BU_:  Airbag BAP_Tester ICAS1_Gateway ICAS1_KommunikationsServer LE1 LE2 Motor_BEV Schaltbetaetigung

BU_:  Airbag BAP_Tester ICAS1_Gateway ICAS1_KommunikationsServer LE1 LE2 Motor_BEV Schaltbetaetigung

BO_ 2463978709 OCC_02: 32 ICAS1_Gateway
 SG_ OCC_CP_Tastgrad_A  : 12|10@1+ (0.100000,0.000000) [0.000000|100.000000] "Unit_PerCent" Vector__XXX
 SG_ OCC_CP_Tastgrad_B  : 22|10@1+ (0.100000,0.000000) [0.000000|100.000000] "Unit_PerCent" Vector__XXX
 SG_ OCC_CP_Frequenz_A  : 32|8@1+ (1.000000,880.000000) [880.000000|1132.000000] "Unit_Hertz" Vector__XXX
 SG_ OCC_CP_Frequenz_B  : 40|8@1+ (1.000000,880.000000) [880.000000|1132.000000] "Unit_Hertz" Vector__XXX
 SG_ OCC_CP_Spannung_A  : 48|9@1+ (0.100000,-25.000000) [-25.000000|25.900000] "Unit_Volt" Vector__XXX
 SG_ OCC_CP_Spannung_B  : 57|9@1+ (0.100000,-25.000000) [-25.000000|25.900000] "Unit_Volt" Vector__XXX
 SG_ OCC_CP_Fehlerstatus_A  : 66|3@1+ (1.000000,0.000000) [0.000000|7.000000] "" Vector__XXX
 SG_ OCC_CP_Fehlerstatus_B  : 69|3@1+ (1.000000,0.000000) [0.000000|7.000000] "" Vector__XXX
 SG_ OCC_Temp_Ladedose_A_AC  : 72|8@1+ (1.000000,-40.000000) [-40.000000|213.000000] "Unit_DegreCelsi" Vector__XXX
 SG_ OCC_Temp_Ladedose_A_DC_minus  : 80|8@1+ (1.000000,-40.000000) [-40.000000|213.000000] "Unit_DegreCelsi" Vector__XXX
 SG_ OCC_Temp_Ladedose_A_DC_plus  : 88|8@1+ (1.000000,-40.000000) [-40.000000|213.000000] "Unit_DegreCelsi" Vector__XXX
 SG_ OCC_U_istAC_Netz_L1  : 96|9@1+ (1.000000,0.000000) [0.000000|509.000000] "Unit_Volt" Vector__XXX
 SG_ OCC_U_istAC_Netz_L2  : 105|9@1+ (1.000000,0.000000) [0.000000|509.000000] "Unit_Volt" Vector__XXX
 SG_ OCC_U_istAC_Netz_L3  : 114|9@1+ (1.000000,0.000000) [0.000000|508.000000] "Unit_Volt" Vector__XXX
 SG_ OCC_StatusVerEntriegelungAktor_A  : 123|3@1+ (1.000000,0.000000) [0.000000|7.000000] "" Vector__XXX
 SG_ OCC_SteckerEntriegelung_Verbot_A  : 126|2@1+ (1.000000,0.000000) [0.000000|3.000000] "" Vector__XXX
 SG_ OCC_StatusVerEntriegelungAktor_B  : 128|3@1+ (1.000000,0.000000) [0.000000|7.000000] "" Vector__XXX
 SG_ OCC_SteckerEntriegelung_Verbot_B  : 131|2@1+ (1.000000,0.000000) [0.000000|3.000000] "" Vector__XXX
 SG_ OCC_Verriegelung_Status_A  : 133|3@1+ (1.000000,0.000000) [0.000000|7.000000] "" Vector__XXX
 SG_ OCC_Verriegelung_Status_B  : 136|3@1+ (1.000000,0.000000) [0.000000|7.000000] "" Vector__XXX
 SG_ OCC_RtmWarnLadeKommunikation  : 139|3@1+ (1.000000,0.000000) [0.000000|7.000000] "" Vector__XXX
 SG_ OCC_Ist_Wirkungsgrad  : 145|7@1+ (1.000000,0.000000) [0.000000|100.000000] "Unit_PerCent" Vector__XXX
 SG_ OCC_PP_Max_Strom_A  : 152|4@1+ (1.000000,0.000000) [0.000000|15.000000] "" Vector__XXX
 SG_ OCC_PP_Max_Strom_B  : 156|4@1+ (1.000000,0.000000) [0.000000|15.000000] "" Vector__XXX
 SG_ OCC_DC_MaxStrom  : 160|11@1+ (0.100000,0.000000) [0.000000|204.500000] "Unit_Amper" Vector__XXX
 SG_ OCC_Derating_Temperatur  : 171|1@1+ (1.000000,0.000000) [0.000000|1.000000] "" Vector__XXX
 SG_ OCC_Fehlerzustand  : 172|1@1+ (1.000000,0.000000) [0.000000|1.000000] "" Vector__XXX
 SG_ OCC_Ladest_Entriegelungs_Verbot  : 173|3@1+ (1.000000,0.000000) [0.000000|7.000000] "" Vector__XXX
 SG_ OCC_Netzfrequenz_EVU  : 176|9@1+ (0.100000,40.000000) [40.000000|80.000000] "Unit_Hertz" Vector__XXX
 SG_ OCC_Warnzustand  : 185|1@1+ (1.000000,0.000000) [0.000000|1.000000] "" Vector__XXX
 SG_ OCC_Kuehltemperatur  : 192|8@1+ (1.000000,-40.000000) [-40.000000|213.000000] "Unit_DegreCelsi" Motor_BEV
 SG_ OCC_PP_Fehlerstatus_A  : 200|4@1+ (1.000000,0.000000) [0.000000|15.000000] "" Vector__XXX
 SG_ OCC_PP_Fehlerstatus_B  : 204|4@1+ (1.000000,0.000000) [0.000000|15.000000] "" Vector__XXX

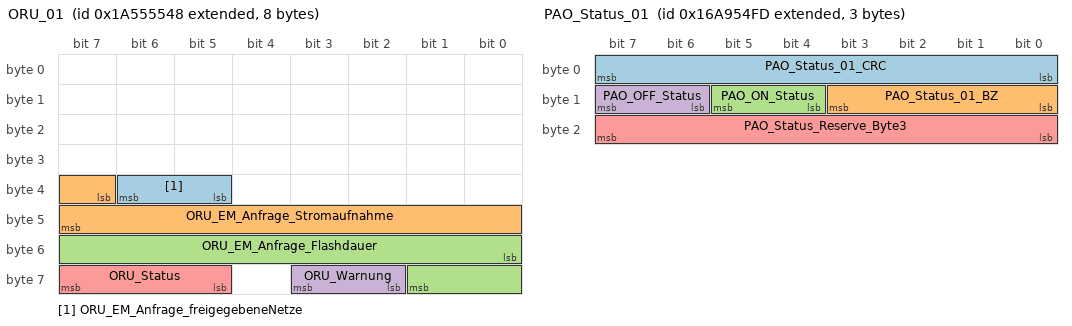
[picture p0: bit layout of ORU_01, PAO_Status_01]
BO_ 2589283656 ORU_01: 8 ICAS1_Gateway
 SG_ ORU_EM_Anfrage_freigegebeneNetze  : 37|2@1+ (1.000000,0.000000) [0.000000|3.000000] "" Vector__XXX
 SG_ ORU_EM_Anfrage_Stromaufnahme  : 39|9@1+ (0.100000,0.000000) [0.000000|51.100000] "Unit_Amper" Vector__XXX
 SG_ ORU_EM_Anfrage_Flashdauer  : 48|10@1+ (10.000000,0.000000) [0.000000|10230.000000] "Unit_Secon" Vector__XXX
 SG_ ORU_Warnung  : 58|2@1+ (1.000000,0.000000) [0.000000|3.000000] "" Vector__XXX
 SG_ ORU_Status  : 61|3@1+ (1.000000,0.000000) [0.000000|7.000000] "" Airbag LE1 LE2 Motor_BEV

BO_ 2527679741 PAO_Status_01: 3 ICAS1_Gateway
 SG_ PAO_Status_01_CRC  : 0|8@1+ (1.000000,0.000000) [0.000000|255.000000] "" Airbag
 SG_ PAO_Status_01_BZ  : 8|4@1+ (1.000000,0.000000) [0.000000|15.000000] "" Airbag
 SG_ PAO_ON_Status  : 12|2@1+ (1.000000,0.000000) [0.000000|3.000000] "" Airbag
 SG_ PAO_OFF_Status  : 14|2@1+ (1.000000,0.000000) [0.000000|3.000000] "" Airbag
 SG_ PAO_Status_Reserve_Byte3  : 16|8@1+ (1.000000,0.000000) [0.000000|255.000000] "" Vector__XXX

BO_ 518 Parken_01: 24 ICAS1_Gateway
 SG_ Parken_BKD_Anf  : 12|4@1+ (0.100000,0.000000) [0.000000|1.300000] "Unit_Secon" Vector__XXX
 SG_ Parken_Verz_Anf  : 16|7@1+ (0.100000,-12.600000) [-12.600000|-0.100000] "Unit_MeterPerSeconSquar" Vector__XXX
 SG_ Parken_Prefill_Anf  : 23|1@1+ (1.000000,0.000000) [0.000000|1.000000] "" Vector__XXX
 SG_ Parken_Warnruck_Anf  : 24|2@1+ (1.000000,0.000000) [0.000000|3.000000] "" Vector__XXX
 SG_ Parken_Verz_Anf_ASIL  : 26|2@1+ (1.000000,0.000000) [0.000000|3.000000] "" Vector__XXX
 SG_ Parken_Warnruckeln_Anf  : 28|2@1+ (1.000000,0.000000) [0.000000|3.000000] "" Vector__XXX
 SG_ Parken_beibehalten  : 30|2@1+ (1.000000,0.000000) [0.000000|3.000000] "" Vector__XXX
 SG_ Parken_Anforderung_HMS  : 32|3@1+ (1.000000,0.000000) [0.000000|7.000000] "" Vector__XXX
 SG_ Parken_Notstopp_Anf  : 40|2@1+ (1.000000,0.000000) [0.000000|3.000000] "" Vector__XXX
 SG_ Parken_Anhalteweg_Anf  : 42|10@1+ (0.010000,0.000000) [0.000000|10.210000] "Unit_Meter" Vector__XXX
 SG_ Parken_aktives_System  : 52|4@1+ (1.000000,0.000000) [0.000000|15.000000] "" Motor_BEV
 SG_ Parken_max_Beschleunigung  : 56|7@1+ (0.100000,-6.000000) [-5.900000|6.100000] "Unit_MeterPerSeconSquar" Motor_BEV
 SG_ Parken_Blinker_li_Anf  : 63|1@1+ (1.000000,0.000000) [0.000000|1.000000] "" Vector__XXX
 SG_ Parken_QFK_KruemmSoll  : 64|15@1+ (0.000007,0.000000) [0.000000|0.219539] "Unit_MeterInver" Vector__XXX
 SG_ Parken_QFK_KruemmSoll_VZ  : 79|1@1+ (1.000000,0.000000) [0.000000|1.000000] "" Vector__XXX
 SG_ Parken_QFK_Spuerb  : 80|8@1+ (0.400000,0.000000) [0.000000|100.000000] "Unit_PerCent" Vector__XXX
 SG_ Parken_QFK_AnfStat  : 88|4@1+ (1.000000,0.000000) [0.000000|15.000000] "" Vector__XXX
 SG_ Parken_QFK_Signal1  : 92|10@1+ (1.000000,0.000000) [0.000000|1023.000000] "" Vector__XXX
 SG_ Parken_QFK_Art1  : 102|3@1+ (1.000000,0.000000) [0.000000|7.000000] "" Vector__XXX
 SG_ Parken_QFK_Art2  : 105|3@1+ (1.000000,0.000000) [0.000000|7.000000] "" Vector__XXX
 SG_ Parken_QFK_Signal2  : 108|10@1+ (1.000000,0.000000) [0.000000|1023.000000] "" Vector__XXX
 SG_ Parken_Sollbeschleunigung  : 118|9@1+ (0.010000,-4.110000) [-4.100000|1.000000] "Unit_MeterPerSeconSquar" Motor_BEV
 SG_ Parken_Blinker_re_Anf  : 127|1@1+ (1.000000,0.000000) [0.000000|1.000000] "" Vector__XXX
 SG_ Parken_Status_IPA_TSK  : 128|4@1+ (1.000000,0.000000) [0.000000|15.000000] "" Motor_BEV
 SG_ Parken_erhoehtes_Moment  : 132|4@1+ (1.000000,0.000000) [0.000000|15.000000] "" Motor_BEV
 SG_ Parken_max_Geschwindigkeit  : 136|8@1+ (0.100000,0.000000) [0.100000|25.000000] "Unit_KiloMeterPerHour" Motor_BEV
 SG_ Parken_Soll_Anhalteweg_Anf  : 144|10@1+ (0.010000,0.000000) [0.000000|10.210000] "Unit_Meter" Vector__XXX
 SG_ Parken_Fahrstufenwunsch  : 154|3@1+ (1.000000,0.000000) [0.000000|7.000000] "" Motor_BEV
 SG_ IPA_TPA_Remote  : 157|2@1+ (1.000000,0.000000) [0.000000|3.000000] "" Vector__XXX
 SG_ IPA_TPA_Remote_Anf  : 159|1@1+ (1.000000,0.000000) [0.000000|1.000000] "" Vector__XXX
 SG_ IPA_TPA_Fehler  : 160|4@1+ (1.000000,0.000000) [0.000000|15.000000] "" Vector__XXX
 SG_ IPA_TPA_Abbruch  : 164|4@1+ (1.000000,0.000000) [0.000000|15.000000] "" Vector__XXX
 SG_ IPA_TPA_Status  : 168|4@1+ (1.000000,0.000000) [0.000000|15.000000] "" Vector__XXX

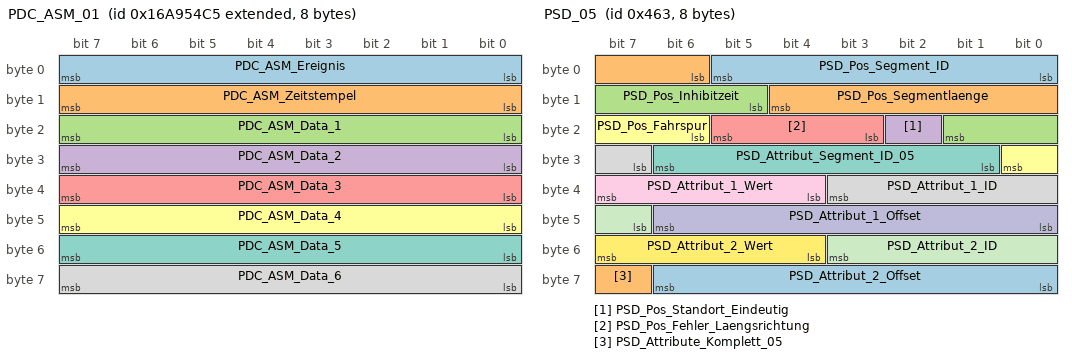
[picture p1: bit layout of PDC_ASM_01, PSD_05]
BO_ 2527679685 PDC_ASM_01: 8 ICAS1_Gateway
 SG_ PDC_ASM_Ereignis  : 0|8@1+ (1.000000,0.000000) [1.000000|254.000000] "" Airbag
 SG_ PDC_ASM_Zeitstempel  : 8|8@1+ (0.080000,0.000000) [0.000000|20.320000] "Unit_Secon" Airbag
 SG_ PDC_ASM_Data_1  : 16|8@1+ (1.000000,0.000000) [0.000000|255.000000] "" Airbag
 SG_ PDC_ASM_Data_2  : 24|8@1+ (1.000000,0.000000) [0.000000|255.000000] "" Airbag
 SG_ PDC_ASM_Data_3  : 32|8@1+ (1.000000,0.000000) [0.000000|255.000000] "" Airbag
 SG_ PDC_ASM_Data_4  : 40|8@1+ (1.000000,0.000000) [0.000000|255.000000] "" Airbag
 SG_ PDC_ASM_Data_5  : 48|8@1+ (1.000000,0.000000) [0.000000|255.000000] "" Airbag
 SG_ PDC_ASM_Data_6  : 56|8@1+ (1.000000,0.000000) [0.000000|255.000000] "" Airbag

BO_ 319 PreCrash_02: 8 Airbag
 SG_ PreCrash_Charisma_FahrPr  : 12|4@1+ (1.000000,0.000000) [0.000000|15.000000] "" ICAS1_Gateway
 SG_ PreCrash_Charisma_Status  : 16|2@1+ (1.000000,0.000000) [0.000000|3.000000] "" ICAS1_Gateway
 SG_ PreCrash_Schiebedach_schliessen  : 18|1@1+ (1.000000,0.000000) [0.000000|1.000000] "" ICAS1_Gateway
 SG_ PreCrash_Fenster_schliessen  : 19|1@1+ (1.000000,0.000000) [0.000000|1.000000] "" ICAS1_Gateway
 SG_ PreCrash_Blinken  : 20|3@1+ (1.000000,0.000000) [0.000000|7.000000] "" ICAS1_Gateway
 SG_ SC_PreSense_FCWP  : 23|1@1+ (1.000000,0.000000) [0.000000|1.000000] "" ICAS1_Gateway
 SG_ PreCrash_Tueren_Verriegeln  : 24|1@1+ (1.000000,0.000000) [0.000000|1.000000] "" ICAS1_Gateway
 SG_ PreCrash_FS_Laengsverstellung  : 25|1@1+ (1.000000,0.000000) [0.000000|1.000000] "" ICAS1_Gateway
 SG_ PreCrash_Anforderung_AFR  : 26|3@1+ (1.000000,0.000000) [0.000000|7.000000] "" ICAS1_Gateway
 SG_ SC_PreCrash_LED  : 29|2@1+ (1.000000,0.000000) [0.000000|3.000000] "" ICAS1_Gateway
 SG_ PreCrash_FS_Pneumatik_ansteuern  : 31|1@1+ (1.000000,0.000000) [0.000000|1.000000] "" ICAS1_Gateway
 SG_ PreCrash_BFS_Pneumatik_ansteuern  : 32|1@1+ (1.000000,0.000000) [0.000000|1.000000] "" ICAS1_Gateway
 SG_ PreCrash_Fo_Pneumatik_ansteuern  : 33|1@1+ (1.000000,0.000000) [0.000000|1.000000] "" ICAS1_Gateway
 SG_ PreCrash_FS_Sitzlehne_verfahren  : 34|3@1+ (1.000000,0.000000) [0.000000|7.000000] "" ICAS1_Gateway
 SG_ PreCrash_BFS_Sitzlehne_verfahren  : 37|3@1+ (1.000000,0.000000) [0.000000|7.000000] "" ICAS1_Gateway
 SG_ PreCrash_Fo_Sitzlehne_verfahren  : 40|3@1+ (1.000000,0.000000) [0.000000|7.000000] "" ICAS1_Gateway
 SG_ PreCrash_FS_KSV_verfahren  : 43|4@1+ (1.000000,0.000000) [0.000000|15.000000] "" ICAS1_Gateway
 SG_ PreCrash_BFS_KSV_verfahren  : 47|4@1+ (1.000000,0.000000) [0.000000|15.000000] "" ICAS1_Gateway
 SG_ PreCrash_Fo_KSV_verfahren  : 51|4@1+ (1.000000,0.000000) [0.000000|15.000000] "" ICAS1_Gateway
 SG_ PreCrash_BFS_Laengsverstellung  : 55|1@1+ (1.000000,0.000000) [0.000000|1.000000] "" ICAS1_Gateway
 SG_ SC_PreCrash_Warnung  : 56|4@1+ (1.000000,0.000000) [0.000000|15.000000] "" ICAS1_Gateway ICAS1_KommunikationsServer
 SG_ SC_PreCrash_Texte  : 60|4@1+ (1.000000,0.000000) [0.000000|15.000000] "" ICAS1_Gateway ICAS1_KommunikationsServer

BO_ 1122 PSD_04: 8 ICAS1_Gateway
 SG_ PSD_Segment_ID  : 0|6@1+ (1.000000,0.000000) [2.000000|63.000000] "" Motor_BEV
 SG_ PSD_Vorgaenger_Segment_ID  : 6|6@1+ (1.000000,0.000000) [2.000000|63.000000] "" Motor_BEV
 SG_ PSD_Segmentlaenge  : 12|7@1+ (2.000000,0.000000) [0.000000|254.000000] "Unit_Meter" Motor_BEV
 SG_ PSD_Strassenkategorie  : 19|3@1+ (1.000000,0.000000) [0.000000|7.000000] "" Motor_BEV
 SG_ PSD_Endkruemmung  : 22|8@1+ (1.000000,0.000000) [0.000000|254.000000] "Unit_None" Motor_BEV
 SG_ PSD_Endkruemmung_Vorz  : 30|1@1+ (1.000000,0.000000) [0.000000|1.000000] "" Motor_BEV
 SG_ PSD_Idenditaets_ID  : 31|6@1+ (1.000000,0.000000) [2.000000|63.000000] "" Vector__XXX
 SG_ PSD_ADAS_Qualitaet  : 37|1@1+ (1.000000,0.000000) [0.000000|1.000000] "" Motor_BEV
 SG_ PSD_wahrscheinlichster_Pfad  : 38|1@1+ (1.000000,0.000000) [0.000000|1.000000] "" Motor_BEV
 SG_ PSD_Geradester_Pfad  : 39|1@1+ (1.000000,0.000000) [0.000000|1.000000] "" Motor_BEV
 SG_ PSD_Fahrspuren_Anzahl  : 40|3@1+ (1.000000,0.000000) [0.000000|7.000000] "" Motor_BEV
 SG_ PSD_Bebauung  : 43|1@1+ (1.000000,0.000000) [0.000000|1.000000] "" Motor_BEV
 SG_ PSD_Segment_Komplett  : 44|1@1+ (1.000000,0.000000) [0.000000|1.000000] "" Motor_BEV
 SG_ PSD_Rampe  : 45|2@1+ (1.000000,0.000000) [0.000000|3.000000] "" Motor_BEV
 SG_ PSD_Anfangskruemmung  : 47|8@1+ (1.000000,0.000000) [0.000000|254.000000] "" Motor_BEV
 SG_ PSD_Anfangskruemmung_Vorz  : 55|1@1+ (1.000000,0.000000) [0.000000|1.000000] "" Motor_BEV
 SG_ PSD_Abzweigerichtung  : 56|1@1+ (1.000000,0.000000) [0.000000|1.000000] "" Motor_BEV
 SG_ PSD_Abzweigewinkel  : 57|7@1+ (1.417323,0.000000) [0.000000|180.000021] "" Motor_BEV

BO_ 1123 PSD_05: 8 ICAS1_Gateway
 SG_ PSD_Pos_Segment_ID  : 0|6@1+ (1.000000,0.000000) [2.000000|63.000000] "" Motor_BEV
 SG_ PSD_Pos_Segmentlaenge  : 6|7@1+ (2.000000,0.000000) [0.000000|254.000000] "Unit_Meter" Motor_BEV
 SG_ PSD_Pos_Inhibitzeit  : 13|5@1+ (10.000000,0.000000) [0.000000|310.000000] "Unit_MilliSecon" Motor_BEV
 SG_ PSD_Pos_Standort_Eindeutig  : 18|1@1+ (1.000000,0.000000) [0.000000|1.000000] "" Motor_BEV
 SG_ PSD_Pos_Fehler_Laengsrichtung  : 19|3@1+ (1.000000,0.000000) [0.000000|7.000000] "" Motor_BEV
 SG_ PSD_Pos_Fahrspur  : 22|3@1+ (1.000000,0.000000) [0.000000|7.000000] "" Motor_BEV
 SG_ PSD_Attribut_Segment_ID_05  : 25|6@1+ (1.000000,0.000000) [2.000000|63.000000] "" Motor_BEV
 SG_ PSD_Attribut_1_ID  : 31|5@1+ (1.000000,0.000000) [1.000000|31.000000] "" Motor_BEV
 SG_ PSD_Attribut_1_Wert  : 36|4@1+ (1.000000,0.000000) [0.000000|15.000000] "" Motor_BEV
 SG_ PSD_Attribut_1_Offset  : 40|7@1+ (2.000000,0.000000) [0.000000|254.000000] "Unit_Meter" Motor_BEV
 SG_ PSD_Attribut_2_ID  : 47|5@1+ (1.000000,0.000000) [1.000000|31.000000] "" Motor_BEV
 SG_ PSD_Attribut_2_Wert  : 52|4@1+ (1.000000,0.000000) [0.000000|15.000000] "" Motor_BEV
 SG_ PSD_Attribut_2_Offset  : 56|7@1+ (2.000000,0.000000) [0.000000|254.000000] "Unit_Meter" Motor_BEV
 SG_ PSD_Attribute_Komplett_05  : 63|1@1+ (1.000000,0.000000) [0.000000|1.000000] "" Motor_BEV

BO_ 1124 PSD_06: 8 ICAS1_Gateway
 SG_ PSD_06_Mux M : 0|3@1+ (1.000000,0.000000) [0.000000|7.000000] "" Motor_BEV
 SG_ PSD_Sys_Segment_ID m0 : 3|6@1+ (1.000000,0.000000) [2.000000|63.000000] "" Motor_BEV
 SG_ PSD_Attribut_Segment_ID m1 : 3|6@1+ (1.000000,0.000000) [2.000000|63.000000] "" Motor_BEV
 SG_ PSD_Ges_Segment_ID m2 : 3|6@1+ (1.000000,0.000000) [2.000000|63.000000] "" Motor_BEV
 SG_ PSD_Baum_Laenge_VZ m3 : 3|1@1+ (1.000000,0.000000) [0.000000|1.000000] "" Motor_BEV
 SG_ PSD_Steigung_1_Segment_ID m4 : 3|6@1+ (1.000000,0.000000) [2.000000|63.000000] "" Motor_BEV
 SG_ PSD_Baum_Laenge m3 : 4|25@1+ (0.000010,0.000000) [0.000000|180.000000] "Unit_DegreOfArc" Motor_BEV
 SG_ PSD_Sys_Laendercode m0 : 9|8@1+ (1.000000,0.000000) [0.000000|255.000000] "" Motor_BEV
 SG_ PSD_Attribut_3_ID m1 : 9|5@1+ (1.000000,0.000000) [1.000000|31.000000] "" Motor_BEV
 SG_ PSD_Ges_Offset m2 : 9|7@1+ (2.000000,0.000000) [0.000000|254.000000] "Unit_Meter" Motor_BEV
 SG_ PSD_Steigung_1_A_Steigung m4 : 9|7@1+ (0.120000,0.000000) [0.000000|15.000000] "Unit_PerCent" Motor_BEV
 SG_ PSD_Attribut_3_Offset m1 : 14|7@1+ (2.000000,0.000000) [0.000000|254.000000] "Unit_Meter" Motor_BEV
 SG_ PSD_Ges_Geschwindigkeit m2 : 16|5@1+ (1.000000,0.000000) [0.000000|31.000000] "" Motor_BEV
 SG_ PSD_Steigung_1_A_Vorz m4 : 16|1@1+ (1.000000,0.000000) [0.000000|1.000000] "" Motor_BEV
 SG_ PSD_Sys_Geschwindigkeit_Einheit m0 : 17|1@1+ (1.000000,0.000000) [0.000000|1.000000] "" Motor_BEV
 SG_ PSD_Steigung_1_A_Offset m4 : 17|7@1+ (2.000000,0.000000) [0.000000|254.000000] "Unit_Meter" Motor_BEV
 SG_ PSD_Sys_Verkehrsrichtung m0 : 18|1@1+ (1.000000,0.000000) [0.000000|1.000000] "" Motor_BEV
 SG_ PSD_Sys_Geometrieguete m0 : 19|2@1+ (1.000000,0.000000) [0.000000|3.000000] "" Motor_BEV
 SG_ PSD_Sys_Mapmatchingguete m0 : 21|2@1+ (1.000000,0.000000) [0.000000|3.000000] "" Motor_BEV
 SG_ PSD_Attribut_3_Wert m1 : 21|4@1+ (1.000000,0.000000) [0.000000|15.000000] "" Motor_BEV
 SG_ PSD_Ges_Typ m2 : 21|2@1+ (1.000000,0.000000) [0.000000|3.000000] "" Motor_BEV
 SG_ PSD_Sys_Alter_Karte m0 : 23|3@1+ (1.000000,0.000000) [0.000000|7.000000] "" Motor_BEV
 SG_ PSD_Ges_Spur_Geschw_Begrenzung m2 : 23|6@1+ (1.000000,0.000000) [0.000000|63.000000] "" Motor_BEV
 SG_ PSD_Steigung_1_B_Steigung m4 : 24|7@1+ (0.120000,0.000000) [0.000000|15.000000] "Unit_PerCent" Motor_BEV
 SG_ PSD_Attribut_4_ID m1 : 25|5@1+ (1.000000,0.000000) [1.000000|31.000000] "" Motor_BEV
 SG_ PSD_Sys_Zielfuehrung m0 : 26|1@1+ (1.000000,0.000000) [0.000000|1.000000] "" Motor_BEV
 SG_ PSD_Sys_US_State m0 : 27|6@1+ (1.000000,0.000000) [0.000000|63.000000] "" Motor_BEV
 SG_ PSD_Ges_Geschwindigkeit_Gespann m2 : 29|2@1+ (1.000000,0.000000) [0.000000|3.000000] "" Motor_BEV
 SG_ PSD_Baum_Breite_VZ m3 : 29|1@1+ (1.000000,0.000000) [0.000000|1.000000] "" Motor_BEV
 SG_ PSD_Attribut_4_Wert m1 : 30|4@1+ (1.000000,0.000000) [0.000000|15.000000] "" Motor_BEV
 SG_ PSD_Baum_Breite m3 : 30|24@1+ (0.000010,0.000000) [0.000000|90.000000] "Unit_DegreOfArc" Motor_BEV
 SG_ PSD_Ges_Geschwindigkeit_Witter m2 : 31|2@1+ (1.000000,0.000000) [0.000000|3.000000] "" Motor_BEV
 SG_ PSD_Steigung_1_B_Vorz m4 : 31|1@1+ (1.000000,0.000000) [0.000000|1.000000] "" Motor_BEV
 SG_ PSD_Steigung_1_B_Offset m4 : 32|7@1+ (2.000000,0.000000) [0.000000|254.000000] "Unit_Meter" Motor_BEV
 SG_ PSD_Sys_Quali_Geometrien m0 : 33|3@1+ (1.000000,0.000000) [0.000000|7.000000] "Unit_None" Vector__XXX
 SG_ PSD_Ges_Geschwindigkeit_Tag_Anf m2 : 33|3@1+ (1.000000,0.000000) [0.000000|7.000000] "" Motor_BEV
 SG_ PSD_Attribut_4_Offset m1 : 34|7@1+ (2.000000,0.000000) [0.000000|254.000000] "Unit_Meter" Motor_BEV
 SG_ PSD_Sys_Quali_Ortsinfo m0 : 36|2@1+ (1.000000,0.000000) [0.000000|3.000000] "Unit_None" Vector__XXX
 SG_ PSD_Ges_Geschwindigkeit_Tag_Ende m2 : 36|3@1+ (1.000000,0.000000) [0.000000|7.000000] "" Motor_BEV
 SG_ PSD_Sys_Quali_verfuegbar m0 : 38|1@1+ (1.000000,0.000000) [0.000000|1.000000] "" Vector__XXX
 SG_ PSD_Sys_Zielfuehrung_geaendert m0 : 39|1@1+ (1.000000,0.000000) [0.000000|1.000000] "" Motor_BEV
 SG_ PSD_Ges_Geschwindigkeit_Std_Anf m2 : 39|5@1+ (1.000000,0.000000) [0.000000|24.000000] "Unit_Hours" Motor_BEV
 SG_ PSD_Steigung_1_Attribute_kompl m4 : 39|1@1+ (1.000000,0.000000) [0.000000|1.000000] "" Motor_BEV
 SG_ PSD_Sys_Geometrieguete_erweitert m0 : 40|8@1+ (1.000000,0.000000) [0.000000|255.000000] "" Vector__XXX
 SG_ PSD_Steigung_2_Segment_ID m4 : 40|6@1+ (1.000000,0.000000) [2.000000|63.000000] "" Motor_BEV
 SG_ PSD_Attribut_5_ID m1 : 41|5@1+ (1.000000,0.000000) [1.000000|31.000000] "" Motor_BEV
 SG_ PSD_Ges_Geschwindigkeit_Std_Ende m2 : 44|5@1+ (1.000000,0.000000) [0.000000|24.000000] "Unit_Hours" Motor_BEV
 SG_ PSD_Attribut_5_Offset m1 : 46|7@1+ (2.000000,0.000000) [0.000000|254.000000] "Unit_Meter" Motor_BEV
 SG_ PSD_Steigung_2_Steigung m4 : 46|7@1+ (0.120000,0.000000) [0.000000|15.000000] "Unit_PerCent" Motor_BEV
 SG_ PSD_Sys_Quali_sonstige_Attribute m0 : 48|3@1+ (1.000000,0.000000) [0.000000|7.000000] "Unit_None" Vector__XXX
 SG_ PSD_Ges_Ueberholverbot m2 : 49|2@1+ (1.000000,0.000000) [0.000000|3.000000] "" Vector__XXX
 SG_ PSD_Sys_Quali_Steigungen m0 : 51|3@1+ (1.000000,0.000000) [0.000000|7.000000] "" Vector__XXX
 SG_ PSD_Ges_Wechselverkehrszeichen m2 : 51|3@1+ (1.000000,0.000000) [0.000000|7.000000] "" Vector__XXX
 SG_ PSD_Attribut_5_Wert m1 : 53|4@1+ (1.000000,0.000000) [0.000000|15.000000] "" Motor_BEV
 SG_ PSD_Steigung_2_Vorz m4 : 53|1@1+ (1.000000,0.000000) [0.000000|1.000000] "" Motor_BEV
 SG_ PSD_Sys_Quali_Strassenkennz m0 : 54|3@1+ (1.000000,0.000000) [0.000000|7.000000] "Unit_None" Vector__XXX
 SG_ PSD_Wechselverkehrszeichen_Typ m2 : 54|2@1+ (1.000000,0.000000) [0.000000|3.000000] "" Vector__XXX
 SG_ PSD_Baum_Ausrichtung m3 : 54|10@1+ (0.351562,0.000000) [0.000000|359.648438] "Unit_DegreOfArc" Vector__XXX
 SG_ PSD_Steigung_2_Offset m4 : 54|7@1+ (2.000000,0.000000) [0.000000|254.000000] "Unit_Meter" Motor_BEV
 SG_ PSD_Ges_Gesetzlich_Kategorie m2 : 56|3@1+ (1.000000,0.000000) [0.000000|7.000000] "" Motor_BEV
 SG_ PSD_Sys_Quali_Tempolimits m0 : 57|3@1+ (1.000000,0.000000) [0.000000|7.000000] "Unit_None" Vector__XXX
 SG_ PSD_Attribute_Komplett_06 m1 : 57|1@1+ (1.000000,0.000000) [0.000000|1.000000] "" Motor_BEV
 SG_ PSD_Ges_Gesetzlich_Zusatz m2 : 59|2@1+ (1.000000,0.000000) [0.000000|3.000000] "" Motor_BEV
 SG_ PSD_Sys_Quali_Vorfahrtsregelung m0 : 60|3@1+ (1.000000,0.000000) [0.000000|7.000000] "Unit_None" Vector__XXX
 SG_ PSD_Ges_Verkehrszeichen_Quelle m2 : 61|2@1+ (1.000000,0.000000) [0.000000|3.000000] "" Motor_BEV
 SG_ PSD_Steigung_2_Attribute_kompl m4 : 61|1@1+ (1.000000,0.000000) [0.000000|1.000000] "" Motor_BEV
 SG_ PSD_Ges_Attribute_Komplett m2 : 63|1@1+ (1.000000,0.000000) [0.000000|1.000000] "" Motor_BEV

BO_ 591 RDR1_Objekte_02: 64 ICAS1_Gateway
 SG_ RDR1_relevanter_Fehler  : 12|1@1+ (1.000000,0.000000) [0.000000|1.000000] "" Motor_BEV
 SG_ RDR1_Blindheit_erkannt  : 13|1@1+ (1.000000,0.000000) [0.000000|1.000000] "" Motor_BEV
 SG_ RDR1_relev_Nichtverfuegbarkeit  : 14|1@1+ (1.000000,0.000000) [0.000000|1.000000] "" Motor_BEV
 SG_ RDR1_Obj_01_Nummer  : 16|6@1+ (1.000000,0.000000) [0.000000|63.000000] "" Vector__XXX
 SG_ RDR1_Obj_02_Nummer  : 22|6@1+ (1.000000,0.000000) [0.000000|63.000000] "" Vector__XXX
 SG_ RDR1_Obj_03_Nummer  : 28|6@1+ (1.000000,0.000000) [0.000000|63.000000] "" Vector__XXX
 SG_ RDR1_Obj_04_Nummer  : 34|6@1+ (1.000000,0.000000) [0.000000|63.000000] "" Vector__XXX
 SG_ RDR1_Obj_05_Nummer  : 40|6@1+ (1.000000,0.000000) [0.000000|63.000000] "" Vector__XXX
 SG_ RDR1_Obj_06_Nummer  : 46|6@1+ (1.000000,0.000000) [0.000000|63.000000] "" Vector__XXX
 SG_ RDR1_Verkehrssinn  : 52|2@1+ (1.000000,0.000000) [0.000000|3.000000] "" Vector__XXX
 SG_ RDR1_Objekte_02_Datenalter  : 54|10@1+ (0.000977,0.000000) [0.000000|0.998047] "Unit_Secon" Vector__XXX
 SG_ RDR1_Obj_01_dx_v  : 64|12@1+ (0.062500,0.000000) [0.000000|255.937500] "Unit_Meter" Motor_BEV
 SG_ RDR1_Obj_01_dy_v  : 76|10@1+ (0.062500,-32.000000) [-32.000000|31.937500] "Unit_Meter" Motor_BEV
 SG_ RDR1_Obj_01_vx_v  : 86|10@1+ (0.250000,-128.000000) [-128.000000|127.750000] "Unit_MeterPerSecon" Motor_BEV
 SG_ RDR1_Obj_02_dx_v  : 96|12@1+ (0.062500,0.000000) [0.000000|255.937500] "Unit_Meter" Vector__XXX
 SG_ RDR1_Obj_02_dy_v  : 108|10@1+ (0.062500,-32.000000) [-32.000000|31.937500] "Unit_Meter" Vector__XXX
 SG_ RDR1_Obj_02_vx_v  : 118|10@1+ (0.250000,-128.000000) [-128.000000|127.750000] "Unit_MeterPerSecon" Vector__XXX
 SG_ RDR1_Obj_03_dx_v  : 128|12@1+ (0.062500,0.000000) [0.000000|255.937500] "Unit_Meter" Vector__XXX
 SG_ RDR1_Obj_03_dy_v  : 140|10@1+ (0.062500,-32.000000) [-32.000000|31.937500] "Unit_Meter" Vector__XXX
 SG_ RDR1_Obj_03_vx_v  : 150|10@1+ (0.250000,-128.000000) [-128.000000|127.750000] "Unit_MeterPerSecon" Vector__XXX
 SG_ RDR1_Obj_04_dx_v  : 160|12@1+ (0.062500,0.000000) [0.000000|255.937500] "Unit_Meter" Motor_BEV
 SG_ RDR1_Obj_04_dy_v  : 172|10@1+ (0.062500,-32.000000) [-32.000000|31.937500] "Unit_Meter" Vector__XXX
 SG_ RDR1_Obj_04_vx_v  : 182|10@1+ (0.250000,-128.000000) [-128.000000|127.750000] "Unit_MeterPerSecon" Motor_BEV
 SG_ RDR1_Obj_05_dx_v  : 192|12@1+ (0.062500,0.000000) [0.000000|255.937500] "Unit_Meter" Vector__XXX
 SG_ RDR1_Obj_05_dy_v  : 204|10@1+ (0.062500,-32.000000) [-32.000000|31.937500] "Unit_Meter" Vector__XXX
 SG_ RDR1_Obj_05_vx_v  : 214|10@1+ (0.250000,-128.000000) [-128.000000|127.750000] "Unit_MeterPerSecon" Vector__XXX
 SG_ RDR1_Obj_06_dx_v  : 224|12@1+ (0.062500,0.000000) [0.000000|255.937500] "Unit_Meter" Vector__XXX
 SG_ RDR1_Obj_06_dy_v  : 236|10@1+ (0.062500,-32.000000) [-32.000000|31.937500] "Unit_Meter" Vector__XXX
 SG_ RDR1_Obj_06_vx_v  : 246|10@1+ (0.250000,-128.000000) [-128.000000|127.750000] "Unit_MeterPerSecon" Vector__XXX
 SG_ RDR1_Obj_01_ax_v  : 256|8@1+ (0.125000,-16.000000) [-16.000000|15.750000] "Unit_MeterPerSeconSquar" Motor_BEV
 SG_ RDR1_Obj_01_ax_StdA  : 264|6@1+ (0.125000,0.000000) [0.000000|7.750000] "Unit_MeterPerSeconSquar" Motor_BEV
 SG_ RDR1_Obj_01_vx_StdA  : 270|7@1+ (0.031250,0.000000) [0.000000|3.937500] "Unit_MeterPerSecon" Motor_BEV
 SG_ RDR1_Obj_01_dx_StdA  : 277|7@1+ (0.050000,0.000000) [0.000000|6.300000] "Unit_Meter" Motor_BEV
 SG_ RDR1_Obj_01_dy_StdA  : 284|7@1+ (0.062500,0.000000) [0.000000|7.875000] "Unit_Meter" Motor_BEV

BO_ 2033 Request_Airbag_Deployment: 8 ICAS1_Gateway
 SG_ Request_Airbag_Deployment  : 0|64@1+ (1.000000,0.000000) [0.000000|18446744073709551616.000000] "" Airbag

BO_ 2041 Response_Airbag_Deployment: 8 Airbag
 SG_ Response_Airbag_Deployment  : 0|64@1+ (1.000000,0.000000) [0.000000|18446744073709551616.000000] "" ICAS1_Gateway

BU_:  Airbag BAP_Tester ICAS1_Gateway ICAS1_KommunikationsServer LE1 LE2 Motor_BEV Schaltbetaetigung

BO_ 2463978709 OCC_02: 32 ICAS1_Gateway
 SG_ OCC_CP_Tastgrad_A  : 12|10@1+ (0.100000,0.000000) [0.000000|100.000000] "Unit_PerCent" Vector__XXX
 SG_ OCC_CP_Tastgrad_B  : 22|10@1+ (0.100000,0.000000) [0.000000|100.000000] "Unit_PerCent" Vector__XXX
 SG_ OCC_CP_Frequenz_A  : 32|8@1+ (1.000000,880.000000) [880.000000|1132.000000] "Unit_Hertz" Vector__XXX
 SG_ OCC_CP_Frequenz_B  : 40|8@1+ (1.000000,880.000000) [880.000000|1132.000000] "Unit_Hertz" Vector__XXX
 SG_ OCC_CP_Spannung_A  : 48|9@1+ (0.100000,-25.000000) [-25.000000|25.900000] "Unit_Volt" Vector__XXX
 SG_ OCC_CP_Spannung_B  : 57|9@1+ (0.100000,-25.000000) [-25.000000|25.900000] "Unit_Volt" Vector__XXX
 SG_ OCC_CP_Fehlerstatus_A  : 66|3@1+ (1.000000,0.000000) [0.000000|7.000000] "" Vector__XXX
 SG_ OCC_CP_Fehlerstatus_B  : 69|3@1+ (1.000000,0.000000) [0.000000|7.000000] "" Vector__XXX
 SG_ OCC_Temp_Ladedose_A_AC  : 72|8@1+ (1.000000,-40.000000) [-40.000000|213.000000] "Unit_DegreCelsi" Vector__XXX
 SG_ OCC_Temp_Ladedose_A_DC_minus  : 80|8@1+ (1.000000,-40.000000) [-40.000000|213.000000] "Unit_DegreCelsi" Vector__XXX
 SG_ OCC_Temp_Ladedose_A_DC_plus  : 88|8@1+ (1.000000,-40.000000) [-40.000000|213.000000] "Unit_DegreCelsi" Vector__XXX
 SG_ OCC_U_istAC_Netz_L1  : 96|9@1+ (1.000000,0.000000) [0.000000|509.000000] "Unit_Volt" Vector__XXX
 SG_ OCC_U_istAC_Netz_L2  : 105|9@1+ (1.000000,0.000000) [0.000000|509.000000] "Unit_Volt" Vector__XXX
 SG_ OCC_U_istAC_Netz_L3  : 114|9@1+ (1.000000,0.000000) [0.000000|508.000000] "Unit_Volt" Vector__XXX
 SG_ OCC_StatusVerEntriegelungAktor_A  : 123|3@1+ (1.000000,0.000000) [0.000000|7.000000] "" Vector__XXX
 SG_ OCC_SteckerEntriegelung_Verbot_A  : 126|2@1+ (1.000000,0.000000) [0.000000|3.000000] "" Vector__XXX
 SG_ OCC_StatusVerEntriegelungAktor_B  : 128|3@1+ (1.000000,0.000000) [0.000000|7.000000] "" Vector__XXX
 SG_ OCC_SteckerEntriegelung_Verbot_B  : 131|2@1+ (1.000000,0.000000) [0.000000|3.000000] "" Vector__XXX
 SG_ OCC_Verriegelung_Status_A  : 133|3@1+ (1.000000,0.000000) [0.000000|7.000000] "" Vector__XXX
 SG_ OCC_Verriegelung_Status_B  : 136|3@1+ (1.000000,0.000000) [0.000000|7.000000] "" Vector__XXX
 SG_ OCC_RtmWarnLadeKommunikation  : 139|3@1+ (1.000000,0.000000) [0.000000|7.000000] "" Vector__XXX
 SG_ OCC_Ist_Wirkungsgrad  : 145|7@1+ (1.000000,0.000000) [0.000000|100.000000] "Unit_PerCent" Vector__XXX
 SG_ OCC_PP_Max_Strom_A  : 152|4@1+ (1.000000,0.000000) [0.000000|15.000000] "" Vector__XXX
 SG_ OCC_PP_Max_Strom_B  : 156|4@1+ (1.000000,0.000000) [0.000000|15.000000] "" Vector__XXX
 SG_ OCC_DC_MaxStrom  : 160|11@1+ (0.100000,0.000000) [0.000000|204.500000] "Unit_Amper" Vector__XXX
 SG_ OCC_Derating_Temperatur  : 171|1@1+ (1.000000,0.000000) [0.000000|1.000000] "" Vector__XXX
 SG_ OCC_Fehlerzustand  : 172|1@1+ (1.000000,0.000000) [0.000000|1.000000] "" Vector__XXX
 SG_ OCC_Ladest_Entriegelungs_Verbot  : 173|3@1+ (1.000000,0.000000) [0.000000|7.000000] "" Vector__XXX
 SG_ OCC_Netzfrequenz_EVU  : 176|9@1+ (0.100000,40.000000) [40.000000|80.000000] "Unit_Hertz" Vector__XXX
 SG_ OCC_Warnzustand  : 185|1@1+ (1.000000,0.000000) [0.000000|1.000000] "" Vector__XXX
 SG_ OCC_Kuehltemperatur  : 192|8@1+ (1.000000,-40.000000) [-40.000000|213.000000] "Unit_DegreCelsi" Motor_BEV
 SG_ OCC_PP_Fehlerstatus_A  : 200|4@1+ (1.000000,0.000000) [0.000000|15.000000] "" Vector__XXX
 SG_ OCC_PP_Fehlerstatus_B  : 204|4@1+ (1.000000,0.000000) [0.000000|15.000000] "" Vector__XXX

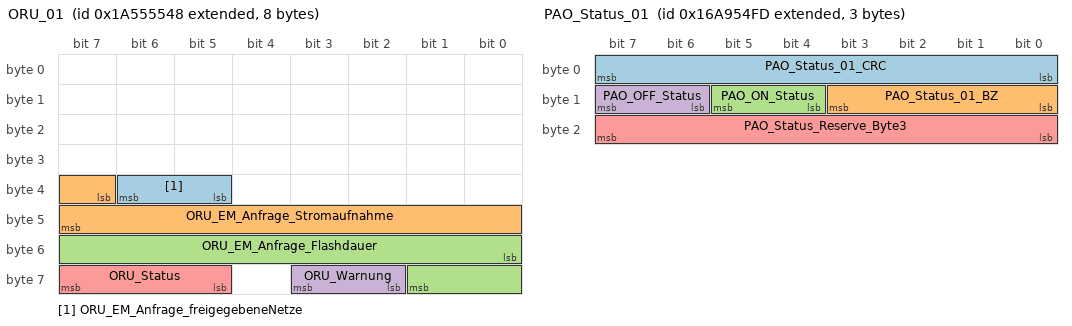
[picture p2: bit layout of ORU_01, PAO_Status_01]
BO_ 2589283656 ORU_01: 8 ICAS1_Gateway
 SG_ ORU_EM_Anfrage_freigegebeneNetze  : 37|2@1+ (1.000000,0.000000) [0.000000|3.000000] "" Vector__XXX
 SG_ ORU_EM_Anfrage_Stromaufnahme  : 39|9@1+ (0.100000,0.000000) [0.000000|51.100000] "Unit_Amper" Vector__XXX
 SG_ ORU_EM_Anfrage_Flashdauer  : 48|10@1+ (10.000000,0.000000) [0.000000|10230.000000] "Unit_Secon" Vector__XXX
 SG_ ORU_Warnung  : 58|2@1+ (1.000000,0.000000) [0.000000|3.000000] "" Vector__XXX
 SG_ ORU_Status  : 61|3@1+ (1.000000,0.000000) [0.000000|7.000000] "" Airbag LE1 LE2 Motor_BEV

BO_ 2527679741 PAO_Status_01: 3 ICAS1_Gateway
 SG_ PAO_Status_01_CRC  : 0|8@1+ (1.000000,0.000000) [0.000000|255.000000] "" Airbag
 SG_ PAO_Status_01_BZ  : 8|4@1+ (1.000000,0.000000) [0.000000|15.000000] "" Airbag
 SG_ PAO_ON_Status  : 12|2@1+ (1.000000,0.000000) [0.000000|3.000000] "" Airbag
 SG_ PAO_OFF_Status  : 14|2@1+ (1.000000,0.000000) [0.000000|3.000000] "" Airbag
 SG_ PAO_Status_Reserve_Byte3  : 16|8@1+ (1.000000,0.000000) [0.000000|255.000000] "" Vector__XXX

BO_ 518 Parken_01: 24 ICAS1_Gateway
 SG_ Parken_BKD_Anf  : 12|4@1+ (0.100000,0.000000) [0.000000|1.300000] "Unit_Secon" Vector__XXX
 SG_ Parken_Verz_Anf  : 16|7@1+ (0.100000,-12.600000) [-12.600000|-0.100000] "Unit_MeterPerSeconSquar" Vector__XXX
 SG_ Parken_Prefill_Anf  : 23|1@1+ (1.000000,0.000000) [0.000000|1.000000] "" Vector__XXX
 SG_ Parken_Warnruck_Anf  : 24|2@1+ (1.000000,0.000000) [0.000000|3.000000] "" Vector__XXX
 SG_ Parken_Verz_Anf_ASIL  : 26|2@1+ (1.000000,0.000000) [0.000000|3.000000] "" Vector__XXX
 SG_ Parken_Warnruckeln_Anf  : 28|2@1+ (1.000000,0.000000) [0.000000|3.000000] "" Vector__XXX
 SG_ Parken_beibehalten  : 30|2@1+ (1.000000,0.000000) [0.000000|3.000000] "" Vector__XXX
 SG_ Parken_Anforderung_HMS  : 32|3@1+ (1.000000,0.000000) [0.000000|7.000000] "" Vector__XXX
 SG_ Parken_Notstopp_Anf  : 40|2@1+ (1.000000,0.000000) [0.000000|3.000000] "" Vector__XXX
 SG_ Parken_Anhalteweg_Anf  : 42|10@1+ (0.010000,0.000000) [0.000000|10.210000] "Unit_Meter" Vector__XXX
 SG_ Parken_aktives_System  : 52|4@1+ (1.000000,0.000000) [0.000000|15.000000] "" Motor_BEV
 SG_ Parken_max_Beschleunigung  : 56|7@1+ (0.100000,-6.000000) [-5.900000|6.100000] "Unit_MeterPerSeconSquar" Motor_BEV
 SG_ Parken_Blinker_li_Anf  : 63|1@1+ (1.000000,0.000000) [0.000000|1.000000] "" Vector__XXX
 SG_ Parken_QFK_KruemmSoll  : 64|15@1+ (0.000007,0.000000) [0.000000|0.219539] "Unit_MeterInver" Vector__XXX
 SG_ Parken_QFK_KruemmSoll_VZ  : 79|1@1+ (1.000000,0.000000) [0.000000|1.000000] "" Vector__XXX
 SG_ Parken_QFK_Spuerb  : 80|8@1+ (0.400000,0.000000) [0.000000|100.000000] "Unit_PerCent" Vector__XXX
 SG_ Parken_QFK_AnfStat  : 88|4@1+ (1.000000,0.000000) [0.000000|15.000000] "" Vector__XXX
 SG_ Parken_QFK_Signal1  : 92|10@1+ (1.000000,0.000000) [0.000000|1023.000000] "" Vector__XXX
 SG_ Parken_QFK_Art1  : 102|3@1+ (1.000000,0.000000) [0.000000|7.000000] "" Vector__XXX
 SG_ Parken_QFK_Art2  : 105|3@1+ (1.000000,0.000000) [0.000000|7.000000] "" Vector__XXX
 SG_ Parken_QFK_Signal2  : 108|10@1+ (1.000000,0.000000) [0.000000|1023.000000] "" Vector__XXX
 SG_ Parken_Sollbeschleunigung  : 118|9@1+ (0.010000,-4.110000) [-4.100000|1.000000] "Unit_MeterPerSeconSquar" Motor_BEV
 SG_ Parken_Blinker_re_Anf  : 127|1@1+ (1.000000,0.000000) [0.000000|1.000000] "" Vector__XXX
 SG_ Parken_Status_IPA_TSK  : 128|4@1+ (1.000000,0.000000) [0.000000|15.000000] "" Motor_BEV
 SG_ Parken_erhoehtes_Moment  : 132|4@1+ (1.000000,0.000000) [0.000000|15.000000] "" Motor_BEV
 SG_ Parken_max_Geschwindigkeit  : 136|8@1+ (0.100000,0.000000) [0.100000|25.000000] "Unit_KiloMeterPerHour" Motor_BEV
 SG_ Parken_Soll_Anhalteweg_Anf  : 144|10@1+ (0.010000,0.000000) [0.000000|10.210000] "Unit_Meter" Vector__XXX
 SG_ Parken_Fahrstufenwunsch  : 154|3@1+ (1.000000,0.000000) [0.000000|7.000000] "" Motor_BEV
 SG_ IPA_TPA_Remote  : 157|2@1+ (1.000000,0.000000) [0.000000|3.000000] "" Vector__XXX
 SG_ IPA_TPA_Remote_Anf  : 159|1@1+ (1.000000,0.000000) [0.000000|1.000000] "" Vector__XXX
 SG_ IPA_TPA_Fehler  : 160|4@1+ (1.000000,0.000000) [0.000000|15.000000] "" Vector__XXX
 SG_ IPA_TPA_Abbruch  : 164|4@1+ (1.000000,0.000000) [0.000000|15.000000] "" Vector__XXX
 SG_ IPA_TPA_Status  : 168|4@1+ (1.000000,0.000000) [0.000000|15.000000] "" Vector__XXX

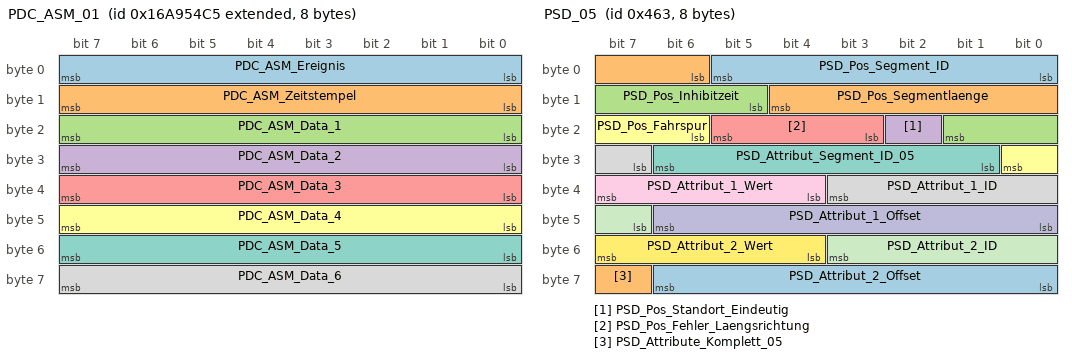
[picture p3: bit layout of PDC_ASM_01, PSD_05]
BO_ 2527679685 PDC_ASM_01: 8 ICAS1_Gateway
 SG_ PDC_ASM_Ereignis  : 0|8@1+ (1.000000,0.000000) [1.000000|254.000000] "" Airbag
 SG_ PDC_ASM_Zeitstempel  : 8|8@1+ (0.080000,0.000000) [0.000000|20.320000] "Unit_Secon" Airbag
 SG_ PDC_ASM_Data_1  : 16|8@1+ (1.000000,0.000000) [0.000000|255.000000] "" Airbag
 SG_ PDC_ASM_Data_2  : 24|8@1+ (1.000000,0.000000) [0.000000|255.000000] "" Airbag
 SG_ PDC_ASM_Data_3  : 32|8@1+ (1.000000,0.000000) [0.000000|255.000000] "" Airbag
 SG_ PDC_ASM_Data_4  : 40|8@1+ (1.000000,0.000000) [0.000000|255.000000] "" Airbag
 SG_ PDC_ASM_Data_5  : 48|8@1+ (1.000000,0.000000) [0.000000|255.000000] "" Airbag
 SG_ PDC_ASM_Data_6  : 56|8@1+ (1.000000,0.000000) [0.000000|255.000000] "" Airbag

BO_ 319 PreCrash_02: 8 Airbag
 SG_ PreCrash_Charisma_FahrPr  : 12|4@1+ (1.000000,0.000000) [0.000000|15.000000] "" ICAS1_Gateway
 SG_ PreCrash_Charisma_Status  : 16|2@1+ (1.000000,0.000000) [0.000000|3.000000] "" ICAS1_Gateway
 SG_ PreCrash_Schiebedach_schliessen  : 18|1@1+ (1.000000,0.000000) [0.000000|1.000000] "" ICAS1_Gateway
 SG_ PreCrash_Fenster_schliessen  : 19|1@1+ (1.000000,0.000000) [0.000000|1.000000] "" ICAS1_Gateway
 SG_ PreCrash_Blinken  : 20|3@1+ (1.000000,0.000000) [0.000000|7.000000] "" ICAS1_Gateway
 SG_ SC_PreSense_FCWP  : 23|1@1+ (1.000000,0.000000) [0.000000|1.000000] "" ICAS1_Gateway
 SG_ PreCrash_Tueren_Verriegeln  : 24|1@1+ (1.000000,0.000000) [0.000000|1.000000] "" ICAS1_Gateway
 SG_ PreCrash_FS_Laengsverstellung  : 25|1@1+ (1.000000,0.000000) [0.000000|1.000000] "" ICAS1_Gateway
 SG_ PreCrash_Anforderung_AFR  : 26|3@1+ (1.000000,0.000000) [0.000000|7.000000] "" ICAS1_Gateway
 SG_ SC_PreCrash_LED  : 29|2@1+ (1.000000,0.000000) [0.000000|3.000000] "" ICAS1_Gateway
 SG_ PreCrash_FS_Pneumatik_ansteuern  : 31|1@1+ (1.000000,0.000000) [0.000000|1.000000] "" ICAS1_Gateway
 SG_ PreCrash_BFS_Pneumatik_ansteuern  : 32|1@1+ (1.000000,0.000000) [0.000000|1.000000] "" ICAS1_Gateway
 SG_ PreCrash_Fo_Pneumatik_ansteuern  : 33|1@1+ (1.000000,0.000000) [0.000000|1.000000] "" ICAS1_Gateway
 SG_ PreCrash_FS_Sitzlehne_verfahren  : 34|3@1+ (1.000000,0.000000) [0.000000|7.000000] "" ICAS1_Gateway
 SG_ PreCrash_BFS_Sitzlehne_verfahren  : 37|3@1+ (1.000000,0.000000) [0.000000|7.000000] "" ICAS1_Gateway
 SG_ PreCrash_Fo_Sitzlehne_verfahren  : 40|3@1+ (1.000000,0.000000) [0.000000|7.000000] "" ICAS1_Gateway
 SG_ PreCrash_FS_KSV_verfahren  : 43|4@1+ (1.000000,0.000000) [0.000000|15.000000] "" ICAS1_Gateway
 SG_ PreCrash_BFS_KSV_verfahren  : 47|4@1+ (1.000000,0.000000) [0.000000|15.000000] "" ICAS1_Gateway
 SG_ PreCrash_Fo_KSV_verfahren  : 51|4@1+ (1.000000,0.000000) [0.000000|15.000000] "" ICAS1_Gateway
 SG_ PreCrash_BFS_Laengsverstellung  : 55|1@1+ (1.000000,0.000000) [0.000000|1.000000] "" ICAS1_Gateway
 SG_ SC_PreCrash_Warnung  : 56|4@1+ (1.000000,0.000000) [0.000000|15.000000] "" ICAS1_Gateway ICAS1_KommunikationsServer
 SG_ SC_PreCrash_Texte  : 60|4@1+ (1.000000,0.000000) [0.000000|15.000000] "" ICAS1_Gateway ICAS1_KommunikationsServer

BO_ 1122 PSD_04: 8 ICAS1_Gateway
 SG_ PSD_Segment_ID  : 0|6@1+ (1.000000,0.000000) [2.000000|63.000000] "" Motor_BEV
 SG_ PSD_Vorgaenger_Segment_ID  : 6|6@1+ (1.000000,0.000000) [2.000000|63.000000] "" Motor_BEV
 SG_ PSD_Segmentlaenge  : 12|7@1+ (2.000000,0.000000) [0.000000|254.000000] "Unit_Meter" Motor_BEV
 SG_ PSD_Strassenkategorie  : 19|3@1+ (1.000000,0.000000) [0.000000|7.000000] "" Motor_BEV
 SG_ PSD_Endkruemmung  : 22|8@1+ (1.000000,0.000000) [0.000000|254.000000] "Unit_None" Motor_BEV
 SG_ PSD_Endkruemmung_Vorz  : 30|1@1+ (1.000000,0.000000) [0.000000|1.000000] "" Motor_BEV
 SG_ PSD_Idenditaets_ID  : 31|6@1+ (1.000000,0.000000) [2.000000|63.000000] "" Vector__XXX
 SG_ PSD_ADAS_Qualitaet  : 37|1@1+ (1.000000,0.000000) [0.000000|1.000000] "" Motor_BEV
 SG_ PSD_wahrscheinlichster_Pfad  : 38|1@1+ (1.000000,0.000000) [0.000000|1.000000] "" Motor_BEV
 SG_ PSD_Geradester_Pfad  : 39|1@1+ (1.000000,0.000000) [0.000000|1.000000] "" Motor_BEV
 SG_ PSD_Fahrspuren_Anzahl  : 40|3@1+ (1.000000,0.000000) [0.000000|7.000000] "" Motor_BEV
 SG_ PSD_Bebauung  : 43|1@1+ (1.000000,0.000000) [0.000000|1.000000] "" Motor_BEV
 SG_ PSD_Segment_Komplett  : 44|1@1+ (1.000000,0.000000) [0.000000|1.000000] "" Motor_BEV
 SG_ PSD_Rampe  : 45|2@1+ (1.000000,0.000000) [0.000000|3.000000] "" Motor_BEV
 SG_ PSD_Anfangskruemmung  : 47|8@1+ (1.000000,0.000000) [0.000000|254.000000] "" Motor_BEV
 SG_ PSD_Anfangskruemmung_Vorz  : 55|1@1+ (1.000000,0.000000) [0.000000|1.000000] "" Motor_BEV
 SG_ PSD_Abzweigerichtung  : 56|1@1+ (1.000000,0.000000) [0.000000|1.000000] "" Motor_BEV
 SG_ PSD_Abzweigewinkel  : 57|7@1+ (1.417323,0.000000) [0.000000|180.000021] "" Motor_BEV

BO_ 1123 PSD_05: 8 ICAS1_Gateway
 SG_ PSD_Pos_Segment_ID  : 0|6@1+ (1.000000,0.000000) [2.000000|63.000000] "" Motor_BEV
 SG_ PSD_Pos_Segmentlaenge  : 6|7@1+ (2.000000,0.000000) [0.000000|254.000000] "Unit_Meter" Motor_BEV
 SG_ PSD_Pos_Inhibitzeit  : 13|5@1+ (10.000000,0.000000) [0.000000|310.000000] "Unit_MilliSecon" Motor_BEV
 SG_ PSD_Pos_Standort_Eindeutig  : 18|1@1+ (1.000000,0.000000) [0.000000|1.000000] "" Motor_BEV
 SG_ PSD_Pos_Fehler_Laengsrichtung  : 19|3@1+ (1.000000,0.000000) [0.000000|7.000000] "" Motor_BEV
 SG_ PSD_Pos_Fahrspur  : 22|3@1+ (1.000000,0.000000) [0.000000|7.000000] "" Motor_BEV
 SG_ PSD_Attribut_Segment_ID_05  : 25|6@1+ (1.000000,0.000000) [2.000000|63.000000] "" Motor_BEV
 SG_ PSD_Attribut_1_ID  : 31|5@1+ (1.000000,0.000000) [1.000000|31.000000] "" Motor_BEV
 SG_ PSD_Attribut_1_Wert  : 36|4@1+ (1.000000,0.000000) [0.000000|15.000000] "" Motor_BEV
 SG_ PSD_Attribut_1_Offset  : 40|7@1+ (2.000000,0.000000) [0.000000|254.000000] "Unit_Meter" Motor_BEV
 SG_ PSD_Attribut_2_ID  : 47|5@1+ (1.000000,0.000000) [1.000000|31.000000] "" Motor_BEV
 SG_ PSD_Attribut_2_Wert  : 52|4@1+ (1.000000,0.000000) [0.000000|15.000000] "" Motor_BEV
 SG_ PSD_Attribut_2_Offset  : 56|7@1+ (2.000000,0.000000) [0.000000|254.000000] "Unit_Meter" Motor_BEV
 SG_ PSD_Attribute_Komplett_05  : 63|1@1+ (1.000000,0.000000) [0.000000|1.000000] "" Motor_BEV

BO_ 1124 PSD_06: 8 ICAS1_Gateway
 SG_ PSD_06_Mux M : 0|3@1+ (1.000000,0.000000) [0.000000|7.000000] "" Motor_BEV
 SG_ PSD_Sys_Segment_ID m0 : 3|6@1+ (1.000000,0.000000) [2.000000|63.000000] "" Motor_BEV
 SG_ PSD_Attribut_Segment_ID m1 : 3|6@1+ (1.000000,0.000000) [2.000000|63.000000] "" Motor_BEV
 SG_ PSD_Ges_Segment_ID m2 : 3|6@1+ (1.000000,0.000000) [2.000000|63.000000] "" Motor_BEV
 SG_ PSD_Baum_Laenge_VZ m3 : 3|1@1+ (1.000000,0.000000) [0.000000|1.000000] "" Motor_BEV
 SG_ PSD_Steigung_1_Segment_ID m4 : 3|6@1+ (1.000000,0.000000) [2.000000|63.000000] "" Motor_BEV
 SG_ PSD_Baum_Laenge m3 : 4|25@1+ (0.000010,0.000000) [0.000000|180.000000] "Unit_DegreOfArc" Motor_BEV
 SG_ PSD_Sys_Laendercode m0 : 9|8@1+ (1.000000,0.000000) [0.000000|255.000000] "" Motor_BEV
 SG_ PSD_Attribut_3_ID m1 : 9|5@1+ (1.000000,0.000000) [1.000000|31.000000] "" Motor_BEV
 SG_ PSD_Ges_Offset m2 : 9|7@1+ (2.000000,0.000000) [0.000000|254.000000] "Unit_Meter" Motor_BEV
 SG_ PSD_Steigung_1_A_Steigung m4 : 9|7@1+ (0.120000,0.000000) [0.000000|15.000000] "Unit_PerCent" Motor_BEV
 SG_ PSD_Attribut_3_Offset m1 : 14|7@1+ (2.000000,0.000000) [0.000000|254.000000] "Unit_Meter" Motor_BEV
 SG_ PSD_Ges_Geschwindigkeit m2 : 16|5@1+ (1.000000,0.000000) [0.000000|31.000000] "" Motor_BEV
 SG_ PSD_Steigung_1_A_Vorz m4 : 16|1@1+ (1.000000,0.000000) [0.000000|1.000000] "" Motor_BEV
 SG_ PSD_Sys_Geschwindigkeit_Einheit m0 : 17|1@1+ (1.000000,0.000000) [0.000000|1.000000] "" Motor_BEV
 SG_ PSD_Steigung_1_A_Offset m4 : 17|7@1+ (2.000000,0.000000) [0.000000|254.000000] "Unit_Meter" Motor_BEV
 SG_ PSD_Sys_Verkehrsrichtung m0 : 18|1@1+ (1.000000,0.000000) [0.000000|1.000000] "" Motor_BEV
 SG_ PSD_Sys_Geometrieguete m0 : 19|2@1+ (1.000000,0.000000) [0.000000|3.000000] "" Motor_BEV
 SG_ PSD_Sys_Mapmatchingguete m0 : 21|2@1+ (1.000000,0.000000) [0.000000|3.000000] "" Motor_BEV
 SG_ PSD_Attribut_3_Wert m1 : 21|4@1+ (1.000000,0.000000) [0.000000|15.000000] "" Motor_BEV
 SG_ PSD_Ges_Typ m2 : 21|2@1+ (1.000000,0.000000) [0.000000|3.000000] "" Motor_BEV
 SG_ PSD_Sys_Alter_Karte m0 : 23|3@1+ (1.000000,0.000000) [0.000000|7.000000] "" Motor_BEV
 SG_ PSD_Ges_Spur_Geschw_Begrenzung m2 : 23|6@1+ (1.000000,0.000000) [0.000000|63.000000] "" Motor_BEV
 SG_ PSD_Steigung_1_B_Steigung m4 : 24|7@1+ (0.120000,0.000000) [0.000000|15.000000] "Unit_PerCent" Motor_BEV
 SG_ PSD_Attribut_4_ID m1 : 25|5@1+ (1.000000,0.000000) [1.000000|31.000000] "" Motor_BEV
 SG_ PSD_Sys_Zielfuehrung m0 : 26|1@1+ (1.000000,0.000000) [0.000000|1.000000] "" Motor_BEV
 SG_ PSD_Sys_US_State m0 : 27|6@1+ (1.000000,0.000000) [0.000000|63.000000] "" Motor_BEV
 SG_ PSD_Ges_Geschwindigkeit_Gespann m2 : 29|2@1+ (1.000000,0.000000) [0.000000|3.000000] "" Motor_BEV
 SG_ PSD_Baum_Breite_VZ m3 : 29|1@1+ (1.000000,0.000000) [0.000000|1.000000] "" Motor_BEV
 SG_ PSD_Attribut_4_Wert m1 : 30|4@1+ (1.000000,0.000000) [0.000000|15.000000] "" Motor_BEV
 SG_ PSD_Baum_Breite m3 : 30|24@1+ (0.000010,0.000000) [0.000000|90.000000] "Unit_DegreOfArc" Motor_BEV
 SG_ PSD_Ges_Geschwindigkeit_Witter m2 : 31|2@1+ (1.000000,0.000000) [0.000000|3.000000] "" Motor_BEV
 SG_ PSD_Steigung_1_B_Vorz m4 : 31|1@1+ (1.000000,0.000000) [0.000000|1.000000] "" Motor_BEV
 SG_ PSD_Steigung_1_B_Offset m4 : 32|7@1+ (2.000000,0.000000) [0.000000|254.000000] "Unit_Meter" Motor_BEV
 SG_ PSD_Sys_Quali_Geometrien m0 : 33|3@1+ (1.000000,0.000000) [0.000000|7.000000] "Unit_None" Vector__XXX
 SG_ PSD_Ges_Geschwindigkeit_Tag_Anf m2 : 33|3@1+ (1.000000,0.000000) [0.000000|7.000000] "" Motor_BEV
 SG_ PSD_Attribut_4_Offset m1 : 34|7@1+ (2.000000,0.000000) [0.000000|254.000000] "Unit_Meter" Motor_BEV
 SG_ PSD_Sys_Quali_Ortsinfo m0 : 36|2@1+ (1.000000,0.000000) [0.000000|3.000000] "Unit_None" Vector__XXX
 SG_ PSD_Ges_Geschwindigkeit_Tag_Ende m2 : 36|3@1+ (1.000000,0.000000) [0.000000|7.000000] "" Motor_BEV
 SG_ PSD_Sys_Quali_verfuegbar m0 : 38|1@1+ (1.000000,0.000000) [0.000000|1.000000] "" Vector__XXX
 SG_ PSD_Sys_Zielfuehrung_geaendert m0 : 39|1@1+ (1.000000,0.000000) [0.000000|1.000000] "" Motor_BEV
 SG_ PSD_Ges_Geschwindigkeit_Std_Anf m2 : 39|5@1+ (1.000000,0.000000) [0.000000|24.000000] "Unit_Hours" Motor_BEV
 SG_ PSD_Steigung_1_Attribute_kompl m4 : 39|1@1+ (1.000000,0.000000) [0.000000|1.000000] "" Motor_BEV
 SG_ PSD_Sys_Geometrieguete_erweitert m0 : 40|8@1+ (1.000000,0.000000) [0.000000|255.000000] "" Vector__XXX
 SG_ PSD_Steigung_2_Segment_ID m4 : 40|6@1+ (1.000000,0.000000) [2.000000|63.000000] "" Motor_BEV
 SG_ PSD_Attribut_5_ID m1 : 41|5@1+ (1.000000,0.000000) [1.000000|31.000000] "" Motor_BEV
 SG_ PSD_Ges_Geschwindigkeit_Std_Ende m2 : 44|5@1+ (1.000000,0.000000) [0.000000|24.000000] "Unit_Hours" Motor_BEV
 SG_ PSD_Attribut_5_Offset m1 : 46|7@1+ (2.000000,0.000000) [0.000000|254.000000] "Unit_Meter" Motor_BEV
 SG_ PSD_Steigung_2_Steigung m4 : 46|7@1+ (0.120000,0.000000) [0.000000|15.000000] "Unit_PerCent" Motor_BEV
 SG_ PSD_Sys_Quali_sonstige_Attribute m0 : 48|3@1+ (1.000000,0.000000) [0.000000|7.000000] "Unit_None" Vector__XXX
 SG_ PSD_Ges_Ueberholverbot m2 : 49|2@1+ (1.000000,0.000000) [0.000000|3.000000] "" Vector__XXX
 SG_ PSD_Sys_Quali_Steigungen m0 : 51|3@1+ (1.000000,0.000000) [0.000000|7.000000] "" Vector__XXX
 SG_ PSD_Ges_Wechselverkehrszeichen m2 : 51|3@1+ (1.000000,0.000000) [0.000000|7.000000] "" Vector__XXX
 SG_ PSD_Attribut_5_Wert m1 : 53|4@1+ (1.000000,0.000000) [0.000000|15.000000] "" Motor_BEV
 SG_ PSD_Steigung_2_Vorz m4 : 53|1@1+ (1.000000,0.000000) [0.000000|1.000000] "" Motor_BEV
 SG_ PSD_Sys_Quali_Strassenkennz m0 : 54|3@1+ (1.000000,0.000000) [0.000000|7.000000] "Unit_None" Vector__XXX
 SG_ PSD_Wechselverkehrszeichen_Typ m2 : 54|2@1+ (1.000000,0.000000) [0.000000|3.000000] "" Vector__XXX
 SG_ PSD_Baum_Ausrichtung m3 : 54|10@1+ (0.351562,0.000000) [0.000000|359.648438] "Unit_DegreOfArc" Vector__XXX
 SG_ PSD_Steigung_2_Offset m4 : 54|7@1+ (2.000000,0.000000) [0.000000|254.000000] "Unit_Meter" Motor_BEV
 SG_ PSD_Ges_Gesetzlich_Kategorie m2 : 56|3@1+ (1.000000,0.000000) [0.000000|7.000000] "" Motor_BEV
 SG_ PSD_Sys_Quali_Tempolimits m0 : 57|3@1+ (1.000000,0.000000) [0.000000|7.000000] "Unit_None" Vector__XXX
 SG_ PSD_Attribute_Komplett_06 m1 : 57|1@1+ (1.000000,0.000000) [0.000000|1.000000] "" Motor_BEV
 SG_ PSD_Ges_Gesetzlich_Zusatz m2 : 59|2@1+ (1.000000,0.000000) [0.000000|3.000000] "" Motor_BEV
 SG_ PSD_Sys_Quali_Vorfahrtsregelung m0 : 60|3@1+ (1.000000,0.000000) [0.000000|7.000000] "Unit_None" Vector__XXX
 SG_ PSD_Ges_Verkehrszeichen_Quelle m2 : 61|2@1+ (1.000000,0.000000) [0.000000|3.000000] "" Motor_BEV
 SG_ PSD_Steigung_2_Attribute_kompl m4 : 61|1@1+ (1.000000,0.000000) [0.000000|1.000000] "" Motor_BEV
 SG_ PSD_Ges_Attribute_Komplett m2 : 63|1@1+ (1.000000,0.000000) [0.000000|1.000000] "" Motor_BEV

BO_ 591 RDR1_Objekte_02: 64 ICAS1_Gateway
 SG_ RDR1_relevanter_Fehler  : 12|1@1+ (1.000000,0.000000) [0.000000|1.000000] "" Motor_BEV
 SG_ RDR1_Blindheit_erkannt  : 13|1@1+ (1.000000,0.000000) [0.000000|1.000000] "" Motor_BEV
 SG_ RDR1_relev_Nichtverfuegbarkeit  : 14|1@1+ (1.000000,0.000000) [0.000000|1.000000] "" Motor_BEV
 SG_ RDR1_Obj_01_Nummer  : 16|6@1+ (1.000000,0.000000) [0.000000|63.000000] "" Vector__XXX
 SG_ RDR1_Obj_02_Nummer  : 22|6@1+ (1.000000,0.000000) [0.000000|63.000000] "" Vector__XXX
 SG_ RDR1_Obj_03_Nummer  : 28|6@1+ (1.000000,0.000000) [0.000000|63.000000] "" Vector__XXX
 SG_ RDR1_Obj_04_Nummer  : 34|6@1+ (1.000000,0.000000) [0.000000|63.000000] "" Vector__XXX
 SG_ RDR1_Obj_05_Nummer  : 40|6@1+ (1.000000,0.000000) [0.000000|63.000000] "" Vector__XXX
 SG_ RDR1_Obj_06_Nummer  : 46|6@1+ (1.000000,0.000000) [0.000000|63.000000] "" Vector__XXX
 SG_ RDR1_Verkehrssinn  : 52|2@1+ (1.000000,0.000000) [0.000000|3.000000] "" Vector__XXX
 SG_ RDR1_Objekte_02_Datenalter  : 54|10@1+ (0.000977,0.000000) [0.000000|0.998047] "Unit_Secon" Vector__XXX
 SG_ RDR1_Obj_01_dx_v  : 64|12@1+ (0.062500,0.000000) [0.000000|255.937500] "Unit_Meter" Motor_BEV
 SG_ RDR1_Obj_01_dy_v  : 76|10@1+ (0.062500,-32.000000) [-32.000000|31.937500] "Unit_Meter" Motor_BEV
 SG_ RDR1_Obj_01_vx_v  : 86|10@1+ (0.250000,-128.000000) [-128.000000|127.750000] "Unit_MeterPerSecon" Motor_BEV
 SG_ RDR1_Obj_02_dx_v  : 96|12@1+ (0.062500,0.000000) [0.000000|255.937500] "Unit_Meter" Vector__XXX
 SG_ RDR1_Obj_02_dy_v  : 108|10@1+ (0.062500,-32.000000) [-32.000000|31.937500] "Unit_Meter" Vector__XXX
 SG_ RDR1_Obj_02_vx_v  : 118|10@1+ (0.250000,-128.000000) [-128.000000|127.750000] "Unit_MeterPerSecon" Vector__XXX
 SG_ RDR1_Obj_03_dx_v  : 128|12@1+ (0.062500,0.000000) [0.000000|255.937500] "Unit_Meter" Vector__XXX
 SG_ RDR1_Obj_03_dy_v  : 140|10@1+ (0.062500,-32.000000) [-32.000000|31.937500] "Unit_Meter" Vector__XXX
 SG_ RDR1_Obj_03_vx_v  : 150|10@1+ (0.250000,-128.000000) [-128.000000|127.750000] "Unit_MeterPerSecon" Vector__XXX
 SG_ RDR1_Obj_04_dx_v  : 160|12@1+ (0.062500,0.000000) [0.000000|255.937500] "Unit_Meter" Motor_BEV
 SG_ RDR1_Obj_04_dy_v  : 172|10@1+ (0.062500,-32.000000) [-32.000000|31.937500] "Unit_Meter" Vector__XXX
 SG_ RDR1_Obj_04_vx_v  : 182|10@1+ (0.250000,-128.000000) [-128.000000|127.750000] "Unit_MeterPerSecon" Motor_BEV
 SG_ RDR1_Obj_05_dx_v  : 192|12@1+ (0.062500,0.000000) [0.000000|255.937500] "Unit_Meter" Vector__XXX
 SG_ RDR1_Obj_05_dy_v  : 204|10@1+ (0.062500,-32.000000) [-32.000000|31.937500] "Unit_Meter" Vector__XXX
 SG_ RDR1_Obj_05_vx_v  : 214|10@1+ (0.250000,-128.000000) [-128.000000|127.750000] "Unit_MeterPerSecon" Vector__XXX
 SG_ RDR1_Obj_06_dx_v  : 224|12@1+ (0.062500,0.000000) [0.000000|255.937500] "Unit_Meter" Vector__XXX
 SG_ RDR1_Obj_06_dy_v  : 236|10@1+ (0.062500,-32.000000) [-32.000000|31.937500] "Unit_Meter" Vector__XXX
 SG_ RDR1_Obj_06_vx_v  : 246|10@1+ (0.250000,-128.000000) [-128.000000|127.750000] "Unit_MeterPerSecon" Vector__XXX
 SG_ RDR1_Obj_01_ax_v  : 256|8@1+ (0.125000,-16.000000) [-16.000000|15.750000] "Unit_MeterPerSeconSquar" Motor_BEV
 SG_ RDR1_Obj_01_ax_StdA  : 264|6@1+ (0.125000,0.000000) [0.000000|7.750000] "Unit_MeterPerSeconSquar" Motor_BEV
 SG_ RDR1_Obj_01_vx_StdA  : 270|7@1+ (0.031250,0.000000) [0.000000|3.937500] "Unit_MeterPerSecon" Motor_BEV
 SG_ RDR1_Obj_01_dx_StdA  : 277|7@1+ (0.050000,0.000000) [0.000000|6.300000] "Unit_Meter" Motor_BEV
 SG_ RDR1_Obj_01_dy_StdA  : 284|7@1+ (0.062500,0.000000) [0.000000|7.875000] "Unit_Meter" Motor_BEV

BO_ 2033 Request_Airbag_Deployment: 8 ICAS1_Gateway
 SG_ Request_Airbag_Deployment  : 0|64@1+ (1.000000,0.000000) [0.000000|18446744073709551616.000000] "" Airbag

BO_ 2041 Response_Airbag_Deployment: 8 Airbag
 SG_ Response_Airbag_Deployment  : 0|64@1+ (1.000000,0.000000) [0.000000|18446744073709551616.000000] "" ICAS1_Gateway

BU_:  Airbag BAP_Tester ICAS1_Gateway ICAS1_KommunikationsServer LE1 LE2 Motor_BEV Schaltbetaetigung

BO_ 2463978709 OCC_02: 32 ICAS1_Gateway
 SG_ OCC_CP_Tastgrad_A  : 12|10@1+ (0.100000,0.000000) [0.000000|100.000000] "Unit_PerCent" Vector__XXX
 SG_ OCC_CP_Tastgrad_B  : 22|10@1+ (0.100000,0.000000) [0.000000|100.000000] "Unit_PerCent" Vector__XXX
 SG_ OCC_CP_Frequenz_A  : 32|8@1+ (1.000000,880.000000) [880.000000|1132.000000] "Unit_Hertz" Vector__XXX
 SG_ OCC_CP_Frequenz_B  : 40|8@1+ (1.000000,880.000000) [880.000000|1132.000000] "Unit_Hertz" Vector__XXX
 SG_ OCC_CP_Spannung_A  : 48|9@1+ (0.100000,-25.000000) [-25.000000|25.900000] "Unit_Volt" Vector__XXX
 SG_ OCC_CP_Spannung_B  : 57|9@1+ (0.100000,-25.000000) [-25.000000|25.900000] "Unit_Volt" Vector__XXX
 SG_ OCC_CP_Fehlerstatus_A  : 66|3@1+ (1.000000,0.000000) [0.000000|7.000000] "" Vector__XXX
 SG_ OCC_CP_Fehlerstatus_B  : 69|3@1+ (1.000000,0.000000) [0.000000|7.000000] "" Vector__XXX
 SG_ OCC_Temp_Ladedose_A_AC  : 72|8@1+ (1.000000,-40.000000) [-40.000000|213.000000] "Unit_DegreCelsi" Vector__XXX
 SG_ OCC_Temp_Ladedose_A_DC_minus  : 80|8@1+ (1.000000,-40.000000) [-40.000000|213.000000] "Unit_DegreCelsi" Vector__XXX
 SG_ OCC_Temp_Ladedose_A_DC_plus  : 88|8@1+ (1.000000,-40.000000) [-40.000000|213.000000] "Unit_DegreCelsi" Vector__XXX
 SG_ OCC_U_istAC_Netz_L1  : 96|9@1+ (1.000000,0.000000) [0.000000|509.000000] "Unit_Volt" Vector__XXX
 SG_ OCC_U_istAC_Netz_L2  : 105|9@1+ (1.000000,0.000000) [0.000000|509.000000] "Unit_Volt" Vector__XXX
 SG_ OCC_U_istAC_Netz_L3  : 114|9@1+ (1.000000,0.000000) [0.000000|508.000000] "Unit_Volt" Vector__XXX
 SG_ OCC_StatusVerEntriegelungAktor_A  : 123|3@1+ (1.000000,0.000000) [0.000000|7.000000] "" Vector__XXX
 SG_ OCC_SteckerEntriegelung_Verbot_A  : 126|2@1+ (1.000000,0.000000) [0.000000|3.000000] "" Vector__XXX
 SG_ OCC_StatusVerEntriegelungAktor_B  : 128|3@1+ (1.000000,0.000000) [0.000000|7.000000] "" Vector__XXX
 SG_ OCC_SteckerEntriegelung_Verbot_B  : 131|2@1+ (1.000000,0.000000) [0.000000|3.000000] "" Vector__XXX
 SG_ OCC_Verriegelung_Status_A  : 133|3@1+ (1.000000,0.000000) [0.000000|7.000000] "" Vector__XXX
 SG_ OCC_Verriegelung_Status_B  : 136|3@1+ (1.000000,0.000000) [0.000000|7.000000] "" Vector__XXX
 SG_ OCC_RtmWarnLadeKommunikation  : 139|3@1+ (1.000000,0.000000) [0.000000|7.000000] "" Vector__XXX
 SG_ OCC_Ist_Wirkungsgrad  : 145|7@1+ (1.000000,0.000000) [0.000000|100.000000] "Unit_PerCent" Vector__XXX
 SG_ OCC_PP_Max_Strom_A  : 152|4@1+ (1.000000,0.000000) [0.000000|15.000000] "" Vector__XXX
 SG_ OCC_PP_Max_Strom_B  : 156|4@1+ (1.000000,0.000000) [0.000000|15.000000] "" Vector__XXX
 SG_ OCC_DC_MaxStrom  : 160|11@1+ (0.100000,0.000000) [0.000000|204.500000] "Unit_Amper" Vector__XXX
 SG_ OCC_Derating_Temperatur  : 171|1@1+ (1.000000,0.000000) [0.000000|1.000000] "" Vector__XXX
 SG_ OCC_Fehlerzustand  : 172|1@1+ (1.000000,0.000000) [0.000000|1.000000] "" Vector__XXX
 SG_ OCC_Ladest_Entriegelungs_Verbot  : 173|3@1+ (1.000000,0.000000) [0.000000|7.000000] "" Vector__XXX
 SG_ OCC_Netzfrequenz_EVU  : 176|9@1+ (0.100000,40.000000) [40.000000|80.000000] "Unit_Hertz" Vector__XXX
 SG_ OCC_Warnzustand  : 185|1@1+ (1.000000,0.000000) [0.000000|1.000000] "" Vector__XXX
 SG_ OCC_Kuehltemperatur  : 192|8@1+ (1.000000,-40.000000) [-40.000000|213.000000] "Unit_DegreCelsi" Motor_BEV
 SG_ OCC_PP_Fehlerstatus_A  : 200|4@1+ (1.000000,0.000000) [0.000000|15.000000] "" Vector__XXX
 SG_ OCC_PP_Fehlerstatus_B  : 204|4@1+ (1.000000,0.000000) [0.000000|15.000000] "" Vector__XXX

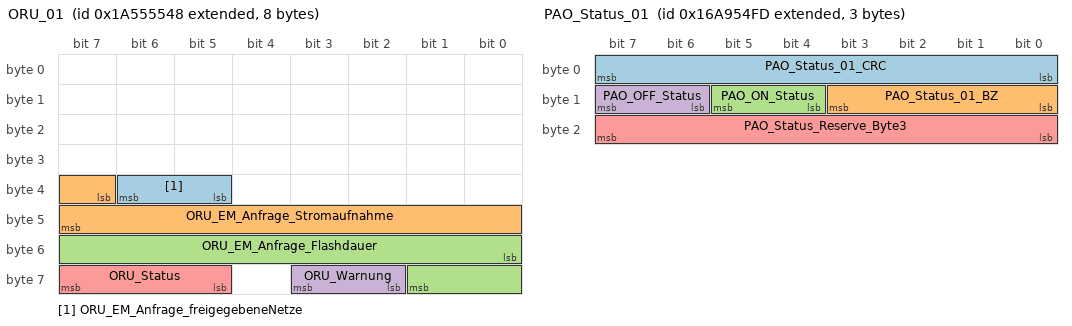
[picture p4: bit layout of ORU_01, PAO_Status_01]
BO_ 2589283656 ORU_01: 8 ICAS1_Gateway
 SG_ ORU_EM_Anfrage_freigegebeneNetze  : 37|2@1+ (1.000000,0.000000) [0.000000|3.000000] "" Vector__XXX
 SG_ ORU_EM_Anfrage_Stromaufnahme  : 39|9@1+ (0.100000,0.000000) [0.000000|51.100000] "Unit_Amper" Vector__XXX
 SG_ ORU_EM_Anfrage_Flashdauer  : 48|10@1+ (10.000000,0.000000) [0.000000|10230.000000] "Unit_Secon" Vector__XXX
 SG_ ORU_Warnung  : 58|2@1+ (1.000000,0.000000) [0.000000|3.000000] "" Vector__XXX
 SG_ ORU_Status  : 61|3@1+ (1.000000,0.000000) [0.000000|7.000000] "" Airbag LE1 LE2 Motor_BEV

BO_ 2527679741 PAO_Status_01: 3 ICAS1_Gateway
 SG_ PAO_Status_01_CRC  : 0|8@1+ (1.000000,0.000000) [0.000000|255.000000] "" Airbag
 SG_ PAO_Status_01_BZ  : 8|4@1+ (1.000000,0.000000) [0.000000|15.000000] "" Airbag
 SG_ PAO_ON_Status  : 12|2@1+ (1.000000,0.000000) [0.000000|3.000000] "" Airbag
 SG_ PAO_OFF_Status  : 14|2@1+ (1.000000,0.000000) [0.000000|3.000000] "" Airbag
 SG_ PAO_Status_Reserve_Byte3  : 16|8@1+ (1.000000,0.000000) [0.000000|255.000000] "" Vector__XXX

BO_ 518 Parken_01: 24 ICAS1_Gateway
 SG_ Parken_BKD_Anf  : 12|4@1+ (0.100000,0.000000) [0.000000|1.300000] "Unit_Secon" Vector__XXX
 SG_ Parken_Verz_Anf  : 16|7@1+ (0.100000,-12.600000) [-12.600000|-0.100000] "Unit_MeterPerSeconSquar" Vector__XXX
 SG_ Parken_Prefill_Anf  : 23|1@1+ (1.000000,0.000000) [0.000000|1.000000] "" Vector__XXX
 SG_ Parken_Warnruck_Anf  : 24|2@1+ (1.000000,0.000000) [0.000000|3.000000] "" Vector__XXX
 SG_ Parken_Verz_Anf_ASIL  : 26|2@1+ (1.000000,0.000000) [0.000000|3.000000] "" Vector__XXX
 SG_ Parken_Warnruckeln_Anf  : 28|2@1+ (1.000000,0.000000) [0.000000|3.000000] "" Vector__XXX
 SG_ Parken_beibehalten  : 30|2@1+ (1.000000,0.000000) [0.000000|3.000000] "" Vector__XXX
 SG_ Parken_Anforderung_HMS  : 32|3@1+ (1.000000,0.000000) [0.000000|7.000000] "" Vector__XXX
 SG_ Parken_Notstopp_Anf  : 40|2@1+ (1.000000,0.000000) [0.000000|3.000000] "" Vector__XXX
 SG_ Parken_Anhalteweg_Anf  : 42|10@1+ (0.010000,0.000000) [0.000000|10.210000] "Unit_Meter" Vector__XXX
 SG_ Parken_aktives_System  : 52|4@1+ (1.000000,0.000000) [0.000000|15.000000] "" Motor_BEV
 SG_ Parken_max_Beschleunigung  : 56|7@1+ (0.100000,-6.000000) [-5.900000|6.100000] "Unit_MeterPerSeconSquar" Motor_BEV
 SG_ Parken_Blinker_li_Anf  : 63|1@1+ (1.000000,0.000000) [0.000000|1.000000] "" Vector__XXX
 SG_ Parken_QFK_KruemmSoll  : 64|15@1+ (0.000007,0.000000) [0.000000|0.219539] "Unit_MeterInver" Vector__XXX
 SG_ Parken_QFK_KruemmSoll_VZ  : 79|1@1+ (1.000000,0.000000) [0.000000|1.000000] "" Vector__XXX
 SG_ Parken_QFK_Spuerb  : 80|8@1+ (0.400000,0.000000) [0.000000|100.000000] "Unit_PerCent" Vector__XXX
 SG_ Parken_QFK_AnfStat  : 88|4@1+ (1.000000,0.000000) [0.000000|15.000000] "" Vector__XXX
 SG_ Parken_QFK_Signal1  : 92|10@1+ (1.000000,0.000000) [0.000000|1023.000000] "" Vector__XXX
 SG_ Parken_QFK_Art1  : 102|3@1+ (1.000000,0.000000) [0.000000|7.000000] "" Vector__XXX
 SG_ Parken_QFK_Art2  : 105|3@1+ (1.000000,0.000000) [0.000000|7.000000] "" Vector__XXX
 SG_ Parken_QFK_Signal2  : 108|10@1+ (1.000000,0.000000) [0.000000|1023.000000] "" Vector__XXX
 SG_ Parken_Sollbeschleunigung  : 118|9@1+ (0.010000,-4.110000) [-4.100000|1.000000] "Unit_MeterPerSeconSquar" Motor_BEV
 SG_ Parken_Blinker_re_Anf  : 127|1@1+ (1.000000,0.000000) [0.000000|1.000000] "" Vector__XXX
 SG_ Parken_Status_IPA_TSK  : 128|4@1+ (1.000000,0.000000) [0.000000|15.000000] "" Motor_BEV
 SG_ Parken_erhoehtes_Moment  : 132|4@1+ (1.000000,0.000000) [0.000000|15.000000] "" Motor_BEV
 SG_ Parken_max_Geschwindigkeit  : 136|8@1+ (0.100000,0.000000) [0.100000|25.000000] "Unit_KiloMeterPerHour" Motor_BEV
 SG_ Parken_Soll_Anhalteweg_Anf  : 144|10@1+ (0.010000,0.000000) [0.000000|10.210000] "Unit_Meter" Vector__XXX
 SG_ Parken_Fahrstufenwunsch  : 154|3@1+ (1.000000,0.000000) [0.000000|7.000000] "" Motor_BEV
 SG_ IPA_TPA_Remote  : 157|2@1+ (1.000000,0.000000) [0.000000|3.000000] "" Vector__XXX
 SG_ IPA_TPA_Remote_Anf  : 159|1@1+ (1.000000,0.000000) [0.000000|1.000000] "" Vector__XXX
 SG_ IPA_TPA_Fehler  : 160|4@1+ (1.000000,0.000000) [0.000000|15.000000] "" Vector__XXX
 SG_ IPA_TPA_Abbruch  : 164|4@1+ (1.000000,0.000000) [0.000000|15.000000] "" Vector__XXX
 SG_ IPA_TPA_Status  : 168|4@1+ (1.000000,0.000000) [0.000000|15.000000] "" Vector__XXX

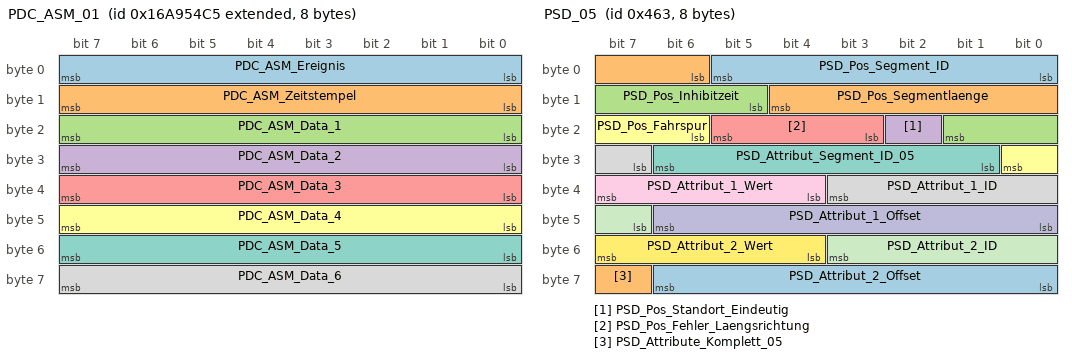
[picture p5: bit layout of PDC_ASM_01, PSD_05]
BO_ 2527679685 PDC_ASM_01: 8 ICAS1_Gateway
 SG_ PDC_ASM_Ereignis  : 0|8@1+ (1.000000,0.000000) [1.000000|254.000000] "" Airbag
 SG_ PDC_ASM_Zeitstempel  : 8|8@1+ (0.080000,0.000000) [0.000000|20.320000] "Unit_Secon" Airbag
 SG_ PDC_ASM_Data_1  : 16|8@1+ (1.000000,0.000000) [0.000000|255.000000] "" Airbag
 SG_ PDC_ASM_Data_2  : 24|8@1+ (1.000000,0.000000) [0.000000|255.000000] "" Airbag
 SG_ PDC_ASM_Data_3  : 32|8@1+ (1.000000,0.000000) [0.000000|255.000000] "" Airbag
 SG_ PDC_ASM_Data_4  : 40|8@1+ (1.000000,0.000000) [0.000000|255.000000] "" Airbag
 SG_ PDC_ASM_Data_5  : 48|8@1+ (1.000000,0.000000) [0.000000|255.000000] "" Airbag
 SG_ PDC_ASM_Data_6  : 56|8@1+ (1.000000,0.000000) [0.000000|255.000000] "" Airbag

BO_ 319 PreCrash_02: 8 Airbag
 SG_ PreCrash_Charisma_FahrPr  : 12|4@1+ (1.000000,0.000000) [0.000000|15.000000] "" ICAS1_Gateway
 SG_ PreCrash_Charisma_Status  : 16|2@1+ (1.000000,0.000000) [0.000000|3.000000] "" ICAS1_Gateway
 SG_ PreCrash_Schiebedach_schliessen  : 18|1@1+ (1.000000,0.000000) [0.000000|1.000000] "" ICAS1_Gateway
 SG_ PreCrash_Fenster_schliessen  : 19|1@1+ (1.000000,0.000000) [0.000000|1.000000] "" ICAS1_Gateway
 SG_ PreCrash_Blinken  : 20|3@1+ (1.000000,0.000000) [0.000000|7.000000] "" ICAS1_Gateway
 SG_ SC_PreSense_FCWP  : 23|1@1+ (1.000000,0.000000) [0.000000|1.000000] "" ICAS1_Gateway
 SG_ PreCrash_Tueren_Verriegeln  : 24|1@1+ (1.000000,0.000000) [0.000000|1.000000] "" ICAS1_Gateway
 SG_ PreCrash_FS_Laengsverstellung  : 25|1@1+ (1.000000,0.000000) [0.000000|1.000000] "" ICAS1_Gateway
 SG_ PreCrash_Anforderung_AFR  : 26|3@1+ (1.000000,0.000000) [0.000000|7.000000] "" ICAS1_Gateway
 SG_ SC_PreCrash_LED  : 29|2@1+ (1.000000,0.000000) [0.000000|3.000000] "" ICAS1_Gateway
 SG_ PreCrash_FS_Pneumatik_ansteuern  : 31|1@1+ (1.000000,0.000000) [0.000000|1.000000] "" ICAS1_Gateway
 SG_ PreCrash_BFS_Pneumatik_ansteuern  : 32|1@1+ (1.000000,0.000000) [0.000000|1.000000] "" ICAS1_Gateway
 SG_ PreCrash_Fo_Pneumatik_ansteuern  : 33|1@1+ (1.000000,0.000000) [0.000000|1.000000] "" ICAS1_Gateway
 SG_ PreCrash_FS_Sitzlehne_verfahren  : 34|3@1+ (1.000000,0.000000) [0.000000|7.000000] "" ICAS1_Gateway
 SG_ PreCrash_BFS_Sitzlehne_verfahren  : 37|3@1+ (1.000000,0.000000) [0.000000|7.000000] "" ICAS1_Gateway
 SG_ PreCrash_Fo_Sitzlehne_verfahren  : 40|3@1+ (1.000000,0.000000) [0.000000|7.000000] "" ICAS1_Gateway
 SG_ PreCrash_FS_KSV_verfahren  : 43|4@1+ (1.000000,0.000000) [0.000000|15.000000] "" ICAS1_Gateway
 SG_ PreCrash_BFS_KSV_verfahren  : 47|4@1+ (1.000000,0.000000) [0.000000|15.000000] "" ICAS1_Gateway
 SG_ PreCrash_Fo_KSV_verfahren  : 51|4@1+ (1.000000,0.000000) [0.000000|15.000000] "" ICAS1_Gateway
 SG_ PreCrash_BFS_Laengsverstellung  : 55|1@1+ (1.000000,0.000000) [0.000000|1.000000] "" ICAS1_Gateway
 SG_ SC_PreCrash_Warnung  : 56|4@1+ (1.000000,0.000000) [0.000000|15.000000] "" ICAS1_Gateway ICAS1_KommunikationsServer
 SG_ SC_PreCrash_Texte  : 60|4@1+ (1.000000,0.000000) [0.000000|15.000000] "" ICAS1_Gateway ICAS1_KommunikationsServer

BO_ 1122 PSD_04: 8 ICAS1_Gateway
 SG_ PSD_Segment_ID  : 0|6@1+ (1.000000,0.000000) [2.000000|63.000000] "" Motor_BEV
 SG_ PSD_Vorgaenger_Segment_ID  : 6|6@1+ (1.000000,0.000000) [2.000000|63.000000] "" Motor_BEV
 SG_ PSD_Segmentlaenge  : 12|7@1+ (2.000000,0.000000) [0.000000|254.000000] "Unit_Meter" Motor_BEV
 SG_ PSD_Strassenkategorie  : 19|3@1+ (1.000000,0.000000) [0.000000|7.000000] "" Motor_BEV
 SG_ PSD_Endkruemmung  : 22|8@1+ (1.000000,0.000000) [0.000000|254.000000] "Unit_None" Motor_BEV
 SG_ PSD_Endkruemmung_Vorz  : 30|1@1+ (1.000000,0.000000) [0.000000|1.000000] "" Motor_BEV
 SG_ PSD_Idenditaets_ID  : 31|6@1+ (1.000000,0.000000) [2.000000|63.000000] "" Vector__XXX
 SG_ PSD_ADAS_Qualitaet  : 37|1@1+ (1.000000,0.000000) [0.000000|1.000000] "" Motor_BEV
 SG_ PSD_wahrscheinlichster_Pfad  : 38|1@1+ (1.000000,0.000000) [0.000000|1.000000] "" Motor_BEV
 SG_ PSD_Geradester_Pfad  : 39|1@1+ (1.000000,0.000000) [0.000000|1.000000] "" Motor_BEV
 SG_ PSD_Fahrspuren_Anzahl  : 40|3@1+ (1.000000,0.000000) [0.000000|7.000000] "" Motor_BEV
 SG_ PSD_Bebauung  : 43|1@1+ (1.000000,0.000000) [0.000000|1.000000] "" Motor_BEV
 SG_ PSD_Segment_Komplett  : 44|1@1+ (1.000000,0.000000) [0.000000|1.000000] "" Motor_BEV
 SG_ PSD_Rampe  : 45|2@1+ (1.000000,0.000000) [0.000000|3.000000] "" Motor_BEV
 SG_ PSD_Anfangskruemmung  : 47|8@1+ (1.000000,0.000000) [0.000000|254.000000] "" Motor_BEV
 SG_ PSD_Anfangskruemmung_Vorz  : 55|1@1+ (1.000000,0.000000) [0.000000|1.000000] "" Motor_BEV
 SG_ PSD_Abzweigerichtung  : 56|1@1+ (1.000000,0.000000) [0.000000|1.000000] "" Motor_BEV
 SG_ PSD_Abzweigewinkel  : 57|7@1+ (1.417323,0.000000) [0.000000|180.000021] "" Motor_BEV

BO_ 1123 PSD_05: 8 ICAS1_Gateway
 SG_ PSD_Pos_Segment_ID  : 0|6@1+ (1.000000,0.000000) [2.000000|63.000000] "" Motor_BEV
 SG_ PSD_Pos_Segmentlaenge  : 6|7@1+ (2.000000,0.000000) [0.000000|254.000000] "Unit_Meter" Motor_BEV
 SG_ PSD_Pos_Inhibitzeit  : 13|5@1+ (10.000000,0.000000) [0.000000|310.000000] "Unit_MilliSecon" Motor_BEV
 SG_ PSD_Pos_Standort_Eindeutig  : 18|1@1+ (1.000000,0.000000) [0.000000|1.000000] "" Motor_BEV
 SG_ PSD_Pos_Fehler_Laengsrichtung  : 19|3@1+ (1.000000,0.000000) [0.000000|7.000000] "" Motor_BEV
 SG_ PSD_Pos_Fahrspur  : 22|3@1+ (1.000000,0.000000) [0.000000|7.000000] "" Motor_BEV
 SG_ PSD_Attribut_Segment_ID_05  : 25|6@1+ (1.000000,0.000000) [2.000000|63.000000] "" Motor_BEV
 SG_ PSD_Attribut_1_ID  : 31|5@1+ (1.000000,0.000000) [1.000000|31.000000] "" Motor_BEV
 SG_ PSD_Attribut_1_Wert  : 36|4@1+ (1.000000,0.000000) [0.000000|15.000000] "" Motor_BEV
 SG_ PSD_Attribut_1_Offset  : 40|7@1+ (2.000000,0.000000) [0.000000|254.000000] "Unit_Meter" Motor_BEV
 SG_ PSD_Attribut_2_ID  : 47|5@1+ (1.000000,0.000000) [1.000000|31.000000] "" Motor_BEV
 SG_ PSD_Attribut_2_Wert  : 52|4@1+ (1.000000,0.000000) [0.000000|15.000000] "" Motor_BEV
 SG_ PSD_Attribut_2_Offset  : 56|7@1+ (2.000000,0.000000) [0.000000|254.000000] "Unit_Meter" Motor_BEV
 SG_ PSD_Attribute_Komplett_05  : 63|1@1+ (1.000000,0.000000) [0.000000|1.000000] "" Motor_BEV

BO_ 1124 PSD_06: 8 ICAS1_Gateway
 SG_ PSD_06_Mux M : 0|3@1+ (1.000000,0.000000) [0.000000|7.000000] "" Motor_BEV
 SG_ PSD_Sys_Segment_ID m0 : 3|6@1+ (1.000000,0.000000) [2.000000|63.000000] "" Motor_BEV
 SG_ PSD_Attribut_Segment_ID m1 : 3|6@1+ (1.000000,0.000000) [2.000000|63.000000] "" Motor_BEV
 SG_ PSD_Ges_Segment_ID m2 : 3|6@1+ (1.000000,0.000000) [2.000000|63.000000] "" Motor_BEV
 SG_ PSD_Baum_Laenge_VZ m3 : 3|1@1+ (1.000000,0.000000) [0.000000|1.000000] "" Motor_BEV
 SG_ PSD_Steigung_1_Segment_ID m4 : 3|6@1+ (1.000000,0.000000) [2.000000|63.000000] "" Motor_BEV
 SG_ PSD_Baum_Laenge m3 : 4|25@1+ (0.000010,0.000000) [0.000000|180.000000] "Unit_DegreOfArc" Motor_BEV
 SG_ PSD_Sys_Laendercode m0 : 9|8@1+ (1.000000,0.000000) [0.000000|255.000000] "" Motor_BEV
 SG_ PSD_Attribut_3_ID m1 : 9|5@1+ (1.000000,0.000000) [1.000000|31.000000] "" Motor_BEV
 SG_ PSD_Ges_Offset m2 : 9|7@1+ (2.000000,0.000000) [0.000000|254.000000] "Unit_Meter" Motor_BEV
 SG_ PSD_Steigung_1_A_Steigung m4 : 9|7@1+ (0.120000,0.000000) [0.000000|15.000000] "Unit_PerCent" Motor_BEV
 SG_ PSD_Attribut_3_Offset m1 : 14|7@1+ (2.000000,0.000000) [0.000000|254.000000] "Unit_Meter" Motor_BEV
 SG_ PSD_Ges_Geschwindigkeit m2 : 16|5@1+ (1.000000,0.000000) [0.000000|31.000000] "" Motor_BEV
 SG_ PSD_Steigung_1_A_Vorz m4 : 16|1@1+ (1.000000,0.000000) [0.000000|1.000000] "" Motor_BEV
 SG_ PSD_Sys_Geschwindigkeit_Einheit m0 : 17|1@1+ (1.000000,0.000000) [0.000000|1.000000] "" Motor_BEV
 SG_ PSD_Steigung_1_A_Offset m4 : 17|7@1+ (2.000000,0.000000) [0.000000|254.000000] "Unit_Meter" Motor_BEV
 SG_ PSD_Sys_Verkehrsrichtung m0 : 18|1@1+ (1.000000,0.000000) [0.000000|1.000000] "" Motor_BEV
 SG_ PSD_Sys_Geometrieguete m0 : 19|2@1+ (1.000000,0.000000) [0.000000|3.000000] "" Motor_BEV
 SG_ PSD_Sys_Mapmatchingguete m0 : 21|2@1+ (1.000000,0.000000) [0.000000|3.000000] "" Motor_BEV
 SG_ PSD_Attribut_3_Wert m1 : 21|4@1+ (1.000000,0.000000) [0.000000|15.000000] "" Motor_BEV
 SG_ PSD_Ges_Typ m2 : 21|2@1+ (1.000000,0.000000) [0.000000|3.000000] "" Motor_BEV
 SG_ PSD_Sys_Alter_Karte m0 : 23|3@1+ (1.000000,0.000000) [0.000000|7.000000] "" Motor_BEV
 SG_ PSD_Ges_Spur_Geschw_Begrenzung m2 : 23|6@1+ (1.000000,0.000000) [0.000000|63.000000] "" Motor_BEV
 SG_ PSD_Steigung_1_B_Steigung m4 : 24|7@1+ (0.120000,0.000000) [0.000000|15.000000] "Unit_PerCent" Motor_BEV
 SG_ PSD_Attribut_4_ID m1 : 25|5@1+ (1.000000,0.000000) [1.000000|31.000000] "" Motor_BEV
 SG_ PSD_Sys_Zielfuehrung m0 : 26|1@1+ (1.000000,0.000000) [0.000000|1.000000] "" Motor_BEV
 SG_ PSD_Sys_US_State m0 : 27|6@1+ (1.000000,0.000000) [0.000000|63.000000] "" Motor_BEV
 SG_ PSD_Ges_Geschwindigkeit_Gespann m2 : 29|2@1+ (1.000000,0.000000) [0.000000|3.000000] "" Motor_BEV
 SG_ PSD_Baum_Breite_VZ m3 : 29|1@1+ (1.000000,0.000000) [0.000000|1.000000] "" Motor_BEV
 SG_ PSD_Attribut_4_Wert m1 : 30|4@1+ (1.000000,0.000000) [0.000000|15.000000] "" Motor_BEV
 SG_ PSD_Baum_Breite m3 : 30|24@1+ (0.000010,0.000000) [0.000000|90.000000] "Unit_DegreOfArc" Motor_BEV
 SG_ PSD_Ges_Geschwindigkeit_Witter m2 : 31|2@1+ (1.000000,0.000000) [0.000000|3.000000] "" Motor_BEV
 SG_ PSD_Steigung_1_B_Vorz m4 : 31|1@1+ (1.000000,0.000000) [0.000000|1.000000] "" Motor_BEV
 SG_ PSD_Steigung_1_B_Offset m4 : 32|7@1+ (2.000000,0.000000) [0.000000|254.000000] "Unit_Meter" Motor_BEV
 SG_ PSD_Sys_Quali_Geometrien m0 : 33|3@1+ (1.000000,0.000000) [0.000000|7.000000] "Unit_None" Vector__XXX
 SG_ PSD_Ges_Geschwindigkeit_Tag_Anf m2 : 33|3@1+ (1.000000,0.000000) [0.000000|7.000000] "" Motor_BEV
 SG_ PSD_Attribut_4_Offset m1 : 34|7@1+ (2.000000,0.000000) [0.000000|254.000000] "Unit_Meter" Motor_BEV
 SG_ PSD_Sys_Quali_Ortsinfo m0 : 36|2@1+ (1.000000,0.000000) [0.000000|3.000000] "Unit_None" Vector__XXX
 SG_ PSD_Ges_Geschwindigkeit_Tag_Ende m2 : 36|3@1+ (1.000000,0.000000) [0.000000|7.000000] "" Motor_BEV
 SG_ PSD_Sys_Quali_verfuegbar m0 : 38|1@1+ (1.000000,0.000000) [0.000000|1.000000] "" Vector__XXX
 SG_ PSD_Sys_Zielfuehrung_geaendert m0 : 39|1@1+ (1.000000,0.000000) [0.000000|1.000000] "" Motor_BEV
 SG_ PSD_Ges_Geschwindigkeit_Std_Anf m2 : 39|5@1+ (1.000000,0.000000) [0.000000|24.000000] "Unit_Hours" Motor_BEV
 SG_ PSD_Steigung_1_Attribute_kompl m4 : 39|1@1+ (1.000000,0.000000) [0.000000|1.000000] "" Motor_BEV
 SG_ PSD_Sys_Geometrieguete_erweitert m0 : 40|8@1+ (1.000000,0.000000) [0.000000|255.000000] "" Vector__XXX
 SG_ PSD_Steigung_2_Segment_ID m4 : 40|6@1+ (1.000000,0.000000) [2.000000|63.000000] "" Motor_BEV
 SG_ PSD_Attribut_5_ID m1 : 41|5@1+ (1.000000,0.000000) [1.000000|31.000000] "" Motor_BEV
 SG_ PSD_Ges_Geschwindigkeit_Std_Ende m2 : 44|5@1+ (1.000000,0.000000) [0.000000|24.000000] "Unit_Hours" Motor_BEV
 SG_ PSD_Attribut_5_Offset m1 : 46|7@1+ (2.000000,0.000000) [0.000000|254.000000] "Unit_Meter" Motor_BEV
 SG_ PSD_Steigung_2_Steigung m4 : 46|7@1+ (0.120000,0.000000) [0.000000|15.000000] "Unit_PerCent" Motor_BEV
 SG_ PSD_Sys_Quali_sonstige_Attribute m0 : 48|3@1+ (1.000000,0.000000) [0.000000|7.000000] "Unit_None" Vector__XXX
 SG_ PSD_Ges_Ueberholverbot m2 : 49|2@1+ (1.000000,0.000000) [0.000000|3.000000] "" Vector__XXX
 SG_ PSD_Sys_Quali_Steigungen m0 : 51|3@1+ (1.000000,0.000000) [0.000000|7.000000] "" Vector__XXX
 SG_ PSD_Ges_Wechselverkehrszeichen m2 : 51|3@1+ (1.000000,0.000000) [0.000000|7.000000] "" Vector__XXX
 SG_ PSD_Attribut_5_Wert m1 : 53|4@1+ (1.000000,0.000000) [0.000000|15.000000] "" Motor_BEV
 SG_ PSD_Steigung_2_Vorz m4 : 53|1@1+ (1.000000,0.000000) [0.000000|1.000000] "" Motor_BEV
 SG_ PSD_Sys_Quali_Strassenkennz m0 : 54|3@1+ (1.000000,0.000000) [0.000000|7.000000] "Unit_None" Vector__XXX
 SG_ PSD_Wechselverkehrszeichen_Typ m2 : 54|2@1+ (1.000000,0.000000) [0.000000|3.000000] "" Vector__XXX
 SG_ PSD_Baum_Ausrichtung m3 : 54|10@1+ (0.351562,0.000000) [0.000000|359.648438] "Unit_DegreOfArc" Vector__XXX
 SG_ PSD_Steigung_2_Offset m4 : 54|7@1+ (2.000000,0.000000) [0.000000|254.000000] "Unit_Meter" Motor_BEV
 SG_ PSD_Ges_Gesetzlich_Kategorie m2 : 56|3@1+ (1.000000,0.000000) [0.000000|7.000000] "" Motor_BEV
 SG_ PSD_Sys_Quali_Tempolimits m0 : 57|3@1+ (1.000000,0.000000) [0.000000|7.000000] "Unit_None" Vector__XXX
 SG_ PSD_Attribute_Komplett_06 m1 : 57|1@1+ (1.000000,0.000000) [0.000000|1.000000] "" Motor_BEV
 SG_ PSD_Ges_Gesetzlich_Zusatz m2 : 59|2@1+ (1.000000,0.000000) [0.000000|3.000000] "" Motor_BEV
 SG_ PSD_Sys_Quali_Vorfahrtsregelung m0 : 60|3@1+ (1.000000,0.000000) [0.000000|7.000000] "Unit_None" Vector__XXX
 SG_ PSD_Ges_Verkehrszeichen_Quelle m2 : 61|2@1+ (1.000000,0.000000) [0.000000|3.000000] "" Motor_BEV
 SG_ PSD_Steigung_2_Attribute_kompl m4 : 61|1@1+ (1.000000,0.000000) [0.000000|1.000000] "" Motor_BEV
 SG_ PSD_Ges_Attribute_Komplett m2 : 63|1@1+ (1.000000,0.000000) [0.000000|1.000000] "" Motor_BEV

BO_ 591 RDR1_Objekte_02: 64 ICAS1_Gateway
 SG_ RDR1_relevanter_Fehler  : 12|1@1+ (1.000000,0.000000) [0.000000|1.000000] "" Motor_BEV
 SG_ RDR1_Blindheit_erkannt  : 13|1@1+ (1.000000,0.000000) [0.000000|1.000000] "" Motor_BEV
 SG_ RDR1_relev_Nichtverfuegbarkeit  : 14|1@1+ (1.000000,0.000000) [0.000000|1.000000] "" Motor_BEV
 SG_ RDR1_Obj_01_Nummer  : 16|6@1+ (1.000000,0.000000) [0.000000|63.000000] "" Vector__XXX
 SG_ RDR1_Obj_02_Nummer  : 22|6@1+ (1.000000,0.000000) [0.000000|63.000000] "" Vector__XXX
 SG_ RDR1_Obj_03_Nummer  : 28|6@1+ (1.000000,0.000000) [0.000000|63.000000] "" Vector__XXX
 SG_ RDR1_Obj_04_Nummer  : 34|6@1+ (1.000000,0.000000) [0.000000|63.000000] "" Vector__XXX
 SG_ RDR1_Obj_05_Nummer  : 40|6@1+ (1.000000,0.000000) [0.000000|63.000000] "" Vector__XXX
 SG_ RDR1_Obj_06_Nummer  : 46|6@1+ (1.000000,0.000000) [0.000000|63.000000] "" Vector__XXX
 SG_ RDR1_Verkehrssinn  : 52|2@1+ (1.000000,0.000000) [0.000000|3.000000] "" Vector__XXX
 SG_ RDR1_Objekte_02_Datenalter  : 54|10@1+ (0.000977,0.000000) [0.000000|0.998047] "Unit_Secon" Vector__XXX
 SG_ RDR1_Obj_01_dx_v  : 64|12@1+ (0.062500,0.000000) [0.000000|255.937500] "Unit_Meter" Motor_BEV
 SG_ RDR1_Obj_01_dy_v  : 76|10@1+ (0.062500,-32.000000) [-32.000000|31.937500] "Unit_Meter" Motor_BEV
 SG_ RDR1_Obj_01_vx_v  : 86|10@1+ (0.250000,-128.000000) [-128.000000|127.750000] "Unit_MeterPerSecon" Motor_BEV
 SG_ RDR1_Obj_02_dx_v  : 96|12@1+ (0.062500,0.000000) [0.000000|255.937500] "Unit_Meter" Vector__XXX
 SG_ RDR1_Obj_02_dy_v  : 108|10@1+ (0.062500,-32.000000) [-32.000000|31.937500] "Unit_Meter" Vector__XXX
 SG_ RDR1_Obj_02_vx_v  : 118|10@1+ (0.250000,-128.000000) [-128.000000|127.750000] "Unit_MeterPerSecon" Vector__XXX
 SG_ RDR1_Obj_03_dx_v  : 128|12@1+ (0.062500,0.000000) [0.000000|255.937500] "Unit_Meter" Vector__XXX
 SG_ RDR1_Obj_03_dy_v  : 140|10@1+ (0.062500,-32.000000) [-32.000000|31.937500] "Unit_Meter" Vector__XXX
 SG_ RDR1_Obj_03_vx_v  : 150|10@1+ (0.250000,-128.000000) [-128.000000|127.750000] "Unit_MeterPerSecon" Vector__XXX
 SG_ RDR1_Obj_04_dx_v  : 160|12@1+ (0.062500,0.000000) [0.000000|255.937500] "Unit_Meter" Motor_BEV
 SG_ RDR1_Obj_04_dy_v  : 172|10@1+ (0.062500,-32.000000) [-32.000000|31.937500] "Unit_Meter" Vector__XXX
 SG_ RDR1_Obj_04_vx_v  : 182|10@1+ (0.250000,-128.000000) [-128.000000|127.750000] "Unit_MeterPerSecon" Motor_BEV
 SG_ RDR1_Obj_05_dx_v  : 192|12@1+ (0.062500,0.000000) [0.000000|255.937500] "Unit_Meter" Vector__XXX
 SG_ RDR1_Obj_05_dy_v  : 204|10@1+ (0.062500,-32.000000) [-32.000000|31.937500] "Unit_Meter" Vector__XXX
 SG_ RDR1_Obj_05_vx_v  : 214|10@1+ (0.250000,-128.000000) [-128.000000|127.750000] "Unit_MeterPerSecon" Vector__XXX
 SG_ RDR1_Obj_06_dx_v  : 224|12@1+ (0.062500,0.000000) [0.000000|255.937500] "Unit_Meter" Vector__XXX
 SG_ RDR1_Obj_06_dy_v  : 236|10@1+ (0.062500,-32.000000) [-32.000000|31.937500] "Unit_Meter" Vector__XXX
 SG_ RDR1_Obj_06_vx_v  : 246|10@1+ (0.250000,-128.000000) [-128.000000|127.750000] "Unit_MeterPerSecon" Vector__XXX
 SG_ RDR1_Obj_01_ax_v  : 256|8@1+ (0.125000,-16.000000) [-16.000000|15.750000] "Unit_MeterPerSeconSquar" Motor_BEV
 SG_ RDR1_Obj_01_ax_StdA  : 264|6@1+ (0.125000,0.000000) [0.000000|7.750000] "Unit_MeterPerSeconSquar" Motor_BEV
 SG_ RDR1_Obj_01_vx_StdA  : 270|7@1+ (0.031250,0.000000) [0.000000|3.937500] "Unit_MeterPerSecon" Motor_BEV
 SG_ RDR1_Obj_01_dx_StdA  : 277|7@1+ (0.050000,0.000000) [0.000000|6.300000] "Unit_Meter" Motor_BEV
 SG_ RDR1_Obj_01_dy_StdA  : 284|7@1+ (0.062500,0.000000) [0.000000|7.875000] "Unit_Meter" Motor_BEV

BO_ 2033 Request_Airbag_Deployment: 8 ICAS1_Gateway
 SG_ Request_Airbag_Deployment  : 0|64@1+ (1.000000,0.000000) [0.000000|18446744073709551616.000000] "" Airbag

BO_ 2041 Response_Airbag_Deployment: 8 Airbag
 SG_ Response_Airbag_Deployment  : 0|64@1+ (1.000000,0.000000) [0.000000|18446744073709551616.000000] "" ICAS1_Gateway

BU_:  Airbag BAP_Tester ICAS1_Gateway ICAS1_KommunikationsServer LE1 LE2 Motor_BEV Schaltbetaetigung

BO_ 2463978709 OCC_02: 32 ICAS1_Gateway
 SG_ OCC_CP_Tastgrad_A  : 12|10@1+ (0.100000,0.000000) [0.000000|100.000000] "Unit_PerCent" Vector__XXX
 SG_ OCC_CP_Tastgrad_B  : 22|10@1+ (0.100000,0.000000) [0.000000|100.000000] "Unit_PerCent" Vector__XXX
 SG_ OCC_CP_Frequenz_A  : 32|8@1+ (1.000000,880.000000) [880.000000|1132.000000] "Unit_Hertz" Vector__XXX
 SG_ OCC_CP_Frequenz_B  : 40|8@1+ (1.000000,880.000000) [880.000000|1132.000000] "Unit_Hertz" Vector__XXX
 SG_ OCC_CP_Spannung_A  : 48|9@1+ (0.100000,-25.000000) [-25.000000|25.900000] "Unit_Volt" Vector__XXX
 SG_ OCC_CP_Spannung_B  : 57|9@1+ (0.100000,-25.000000) [-25.000000|25.900000] "Unit_Volt" Vector__XXX
 SG_ OCC_CP_Fehlerstatus_A  : 66|3@1+ (1.000000,0.000000) [0.000000|7.000000] "" Vector__XXX
 SG_ OCC_CP_Fehlerstatus_B  : 69|3@1+ (1.000000,0.000000) [0.000000|7.000000] "" Vector__XXX
 SG_ OCC_Temp_Ladedose_A_AC  : 72|8@1+ (1.000000,-40.000000) [-40.000000|213.000000] "Unit_DegreCelsi" Vector__XXX
 SG_ OCC_Temp_Ladedose_A_DC_minus  : 80|8@1+ (1.000000,-40.000000) [-40.000000|213.000000] "Unit_DegreCelsi" Vector__XXX
 SG_ OCC_Temp_Ladedose_A_DC_plus  : 88|8@1+ (1.000000,-40.000000) [-40.000000|213.000000] "Unit_DegreCelsi" Vector__XXX
 SG_ OCC_U_istAC_Netz_L1  : 96|9@1+ (1.000000,0.000000) [0.000000|509.000000] "Unit_Volt" Vector__XXX
 SG_ OCC_U_istAC_Netz_L2  : 105|9@1+ (1.000000,0.000000) [0.000000|509.000000] "Unit_Volt" Vector__XXX
 SG_ OCC_U_istAC_Netz_L3  : 114|9@1+ (1.000000,0.000000) [0.000000|508.000000] "Unit_Volt" Vector__XXX
 SG_ OCC_StatusVerEntriegelungAktor_A  : 123|3@1+ (1.000000,0.000000) [0.000000|7.000000] "" Vector__XXX
 SG_ OCC_SteckerEntriegelung_Verbot_A  : 126|2@1+ (1.000000,0.000000) [0.000000|3.000000] "" Vector__XXX
 SG_ OCC_StatusVerEntriegelungAktor_B  : 128|3@1+ (1.000000,0.000000) [0.000000|7.000000] "" Vector__XXX
 SG_ OCC_SteckerEntriegelung_Verbot_B  : 131|2@1+ (1.000000,0.000000) [0.000000|3.000000] "" Vector__XXX
 SG_ OCC_Verriegelung_Status_A  : 133|3@1+ (1.000000,0.000000) [0.000000|7.000000] "" Vector__XXX
 SG_ OCC_Verriegelung_Status_B  : 136|3@1+ (1.000000,0.000000) [0.000000|7.000000] "" Vector__XXX
 SG_ OCC_RtmWarnLadeKommunikation  : 139|3@1+ (1.000000,0.000000) [0.000000|7.000000] "" Vector__XXX
 SG_ OCC_Ist_Wirkungsgrad  : 145|7@1+ (1.000000,0.000000) [0.000000|100.000000] "Unit_PerCent" Vector__XXX
 SG_ OCC_PP_Max_Strom_A  : 152|4@1+ (1.000000,0.000000) [0.000000|15.000000] "" Vector__XXX
 SG_ OCC_PP_Max_Strom_B  : 156|4@1+ (1.000000,0.000000) [0.000000|15.000000] "" Vector__XXX
 SG_ OCC_DC_MaxStrom  : 160|11@1+ (0.100000,0.000000) [0.000000|204.500000] "Unit_Amper" Vector__XXX
 SG_ OCC_Derating_Temperatur  : 171|1@1+ (1.000000,0.000000) [0.000000|1.000000] "" Vector__XXX
 SG_ OCC_Fehlerzustand  : 172|1@1+ (1.000000,0.000000) [0.000000|1.000000] "" Vector__XXX
 SG_ OCC_Ladest_Entriegelungs_Verbot  : 173|3@1+ (1.000000,0.000000) [0.000000|7.000000] "" Vector__XXX
 SG_ OCC_Netzfrequenz_EVU  : 176|9@1+ (0.100000,40.000000) [40.000000|80.000000] "Unit_Hertz" Vector__XXX
 SG_ OCC_Warnzustand  : 185|1@1+ (1.000000,0.000000) [0.000000|1.000000] "" Vector__XXX
 SG_ OCC_Kuehltemperatur  : 192|8@1+ (1.000000,-40.000000) [-40.000000|213.000000] "Unit_DegreCelsi" Motor_BEV
 SG_ OCC_PP_Fehlerstatus_A  : 200|4@1+ (1.000000,0.000000) [0.000000|15.000000] "" Vector__XXX
 SG_ OCC_PP_Fehlerstatus_B  : 204|4@1+ (1.000000,0.000000) [0.000000|15.000000] "" Vector__XXX

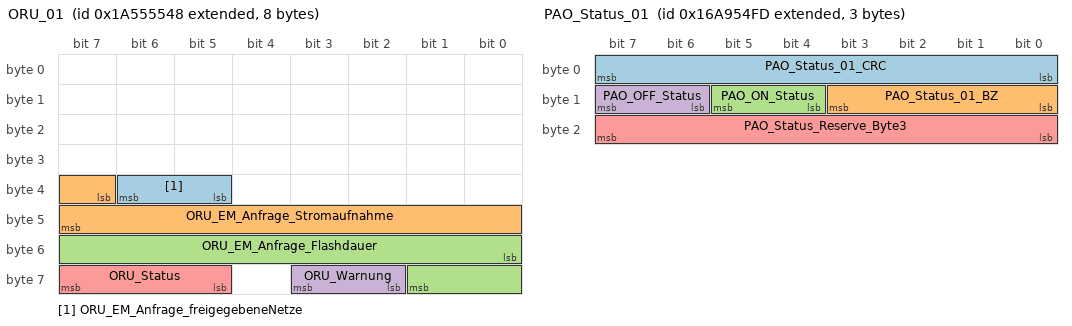
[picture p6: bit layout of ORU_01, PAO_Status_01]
BO_ 2589283656 ORU_01: 8 ICAS1_Gateway
 SG_ ORU_EM_Anfrage_freigegebeneNetze  : 37|2@1+ (1.000000,0.000000) [0.000000|3.000000] "" Vector__XXX
 SG_ ORU_EM_Anfrage_Stromaufnahme  : 39|9@1+ (0.100000,0.000000) [0.000000|51.100000] "Unit_Amper" Vector__XXX
 SG_ ORU_EM_Anfrage_Flashdauer  : 48|10@1+ (10.000000,0.000000) [0.000000|10230.000000] "Unit_Secon" Vector__XXX
 SG_ ORU_Warnung  : 58|2@1+ (1.000000,0.000000) [0.000000|3.000000] "" Vector__XXX
 SG_ ORU_Status  : 61|3@1+ (1.000000,0.000000) [0.000000|7.000000] "" Airbag LE1 LE2 Motor_BEV

BO_ 2527679741 PAO_Status_01: 3 ICAS1_Gateway
 SG_ PAO_Status_01_CRC  : 0|8@1+ (1.000000,0.000000) [0.000000|255.000000] "" Airbag
 SG_ PAO_Status_01_BZ  : 8|4@1+ (1.000000,0.000000) [0.000000|15.000000] "" Airbag
 SG_ PAO_ON_Status  : 12|2@1+ (1.000000,0.000000) [0.000000|3.000000] "" Airbag
 SG_ PAO_OFF_Status  : 14|2@1+ (1.000000,0.000000) [0.000000|3.000000] "" Airbag
 SG_ PAO_Status_Reserve_Byte3  : 16|8@1+ (1.000000,0.000000) [0.000000|255.000000] "" Vector__XXX

BO_ 518 Parken_01: 24 ICAS1_Gateway
 SG_ Parken_BKD_Anf  : 12|4@1+ (0.100000,0.000000) [0.000000|1.300000] "Unit_Secon" Vector__XXX
 SG_ Parken_Verz_Anf  : 16|7@1+ (0.100000,-12.600000) [-12.600000|-0.100000] "Unit_MeterPerSeconSquar" Vector__XXX
 SG_ Parken_Prefill_Anf  : 23|1@1+ (1.000000,0.000000) [0.000000|1.000000] "" Vector__XXX
 SG_ Parken_Warnruck_Anf  : 24|2@1+ (1.000000,0.000000) [0.000000|3.000000] "" Vector__XXX
 SG_ Parken_Verz_Anf_ASIL  : 26|2@1+ (1.000000,0.000000) [0.000000|3.000000] "" Vector__XXX
 SG_ Parken_Warnruckeln_Anf  : 28|2@1+ (1.000000,0.000000) [0.000000|3.000000] "" Vector__XXX
 SG_ Parken_beibehalten  : 30|2@1+ (1.000000,0.000000) [0.000000|3.000000] "" Vector__XXX
 SG_ Parken_Anforderung_HMS  : 32|3@1+ (1.000000,0.000000) [0.000000|7.000000] "" Vector__XXX
 SG_ Parken_Notstopp_Anf  : 40|2@1+ (1.000000,0.000000) [0.000000|3.000000] "" Vector__XXX
 SG_ Parken_Anhalteweg_Anf  : 42|10@1+ (0.010000,0.000000) [0.000000|10.210000] "Unit_Meter" Vector__XXX
 SG_ Parken_aktives_System  : 52|4@1+ (1.000000,0.000000) [0.000000|15.000000] "" Motor_BEV
 SG_ Parken_max_Beschleunigung  : 56|7@1+ (0.100000,-6.000000) [-5.900000|6.100000] "Unit_MeterPerSeconSquar" Motor_BEV
 SG_ Parken_Blinker_li_Anf  : 63|1@1+ (1.000000,0.000000) [0.000000|1.000000] "" Vector__XXX
 SG_ Parken_QFK_KruemmSoll  : 64|15@1+ (0.000007,0.000000) [0.000000|0.219539] "Unit_MeterInver" Vector__XXX
 SG_ Parken_QFK_KruemmSoll_VZ  : 79|1@1+ (1.000000,0.000000) [0.000000|1.000000] "" Vector__XXX
 SG_ Parken_QFK_Spuerb  : 80|8@1+ (0.400000,0.000000) [0.000000|100.000000] "Unit_PerCent" Vector__XXX
 SG_ Parken_QFK_AnfStat  : 88|4@1+ (1.000000,0.000000) [0.000000|15.000000] "" Vector__XXX
 SG_ Parken_QFK_Signal1  : 92|10@1+ (1.000000,0.000000) [0.000000|1023.000000] "" Vector__XXX
 SG_ Parken_QFK_Art1  : 102|3@1+ (1.000000,0.000000) [0.000000|7.000000] "" Vector__XXX
 SG_ Parken_QFK_Art2  : 105|3@1+ (1.000000,0.000000) [0.000000|7.000000] "" Vector__XXX
 SG_ Parken_QFK_Signal2  : 108|10@1+ (1.000000,0.000000) [0.000000|1023.000000] "" Vector__XXX
 SG_ Parken_Sollbeschleunigung  : 118|9@1+ (0.010000,-4.110000) [-4.100000|1.000000] "Unit_MeterPerSeconSquar" Motor_BEV
 SG_ Parken_Blinker_re_Anf  : 127|1@1+ (1.000000,0.000000) [0.000000|1.000000] "" Vector__XXX
 SG_ Parken_Status_IPA_TSK  : 128|4@1+ (1.000000,0.000000) [0.000000|15.000000] "" Motor_BEV
 SG_ Parken_erhoehtes_Moment  : 132|4@1+ (1.000000,0.000000) [0.000000|15.000000] "" Motor_BEV
 SG_ Parken_max_Geschwindigkeit  : 136|8@1+ (0.100000,0.000000) [0.100000|25.000000] "Unit_KiloMeterPerHour" Motor_BEV
 SG_ Parken_Soll_Anhalteweg_Anf  : 144|10@1+ (0.010000,0.000000) [0.000000|10.210000] "Unit_Meter" Vector__XXX
 SG_ Parken_Fahrstufenwunsch  : 154|3@1+ (1.000000,0.000000) [0.000000|7.000000] "" Motor_BEV
 SG_ IPA_TPA_Remote  : 157|2@1+ (1.000000,0.000000) [0.000000|3.000000] "" Vector__XXX
 SG_ IPA_TPA_Remote_Anf  : 159|1@1+ (1.000000,0.000000) [0.000000|1.000000] "" Vector__XXX
 SG_ IPA_TPA_Fehler  : 160|4@1+ (1.000000,0.000000) [0.000000|15.000000] "" Vector__XXX
 SG_ IPA_TPA_Abbruch  : 164|4@1+ (1.000000,0.000000) [0.000000|15.000000] "" Vector__XXX
 SG_ IPA_TPA_Status  : 168|4@1+ (1.000000,0.000000) [0.000000|15.000000] "" Vector__XXX

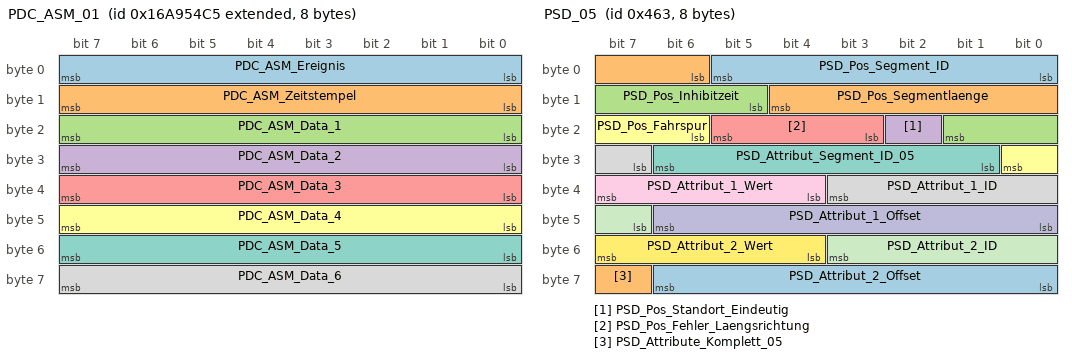
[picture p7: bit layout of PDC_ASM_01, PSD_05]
BO_ 2527679685 PDC_ASM_01: 8 ICAS1_Gateway
 SG_ PDC_ASM_Ereignis  : 0|8@1+ (1.000000,0.000000) [1.000000|254.000000] "" Airbag
 SG_ PDC_ASM_Zeitstempel  : 8|8@1+ (0.080000,0.000000) [0.000000|20.320000] "Unit_Secon" Airbag
 SG_ PDC_ASM_Data_1  : 16|8@1+ (1.000000,0.000000) [0.000000|255.000000] "" Airbag
 SG_ PDC_ASM_Data_2  : 24|8@1+ (1.000000,0.000000) [0.000000|255.000000] "" Airbag
 SG_ PDC_ASM_Data_3  : 32|8@1+ (1.000000,0.000000) [0.000000|255.000000] "" Airbag
 SG_ PDC_ASM_Data_4  : 40|8@1+ (1.000000,0.000000) [0.000000|255.000000] "" Airbag
 SG_ PDC_ASM_Data_5  : 48|8@1+ (1.000000,0.000000) [0.000000|255.000000] "" Airbag
 SG_ PDC_ASM_Data_6  : 56|8@1+ (1.000000,0.000000) [0.000000|255.000000] "" Airbag

BO_ 319 PreCrash_02: 8 Airbag
 SG_ PreCrash_Charisma_FahrPr  : 12|4@1+ (1.000000,0.000000) [0.000000|15.000000] "" ICAS1_Gateway
 SG_ PreCrash_Charisma_Status  : 16|2@1+ (1.000000,0.000000) [0.000000|3.000000] "" ICAS1_Gateway
 SG_ PreCrash_Schiebedach_schliessen  : 18|1@1+ (1.000000,0.000000) [0.000000|1.000000] "" ICAS1_Gateway
 SG_ PreCrash_Fenster_schliessen  : 19|1@1+ (1.000000,0.000000) [0.000000|1.000000] "" ICAS1_Gateway
 SG_ PreCrash_Blinken  : 20|3@1+ (1.000000,0.000000) [0.000000|7.000000] "" ICAS1_Gateway
 SG_ SC_PreSense_FCWP  : 23|1@1+ (1.000000,0.000000) [0.000000|1.000000] "" ICAS1_Gateway
 SG_ PreCrash_Tueren_Verriegeln  : 24|1@1+ (1.000000,0.000000) [0.000000|1.000000] "" ICAS1_Gateway
 SG_ PreCrash_FS_Laengsverstellung  : 25|1@1+ (1.000000,0.000000) [0.000000|1.000000] "" ICAS1_Gateway
 SG_ PreCrash_Anforderung_AFR  : 26|3@1+ (1.000000,0.000000) [0.000000|7.000000] "" ICAS1_Gateway
 SG_ SC_PreCrash_LED  : 29|2@1+ (1.000000,0.000000) [0.000000|3.000000] "" ICAS1_Gateway
 SG_ PreCrash_FS_Pneumatik_ansteuern  : 31|1@1+ (1.000000,0.000000) [0.000000|1.000000] "" ICAS1_Gateway
 SG_ PreCrash_BFS_Pneumatik_ansteuern  : 32|1@1+ (1.000000,0.000000) [0.000000|1.000000] "" ICAS1_Gateway
 SG_ PreCrash_Fo_Pneumatik_ansteuern  : 33|1@1+ (1.000000,0.000000) [0.000000|1.000000] "" ICAS1_Gateway
 SG_ PreCrash_FS_Sitzlehne_verfahren  : 34|3@1+ (1.000000,0.000000) [0.000000|7.000000] "" ICAS1_Gateway
 SG_ PreCrash_BFS_Sitzlehne_verfahren  : 37|3@1+ (1.000000,0.000000) [0.000000|7.000000] "" ICAS1_Gateway
 SG_ PreCrash_Fo_Sitzlehne_verfahren  : 40|3@1+ (1.000000,0.000000) [0.000000|7.000000] "" ICAS1_Gateway
 SG_ PreCrash_FS_KSV_verfahren  : 43|4@1+ (1.000000,0.000000) [0.000000|15.000000] "" ICAS1_Gateway
 SG_ PreCrash_BFS_KSV_verfahren  : 47|4@1+ (1.000000,0.000000) [0.000000|15.000000] "" ICAS1_Gateway
 SG_ PreCrash_Fo_KSV_verfahren  : 51|4@1+ (1.000000,0.000000) [0.000000|15.000000] "" ICAS1_Gateway
 SG_ PreCrash_BFS_Laengsverstellung  : 55|1@1+ (1.000000,0.000000) [0.000000|1.000000] "" ICAS1_Gateway
 SG_ SC_PreCrash_Warnung  : 56|4@1+ (1.000000,0.000000) [0.000000|15.000000] "" ICAS1_Gateway ICAS1_KommunikationsServer
 SG_ SC_PreCrash_Texte  : 60|4@1+ (1.000000,0.000000) [0.000000|15.000000] "" ICAS1_Gateway ICAS1_KommunikationsServer

BO_ 1122 PSD_04: 8 ICAS1_Gateway
 SG_ PSD_Segment_ID  : 0|6@1+ (1.000000,0.000000) [2.000000|63.000000] "" Motor_BEV
 SG_ PSD_Vorgaenger_Segment_ID  : 6|6@1+ (1.000000,0.000000) [2.000000|63.000000] "" Motor_BEV
 SG_ PSD_Segmentlaenge  : 12|7@1+ (2.000000,0.000000) [0.000000|254.000000] "Unit_Meter" Motor_BEV
 SG_ PSD_Strassenkategorie  : 19|3@1+ (1.000000,0.000000) [0.000000|7.000000] "" Motor_BEV
 SG_ PSD_Endkruemmung  : 22|8@1+ (1.000000,0.000000) [0.000000|254.000000] "Unit_None" Motor_BEV
 SG_ PSD_Endkruemmung_Vorz  : 30|1@1+ (1.000000,0.000000) [0.000000|1.000000] "" Motor_BEV
 SG_ PSD_Idenditaets_ID  : 31|6@1+ (1.000000,0.000000) [2.000000|63.000000] "" Vector__XXX
 SG_ PSD_ADAS_Qualitaet  : 37|1@1+ (1.000000,0.000000) [0.000000|1.000000] "" Motor_BEV
 SG_ PSD_wahrscheinlichster_Pfad  : 38|1@1+ (1.000000,0.000000) [0.000000|1.000000] "" Motor_BEV
 SG_ PSD_Geradester_Pfad  : 39|1@1+ (1.000000,0.000000) [0.000000|1.000000] "" Motor_BEV
 SG_ PSD_Fahrspuren_Anzahl  : 40|3@1+ (1.000000,0.000000) [0.000000|7.000000] "" Motor_BEV
 SG_ PSD_Bebauung  : 43|1@1+ (1.000000,0.000000) [0.000000|1.000000] "" Motor_BEV
 SG_ PSD_Segment_Komplett  : 44|1@1+ (1.000000,0.000000) [0.000000|1.000000] "" Motor_BEV
 SG_ PSD_Rampe  : 45|2@1+ (1.000000,0.000000) [0.000000|3.000000] "" Motor_BEV
 SG_ PSD_Anfangskruemmung  : 47|8@1+ (1.000000,0.000000) [0.000000|254.000000] "" Motor_BEV
 SG_ PSD_Anfangskruemmung_Vorz  : 55|1@1+ (1.000000,0.000000) [0.000000|1.000000] "" Motor_BEV
 SG_ PSD_Abzweigerichtung  : 56|1@1+ (1.000000,0.000000) [0.000000|1.000000] "" Motor_BEV
 SG_ PSD_Abzweigewinkel  : 57|7@1+ (1.417323,0.000000) [0.000000|180.000021] "" Motor_BEV

BO_ 1123 PSD_05: 8 ICAS1_Gateway
 SG_ PSD_Pos_Segment_ID  : 0|6@1+ (1.000000,0.000000) [2.000000|63.000000] "" Motor_BEV
 SG_ PSD_Pos_Segmentlaenge  : 6|7@1+ (2.000000,0.000000) [0.000000|254.000000] "Unit_Meter" Motor_BEV
 SG_ PSD_Pos_Inhibitzeit  : 13|5@1+ (10.000000,0.000000) [0.000000|310.000000] "Unit_MilliSecon" Motor_BEV
 SG_ PSD_Pos_Standort_Eindeutig  : 18|1@1+ (1.000000,0.000000) [0.000000|1.000000] "" Motor_BEV
 SG_ PSD_Pos_Fehler_Laengsrichtung  : 19|3@1+ (1.000000,0.000000) [0.000000|7.000000] "" Motor_BEV
 SG_ PSD_Pos_Fahrspur  : 22|3@1+ (1.000000,0.000000) [0.000000|7.000000] "" Motor_BEV
 SG_ PSD_Attribut_Segment_ID_05  : 25|6@1+ (1.000000,0.000000) [2.000000|63.000000] "" Motor_BEV
 SG_ PSD_Attribut_1_ID  : 31|5@1+ (1.000000,0.000000) [1.000000|31.000000] "" Motor_BEV
 SG_ PSD_Attribut_1_Wert  : 36|4@1+ (1.000000,0.000000) [0.000000|15.000000] "" Motor_BEV
 SG_ PSD_Attribut_1_Offset  : 40|7@1+ (2.000000,0.000000) [0.000000|254.000000] "Unit_Meter" Motor_BEV
 SG_ PSD_Attribut_2_ID  : 47|5@1+ (1.000000,0.000000) [1.000000|31.000000] "" Motor_BEV
 SG_ PSD_Attribut_2_Wert  : 52|4@1+ (1.000000,0.000000) [0.000000|15.000000] "" Motor_BEV
 SG_ PSD_Attribut_2_Offset  : 56|7@1+ (2.000000,0.000000) [0.000000|254.000000] "Unit_Meter" Motor_BEV
 SG_ PSD_Attribute_Komplett_05  : 63|1@1+ (1.000000,0.000000) [0.000000|1.000000] "" Motor_BEV

BO_ 1124 PSD_06: 8 ICAS1_Gateway
 SG_ PSD_06_Mux M : 0|3@1+ (1.000000,0.000000) [0.000000|7.000000] "" Motor_BEV
 SG_ PSD_Sys_Segment_ID m0 : 3|6@1+ (1.000000,0.000000) [2.000000|63.000000] "" Motor_BEV
 SG_ PSD_Attribut_Segment_ID m1 : 3|6@1+ (1.000000,0.000000) [2.000000|63.000000] "" Motor_BEV
 SG_ PSD_Ges_Segment_ID m2 : 3|6@1+ (1.000000,0.000000) [2.000000|63.000000] "" Motor_BEV
 SG_ PSD_Baum_Laenge_VZ m3 : 3|1@1+ (1.000000,0.000000) [0.000000|1.000000] "" Motor_BEV
 SG_ PSD_Steigung_1_Segment_ID m4 : 3|6@1+ (1.000000,0.000000) [2.000000|63.000000] "" Motor_BEV
 SG_ PSD_Baum_Laenge m3 : 4|25@1+ (0.000010,0.000000) [0.000000|180.000000] "Unit_DegreOfArc" Motor_BEV
 SG_ PSD_Sys_Laendercode m0 : 9|8@1+ (1.000000,0.000000) [0.000000|255.000000] "" Motor_BEV
 SG_ PSD_Attribut_3_ID m1 : 9|5@1+ (1.000000,0.000000) [1.000000|31.000000] "" Motor_BEV
 SG_ PSD_Ges_Offset m2 : 9|7@1+ (2.000000,0.000000) [0.000000|254.000000] "Unit_Meter" Motor_BEV
 SG_ PSD_Steigung_1_A_Steigung m4 : 9|7@1+ (0.120000,0.000000) [0.000000|15.000000] "Unit_PerCent" Motor_BEV
 SG_ PSD_Attribut_3_Offset m1 : 14|7@1+ (2.000000,0.000000) [0.000000|254.000000] "Unit_Meter" Motor_BEV
 SG_ PSD_Ges_Geschwindigkeit m2 : 16|5@1+ (1.000000,0.000000) [0.000000|31.000000] "" Motor_BEV
 SG_ PSD_Steigung_1_A_Vorz m4 : 16|1@1+ (1.000000,0.000000) [0.000000|1.000000] "" Motor_BEV
 SG_ PSD_Sys_Geschwindigkeit_Einheit m0 : 17|1@1+ (1.000000,0.000000) [0.000000|1.000000] "" Motor_BEV
 SG_ PSD_Steigung_1_A_Offset m4 : 17|7@1+ (2.000000,0.000000) [0.000000|254.000000] "Unit_Meter" Motor_BEV
 SG_ PSD_Sys_Verkehrsrichtung m0 : 18|1@1+ (1.000000,0.000000) [0.000000|1.000000] "" Motor_BEV
 SG_ PSD_Sys_Geometrieguete m0 : 19|2@1+ (1.000000,0.000000) [0.000000|3.000000] "" Motor_BEV
 SG_ PSD_Sys_Mapmatchingguete m0 : 21|2@1+ (1.000000,0.000000) [0.000000|3.000000] "" Motor_BEV
 SG_ PSD_Attribut_3_Wert m1 : 21|4@1+ (1.000000,0.000000) [0.000000|15.000000] "" Motor_BEV
 SG_ PSD_Ges_Typ m2 : 21|2@1+ (1.000000,0.000000) [0.000000|3.000000] "" Motor_BEV
 SG_ PSD_Sys_Alter_Karte m0 : 23|3@1+ (1.000000,0.000000) [0.000000|7.000000] "" Motor_BEV
 SG_ PSD_Ges_Spur_Geschw_Begrenzung m2 : 23|6@1+ (1.000000,0.000000) [0.000000|63.000000] "" Motor_BEV
 SG_ PSD_Steigung_1_B_Steigung m4 : 24|7@1+ (0.120000,0.000000) [0.000000|15.000000] "Unit_PerCent" Motor_BEV
 SG_ PSD_Attribut_4_ID m1 : 25|5@1+ (1.000000,0.000000) [1.000000|31.000000] "" Motor_BEV
 SG_ PSD_Sys_Zielfuehrung m0 : 26|1@1+ (1.000000,0.000000) [0.000000|1.000000] "" Motor_BEV
 SG_ PSD_Sys_US_State m0 : 27|6@1+ (1.000000,0.000000) [0.000000|63.000000] "" Motor_BEV
 SG_ PSD_Ges_Geschwindigkeit_Gespann m2 : 29|2@1+ (1.000000,0.000000) [0.000000|3.000000] "" Motor_BEV
 SG_ PSD_Baum_Breite_VZ m3 : 29|1@1+ (1.000000,0.000000) [0.000000|1.000000] "" Motor_BEV
 SG_ PSD_Attribut_4_Wert m1 : 30|4@1+ (1.000000,0.000000) [0.000000|15.000000] "" Motor_BEV
 SG_ PSD_Baum_Breite m3 : 30|24@1+ (0.000010,0.000000) [0.000000|90.000000] "Unit_DegreOfArc" Motor_BEV
 SG_ PSD_Ges_Geschwindigkeit_Witter m2 : 31|2@1+ (1.000000,0.000000) [0.000000|3.000000] "" Motor_BEV
 SG_ PSD_Steigung_1_B_Vorz m4 : 31|1@1+ (1.000000,0.000000) [0.000000|1.000000] "" Motor_BEV
 SG_ PSD_Steigung_1_B_Offset m4 : 32|7@1+ (2.000000,0.000000) [0.000000|254.000000] "Unit_Meter" Motor_BEV
 SG_ PSD_Sys_Quali_Geometrien m0 : 33|3@1+ (1.000000,0.000000) [0.000000|7.000000] "Unit_None" Vector__XXX
 SG_ PSD_Ges_Geschwindigkeit_Tag_Anf m2 : 33|3@1+ (1.000000,0.000000) [0.000000|7.000000] "" Motor_BEV
 SG_ PSD_Attribut_4_Offset m1 : 34|7@1+ (2.000000,0.000000) [0.000000|254.000000] "Unit_Meter" Motor_BEV
 SG_ PSD_Sys_Quali_Ortsinfo m0 : 36|2@1+ (1.000000,0.000000) [0.000000|3.000000] "Unit_None" Vector__XXX
 SG_ PSD_Ges_Geschwindigkeit_Tag_Ende m2 : 36|3@1+ (1.000000,0.000000) [0.000000|7.000000] "" Motor_BEV
 SG_ PSD_Sys_Quali_verfuegbar m0 : 38|1@1+ (1.000000,0.000000) [0.000000|1.000000] "" Vector__XXX
 SG_ PSD_Sys_Zielfuehrung_geaendert m0 : 39|1@1+ (1.000000,0.000000) [0.000000|1.000000] "" Motor_BEV
 SG_ PSD_Ges_Geschwindigkeit_Std_Anf m2 : 39|5@1+ (1.000000,0.000000) [0.000000|24.000000] "Unit_Hours" Motor_BEV
 SG_ PSD_Steigung_1_Attribute_kompl m4 : 39|1@1+ (1.000000,0.000000) [0.000000|1.000000] "" Motor_BEV
 SG_ PSD_Sys_Geometrieguete_erweitert m0 : 40|8@1+ (1.000000,0.000000) [0.000000|255.000000] "" Vector__XXX
 SG_ PSD_Steigung_2_Segment_ID m4 : 40|6@1+ (1.000000,0.000000) [2.000000|63.000000] "" Motor_BEV
 SG_ PSD_Attribut_5_ID m1 : 41|5@1+ (1.000000,0.000000) [1.000000|31.000000] "" Motor_BEV
 SG_ PSD_Ges_Geschwindigkeit_Std_Ende m2 : 44|5@1+ (1.000000,0.000000) [0.000000|24.000000] "Unit_Hours" Motor_BEV
 SG_ PSD_Attribut_5_Offset m1 : 46|7@1+ (2.000000,0.000000) [0.000000|254.000000] "Unit_Meter" Motor_BEV
 SG_ PSD_Steigung_2_Steigung m4 : 46|7@1+ (0.120000,0.000000) [0.000000|15.000000] "Unit_PerCent" Motor_BEV
 SG_ PSD_Sys_Quali_sonstige_Attribute m0 : 48|3@1+ (1.000000,0.000000) [0.000000|7.000000] "Unit_None" Vector__XXX
 SG_ PSD_Ges_Ueberholverbot m2 : 49|2@1+ (1.000000,0.000000) [0.000000|3.000000] "" Vector__XXX
 SG_ PSD_Sys_Quali_Steigungen m0 : 51|3@1+ (1.000000,0.000000) [0.000000|7.000000] "" Vector__XXX
 SG_ PSD_Ges_Wechselverkehrszeichen m2 : 51|3@1+ (1.000000,0.000000) [0.000000|7.000000] "" Vector__XXX
 SG_ PSD_Attribut_5_Wert m1 : 53|4@1+ (1.000000,0.000000) [0.000000|15.000000] "" Motor_BEV
 SG_ PSD_Steigung_2_Vorz m4 : 53|1@1+ (1.000000,0.000000) [0.000000|1.000000] "" Motor_BEV
 SG_ PSD_Sys_Quali_Strassenkennz m0 : 54|3@1+ (1.000000,0.000000) [0.000000|7.000000] "Unit_None" Vector__XXX
 SG_ PSD_Wechselverkehrszeichen_Typ m2 : 54|2@1+ (1.000000,0.000000) [0.000000|3.000000] "" Vector__XXX
 SG_ PSD_Baum_Ausrichtung m3 : 54|10@1+ (0.351562,0.000000) [0.000000|359.648438] "Unit_DegreOfArc" Vector__XXX
 SG_ PSD_Steigung_2_Offset m4 : 54|7@1+ (2.000000,0.000000) [0.000000|254.000000] "Unit_Meter" Motor_BEV
 SG_ PSD_Ges_Gesetzlich_Kategorie m2 : 56|3@1+ (1.000000,0.000000) [0.000000|7.000000] "" Motor_BEV
 SG_ PSD_Sys_Quali_Tempolimits m0 : 57|3@1+ (1.000000,0.000000) [0.000000|7.000000] "Unit_None" Vector__XXX
 SG_ PSD_Attribute_Komplett_06 m1 : 57|1@1+ (1.000000,0.000000) [0.000000|1.000000] "" Motor_BEV
 SG_ PSD_Ges_Gesetzlich_Zusatz m2 : 59|2@1+ (1.000000,0.000000) [0.000000|3.000000] "" Motor_BEV
 SG_ PSD_Sys_Quali_Vorfahrtsregelung m0 : 60|3@1+ (1.000000,0.000000) [0.000000|7.000000] "Unit_None" Vector__XXX
 SG_ PSD_Ges_Verkehrszeichen_Quelle m2 : 61|2@1+ (1.000000,0.000000) [0.000000|3.000000] "" Motor_BEV
 SG_ PSD_Steigung_2_Attribute_kompl m4 : 61|1@1+ (1.000000,0.000000) [0.000000|1.000000] "" Motor_BEV
 SG_ PSD_Ges_Attribute_Komplett m2 : 63|1@1+ (1.000000,0.000000) [0.000000|1.000000] "" Motor_BEV

BO_ 591 RDR1_Objekte_02: 64 ICAS1_Gateway
 SG_ RDR1_relevanter_Fehler  : 12|1@1+ (1.000000,0.000000) [0.000000|1.000000] "" Motor_BEV
 SG_ RDR1_Blindheit_erkannt  : 13|1@1+ (1.000000,0.000000) [0.000000|1.000000] "" Motor_BEV
 SG_ RDR1_relev_Nichtverfuegbarkeit  : 14|1@1+ (1.000000,0.000000) [0.000000|1.000000] "" Motor_BEV
 SG_ RDR1_Obj_01_Nummer  : 16|6@1+ (1.000000,0.000000) [0.000000|63.000000] "" Vector__XXX
 SG_ RDR1_Obj_02_Nummer  : 22|6@1+ (1.000000,0.000000) [0.000000|63.000000] "" Vector__XXX
 SG_ RDR1_Obj_03_Nummer  : 28|6@1+ (1.000000,0.000000) [0.000000|63.000000] "" Vector__XXX
 SG_ RDR1_Obj_04_Nummer  : 34|6@1+ (1.000000,0.000000) [0.000000|63.000000] "" Vector__XXX
 SG_ RDR1_Obj_05_Nummer  : 40|6@1+ (1.000000,0.000000) [0.000000|63.000000] "" Vector__XXX
 SG_ RDR1_Obj_06_Nummer  : 46|6@1+ (1.000000,0.000000) [0.000000|63.000000] "" Vector__XXX
 SG_ RDR1_Verkehrssinn  : 52|2@1+ (1.000000,0.000000) [0.000000|3.000000] "" Vector__XXX
 SG_ RDR1_Objekte_02_Datenalter  : 54|10@1+ (0.000977,0.000000) [0.000000|0.998047] "Unit_Secon" Vector__XXX
 SG_ RDR1_Obj_01_dx_v  : 64|12@1+ (0.062500,0.000000) [0.000000|255.937500] "Unit_Meter" Motor_BEV
 SG_ RDR1_Obj_01_dy_v  : 76|10@1+ (0.062500,-32.000000) [-32.000000|31.937500] "Unit_Meter" Motor_BEV
 SG_ RDR1_Obj_01_vx_v  : 86|10@1+ (0.250000,-128.000000) [-128.000000|127.750000] "Unit_MeterPerSecon" Motor_BEV
 SG_ RDR1_Obj_02_dx_v  : 96|12@1+ (0.062500,0.000000) [0.000000|255.937500] "Unit_Meter" Vector__XXX
 SG_ RDR1_Obj_02_dy_v  : 108|10@1+ (0.062500,-32.000000) [-32.000000|31.937500] "Unit_Meter" Vector__XXX
 SG_ RDR1_Obj_02_vx_v  : 118|10@1+ (0.250000,-128.000000) [-128.000000|127.750000] "Unit_MeterPerSecon" Vector__XXX
 SG_ RDR1_Obj_03_dx_v  : 128|12@1+ (0.062500,0.000000) [0.000000|255.937500] "Unit_Meter" Vector__XXX
 SG_ RDR1_Obj_03_dy_v  : 140|10@1+ (0.062500,-32.000000) [-32.000000|31.937500] "Unit_Meter" Vector__XXX
 SG_ RDR1_Obj_03_vx_v  : 150|10@1+ (0.250000,-128.000000) [-128.000000|127.750000] "Unit_MeterPerSecon" Vector__XXX
 SG_ RDR1_Obj_04_dx_v  : 160|12@1+ (0.062500,0.000000) [0.000000|255.937500] "Unit_Meter" Motor_BEV
 SG_ RDR1_Obj_04_dy_v  : 172|10@1+ (0.062500,-32.000000) [-32.000000|31.937500] "Unit_Meter" Vector__XXX
 SG_ RDR1_Obj_04_vx_v  : 182|10@1+ (0.250000,-128.000000) [-128.000000|127.750000] "Unit_MeterPerSecon" Motor_BEV
 SG_ RDR1_Obj_05_dx_v  : 192|12@1+ (0.062500,0.000000) [0.000000|255.937500] "Unit_Meter" Vector__XXX
 SG_ RDR1_Obj_05_dy_v  : 204|10@1+ (0.062500,-32.000000) [-32.000000|31.937500] "Unit_Meter" Vector__XXX
 SG_ RDR1_Obj_05_vx_v  : 214|10@1+ (0.250000,-128.000000) [-128.000000|127.750000] "Unit_MeterPerSecon" Vector__XXX
 SG_ RDR1_Obj_06_dx_v  : 224|12@1+ (0.062500,0.000000) [0.000000|255.937500] "Unit_Meter" Vector__XXX
 SG_ RDR1_Obj_06_dy_v  : 236|10@1+ (0.062500,-32.000000) [-32.000000|31.937500] "Unit_Meter" Vector__XXX
 SG_ RDR1_Obj_06_vx_v  : 246|10@1+ (0.250000,-128.000000) [-128.000000|127.750000] "Unit_MeterPerSecon" Vector__XXX
 SG_ RDR1_Obj_01_ax_v  : 256|8@1+ (0.125000,-16.000000) [-16.000000|15.750000] "Unit_MeterPerSeconSquar" Motor_BEV
 SG_ RDR1_Obj_01_ax_StdA  : 264|6@1+ (0.125000,0.000000) [0.000000|7.750000] "Unit_MeterPerSeconSquar" Motor_BEV
 SG_ RDR1_Obj_01_vx_StdA  : 270|7@1+ (0.031250,0.000000) [0.000000|3.937500] "Unit_MeterPerSecon" Motor_BEV
 SG_ RDR1_Obj_01_dx_StdA  : 277|7@1+ (0.050000,0.000000) [0.000000|6.300000] "Unit_Meter" Motor_BEV
 SG_ RDR1_Obj_01_dy_StdA  : 284|7@1+ (0.062500,0.000000) [0.000000|7.875000] "Unit_Meter" Motor_BEV

BO_ 2033 Request_Airbag_Deployment: 8 ICAS1_Gateway
 SG_ Request_Airbag_Deployment  : 0|64@1+ (1.000000,0.000000) [0.000000|18446744073709551616.000000] "" Airbag

BO_ 2041 Response_Airbag_Deployment: 8 Airbag
 SG_ Response_Airbag_Deployment  : 0|64@1+ (1.000000,0.000000) [0.000000|18446744073709551616.000000] "" ICAS1_Gateway

BU_:  Airbag BAP_Tester ICAS1_Gateway ICAS1_KommunikationsServer LE1 LE2 Motor_BEV Schaltbetaetigung

BO_ 2463978709 OCC_02: 32 ICAS1_Gateway
 SG_ OCC_CP_Tastgrad_A  : 12|10@1+ (0.100000,0.000000) [0.000000|100.000000] "Unit_PerCent" Vector__XXX
 SG_ OCC_CP_Tastgrad_B  : 22|10@1+ (0.100000,0.000000) [0.000000|100.000000] "Unit_PerCent" Vector__XXX
 SG_ OCC_CP_Frequenz_A  : 32|8@1+ (1.000000,880.000000) [880.000000|1132.000000] "Unit_Hertz" Vector__XXX
 SG_ OCC_CP_Frequenz_B  : 40|8@1+ (1.000000,880.000000) [880.000000|1132.000000] "Unit_Hertz" Vector__XXX
 SG_ OCC_CP_Spannung_A  : 48|9@1+ (0.100000,-25.000000) [-25.000000|25.900000] "Unit_Volt" Vector__XXX
 SG_ OCC_CP_Spannung_B  : 57|9@1+ (0.100000,-25.000000) [-25.000000|25.900000] "Unit_Volt" Vector__XXX
 SG_ OCC_CP_Fehlerstatus_A  : 66|3@1+ (1.000000,0.000000) [0.000000|7.000000] "" Vector__XXX
 SG_ OCC_CP_Fehlerstatus_B  : 69|3@1+ (1.000000,0.000000) [0.000000|7.000000] "" Vector__XXX
 SG_ OCC_Temp_Ladedose_A_AC  : 72|8@1+ (1.000000,-40.000000) [-40.000000|213.000000] "Unit_DegreCelsi" Vector__XXX
 SG_ OCC_Temp_Ladedose_A_DC_minus  : 80|8@1+ (1.000000,-40.000000) [-40.000000|213.000000] "Unit_DegreCelsi" Vector__XXX
 SG_ OCC_Temp_Ladedose_A_DC_plus  : 88|8@1+ (1.000000,-40.000000) [-40.000000|213.000000] "Unit_DegreCelsi" Vector__XXX
 SG_ OCC_U_istAC_Netz_L1  : 96|9@1+ (1.000000,0.000000) [0.000000|509.000000] "Unit_Volt" Vector__XXX
 SG_ OCC_U_istAC_Netz_L2  : 105|9@1+ (1.000000,0.000000) [0.000000|509.000000] "Unit_Volt" Vector__XXX
 SG_ OCC_U_istAC_Netz_L3  : 114|9@1+ (1.000000,0.000000) [0.000000|508.000000] "Unit_Volt" Vector__XXX
 SG_ OCC_StatusVerEntriegelungAktor_A  : 123|3@1+ (1.000000,0.000000) [0.000000|7.000000] "" Vector__XXX
 SG_ OCC_SteckerEntriegelung_Verbot_A  : 126|2@1+ (1.000000,0.000000) [0.000000|3.000000] "" Vector__XXX
 SG_ OCC_StatusVerEntriegelungAktor_B  : 128|3@1+ (1.000000,0.000000) [0.000000|7.000000] "" Vector__XXX
 SG_ OCC_SteckerEntriegelung_Verbot_B  : 131|2@1+ (1.000000,0.000000) [0.000000|3.000000] "" Vector__XXX
 SG_ OCC_Verriegelung_Status_A  : 133|3@1+ (1.000000,0.000000) [0.000000|7.000000] "" Vector__XXX
 SG_ OCC_Verriegelung_Status_B  : 136|3@1+ (1.000000,0.000000) [0.000000|7.000000] "" Vector__XXX
 SG_ OCC_RtmWarnLadeKommunikation  : 139|3@1+ (1.000000,0.000000) [0.000000|7.000000] "" Vector__XXX
 SG_ OCC_Ist_Wirkungsgrad  : 145|7@1+ (1.000000,0.000000) [0.000000|100.000000] "Unit_PerCent" Vector__XXX
 SG_ OCC_PP_Max_Strom_A  : 152|4@1+ (1.000000,0.000000) [0.000000|15.000000] "" Vector__XXX
 SG_ OCC_PP_Max_Strom_B  : 156|4@1+ (1.000000,0.000000) [0.000000|15.000000] "" Vector__XXX
 SG_ OCC_DC_MaxStrom  : 160|11@1+ (0.100000,0.000000) [0.000000|204.500000] "Unit_Amper" Vector__XXX
 SG_ OCC_Derating_Temperatur  : 171|1@1+ (1.000000,0.000000) [0.000000|1.000000] "" Vector__XXX
 SG_ OCC_Fehlerzustand  : 172|1@1+ (1.000000,0.000000) [0.000000|1.000000] "" Vector__XXX
 SG_ OCC_Ladest_Entriegelungs_Verbot  : 173|3@1+ (1.000000,0.000000) [0.000000|7.000000] "" Vector__XXX
 SG_ OCC_Netzfrequenz_EVU  : 176|9@1+ (0.100000,40.000000) [40.000000|80.000000] "Unit_Hertz" Vector__XXX
 SG_ OCC_Warnzustand  : 185|1@1+ (1.000000,0.000000) [0.000000|1.000000] "" Vector__XXX
 SG_ OCC_Kuehltemperatur  : 192|8@1+ (1.000000,-40.000000) [-40.000000|213.000000] "Unit_DegreCelsi" Motor_BEV
 SG_ OCC_PP_Fehlerstatus_A  : 200|4@1+ (1.000000,0.000000) [0.000000|15.000000] "" Vector__XXX
 SG_ OCC_PP_Fehlerstatus_B  : 204|4@1+ (1.000000,0.000000) [0.000000|15.000000] "" Vector__XXX

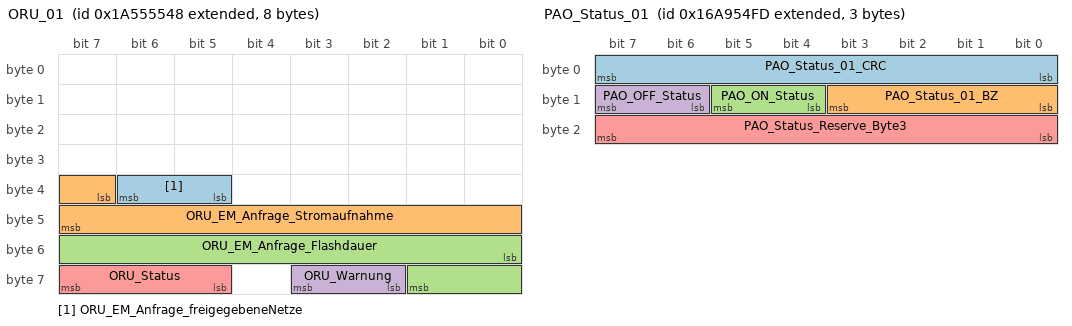
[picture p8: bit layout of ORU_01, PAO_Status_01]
BO_ 2589283656 ORU_01: 8 ICAS1_Gateway
 SG_ ORU_EM_Anfrage_freigegebeneNetze  : 37|2@1+ (1.000000,0.000000) [0.000000|3.000000] "" Vector__XXX
 SG_ ORU_EM_Anfrage_Stromaufnahme  : 39|9@1+ (0.100000,0.000000) [0.000000|51.100000] "Unit_Amper" Vector__XXX
 SG_ ORU_EM_Anfrage_Flashdauer  : 48|10@1+ (10.000000,0.000000) [0.000000|10230.000000] "Unit_Secon" Vector__XXX
 SG_ ORU_Warnung  : 58|2@1+ (1.000000,0.000000) [0.000000|3.000000] "" Vector__XXX
 SG_ ORU_Status  : 61|3@1+ (1.000000,0.000000) [0.000000|7.000000] "" Airbag LE1 LE2 Motor_BEV

BO_ 2527679741 PAO_Status_01: 3 ICAS1_Gateway
 SG_ PAO_Status_01_CRC  : 0|8@1+ (1.000000,0.000000) [0.000000|255.000000] "" Airbag
 SG_ PAO_Status_01_BZ  : 8|4@1+ (1.000000,0.000000) [0.000000|15.000000] "" Airbag
 SG_ PAO_ON_Status  : 12|2@1+ (1.000000,0.000000) [0.000000|3.000000] "" Airbag
 SG_ PAO_OFF_Status  : 14|2@1+ (1.000000,0.000000) [0.000000|3.000000] "" Airbag
 SG_ PAO_Status_Reserve_Byte3  : 16|8@1+ (1.000000,0.000000) [0.000000|255.000000] "" Vector__XXX

BO_ 518 Parken_01: 24 ICAS1_Gateway
 SG_ Parken_BKD_Anf  : 12|4@1+ (0.100000,0.000000) [0.000000|1.300000] "Unit_Secon" Vector__XXX
 SG_ Parken_Verz_Anf  : 16|7@1+ (0.100000,-12.600000) [-12.600000|-0.100000] "Unit_MeterPerSeconSquar" Vector__XXX
 SG_ Parken_Prefill_Anf  : 23|1@1+ (1.000000,0.000000) [0.000000|1.000000] "" Vector__XXX
 SG_ Parken_Warnruck_Anf  : 24|2@1+ (1.000000,0.000000) [0.000000|3.000000] "" Vector__XXX
 SG_ Parken_Verz_Anf_ASIL  : 26|2@1+ (1.000000,0.000000) [0.000000|3.000000] "" Vector__XXX
 SG_ Parken_Warnruckeln_Anf  : 28|2@1+ (1.000000,0.000000) [0.000000|3.000000] "" Vector__XXX
 SG_ Parken_beibehalten  : 30|2@1+ (1.000000,0.000000) [0.000000|3.000000] "" Vector__XXX
 SG_ Parken_Anforderung_HMS  : 32|3@1+ (1.000000,0.000000) [0.000000|7.000000] "" Vector__XXX
 SG_ Parken_Notstopp_Anf  : 40|2@1+ (1.000000,0.000000) [0.000000|3.000000] "" Vector__XXX
 SG_ Parken_Anhalteweg_Anf  : 42|10@1+ (0.010000,0.000000) [0.000000|10.210000] "Unit_Meter" Vector__XXX
 SG_ Parken_aktives_System  : 52|4@1+ (1.000000,0.000000) [0.000000|15.000000] "" Motor_BEV
 SG_ Parken_max_Beschleunigung  : 56|7@1+ (0.100000,-6.000000) [-5.900000|6.100000] "Unit_MeterPerSeconSquar" Motor_BEV
 SG_ Parken_Blinker_li_Anf  : 63|1@1+ (1.000000,0.000000) [0.000000|1.000000] "" Vector__XXX
 SG_ Parken_QFK_KruemmSoll  : 64|15@1+ (0.000007,0.000000) [0.000000|0.219539] "Unit_MeterInver" Vector__XXX
 SG_ Parken_QFK_KruemmSoll_VZ  : 79|1@1+ (1.000000,0.000000) [0.000000|1.000000] "" Vector__XXX
 SG_ Parken_QFK_Spuerb  : 80|8@1+ (0.400000,0.000000) [0.000000|100.000000] "Unit_PerCent" Vector__XXX
 SG_ Parken_QFK_AnfStat  : 88|4@1+ (1.000000,0.000000) [0.000000|15.000000] "" Vector__XXX
 SG_ Parken_QFK_Signal1  : 92|10@1+ (1.000000,0.000000) [0.000000|1023.000000] "" Vector__XXX
 SG_ Parken_QFK_Art1  : 102|3@1+ (1.000000,0.000000) [0.000000|7.000000] "" Vector__XXX
 SG_ Parken_QFK_Art2  : 105|3@1+ (1.000000,0.000000) [0.000000|7.000000] "" Vector__XXX
 SG_ Parken_QFK_Signal2  : 108|10@1+ (1.000000,0.000000) [0.000000|1023.000000] "" Vector__XXX
 SG_ Parken_Sollbeschleunigung  : 118|9@1+ (0.010000,-4.110000) [-4.100000|1.000000] "Unit_MeterPerSeconSquar" Motor_BEV
 SG_ Parken_Blinker_re_Anf  : 127|1@1+ (1.000000,0.000000) [0.000000|1.000000] "" Vector__XXX
 SG_ Parken_Status_IPA_TSK  : 128|4@1+ (1.000000,0.000000) [0.000000|15.000000] "" Motor_BEV
 SG_ Parken_erhoehtes_Moment  : 132|4@1+ (1.000000,0.000000) [0.000000|15.000000] "" Motor_BEV
 SG_ Parken_max_Geschwindigkeit  : 136|8@1+ (0.100000,0.000000) [0.100000|25.000000] "Unit_KiloMeterPerHour" Motor_BEV
 SG_ Parken_Soll_Anhalteweg_Anf  : 144|10@1+ (0.010000,0.000000) [0.000000|10.210000] "Unit_Meter" Vector__XXX
 SG_ Parken_Fahrstufenwunsch  : 154|3@1+ (1.000000,0.000000) [0.000000|7.000000] "" Motor_BEV
 SG_ IPA_TPA_Remote  : 157|2@1+ (1.000000,0.000000) [0.000000|3.000000] "" Vector__XXX
 SG_ IPA_TPA_Remote_Anf  : 159|1@1+ (1.000000,0.000000) [0.000000|1.000000] "" Vector__XXX
 SG_ IPA_TPA_Fehler  : 160|4@1+ (1.000000,0.000000) [0.000000|15.000000] "" Vector__XXX
 SG_ IPA_TPA_Abbruch  : 164|4@1+ (1.000000,0.000000) [0.000000|15.000000] "" Vector__XXX
 SG_ IPA_TPA_Status  : 168|4@1+ (1.000000,0.000000) [0.000000|15.000000] "" Vector__XXX

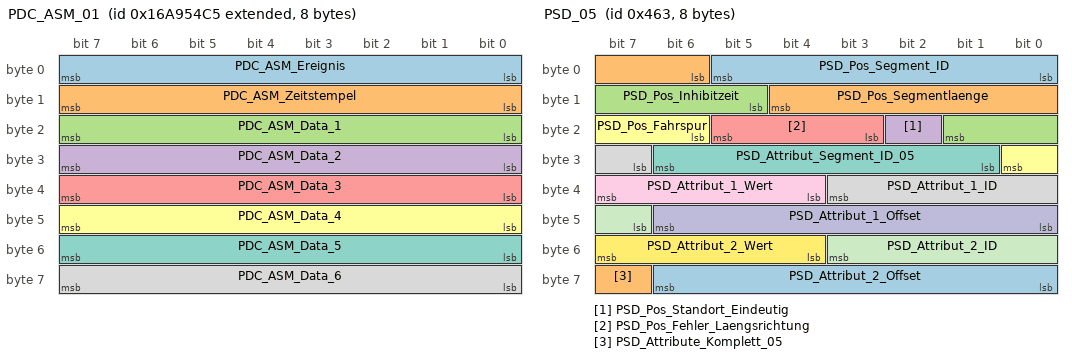
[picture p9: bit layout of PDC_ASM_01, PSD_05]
BO_ 2527679685 PDC_ASM_01: 8 ICAS1_Gateway
 SG_ PDC_ASM_Ereignis  : 0|8@1+ (1.000000,0.000000) [1.000000|254.000000] "" Airbag
 SG_ PDC_ASM_Zeitstempel  : 8|8@1+ (0.080000,0.000000) [0.000000|20.320000] "Unit_Secon" Airbag
 SG_ PDC_ASM_Data_1  : 16|8@1+ (1.000000,0.000000) [0.000000|255.000000] "" Airbag
 SG_ PDC_ASM_Data_2  : 24|8@1+ (1.000000,0.000000) [0.000000|255.000000] "" Airbag
 SG_ PDC_ASM_Data_3  : 32|8@1+ (1.000000,0.000000) [0.000000|255.000000] "" Airbag
 SG_ PDC_ASM_Data_4  : 40|8@1+ (1.000000,0.000000) [0.000000|255.000000] "" Airbag
 SG_ PDC_ASM_Data_5  : 48|8@1+ (1.000000,0.000000) [0.000000|255.000000] "" Airbag
 SG_ PDC_ASM_Data_6  : 56|8@1+ (1.000000,0.000000) [0.000000|255.000000] "" Airbag

BO_ 319 PreCrash_02: 8 Airbag
 SG_ PreCrash_Charisma_FahrPr  : 12|4@1+ (1.000000,0.000000) [0.000000|15.000000] "" ICAS1_Gateway
 SG_ PreCrash_Charisma_Status  : 16|2@1+ (1.000000,0.000000) [0.000000|3.000000] "" ICAS1_Gateway
 SG_ PreCrash_Schiebedach_schliessen  : 18|1@1+ (1.000000,0.000000) [0.000000|1.000000] "" ICAS1_Gateway
 SG_ PreCrash_Fenster_schliessen  : 19|1@1+ (1.000000,0.000000) [0.000000|1.000000] "" ICAS1_Gateway
 SG_ PreCrash_Blinken  : 20|3@1+ (1.000000,0.000000) [0.000000|7.000000] "" ICAS1_Gateway
 SG_ SC_PreSense_FCWP  : 23|1@1+ (1.000000,0.000000) [0.000000|1.000000] "" ICAS1_Gateway
 SG_ PreCrash_Tueren_Verriegeln  : 24|1@1+ (1.000000,0.000000) [0.000000|1.000000] "" ICAS1_Gateway
 SG_ PreCrash_FS_Laengsverstellung  : 25|1@1+ (1.000000,0.000000) [0.000000|1.000000] "" ICAS1_Gateway
 SG_ PreCrash_Anforderung_AFR  : 26|3@1+ (1.000000,0.000000) [0.000000|7.000000] "" ICAS1_Gateway
 SG_ SC_PreCrash_LED  : 29|2@1+ (1.000000,0.000000) [0.000000|3.000000] "" ICAS1_Gateway
 SG_ PreCrash_FS_Pneumatik_ansteuern  : 31|1@1+ (1.000000,0.000000) [0.000000|1.000000] "" ICAS1_Gateway
 SG_ PreCrash_BFS_Pneumatik_ansteuern  : 32|1@1+ (1.000000,0.000000) [0.000000|1.000000] "" ICAS1_Gateway
 SG_ PreCrash_Fo_Pneumatik_ansteuern  : 33|1@1+ (1.000000,0.000000) [0.000000|1.000000] "" ICAS1_Gateway
 SG_ PreCrash_FS_Sitzlehne_verfahren  : 34|3@1+ (1.000000,0.000000) [0.000000|7.000000] "" ICAS1_Gateway
 SG_ PreCrash_BFS_Sitzlehne_verfahren  : 37|3@1+ (1.000000,0.000000) [0.000000|7.000000] "" ICAS1_Gateway
 SG_ PreCrash_Fo_Sitzlehne_verfahren  : 40|3@1+ (1.000000,0.000000) [0.000000|7.000000] "" ICAS1_Gateway
 SG_ PreCrash_FS_KSV_verfahren  : 43|4@1+ (1.000000,0.000000) [0.000000|15.000000] "" ICAS1_Gateway
 SG_ PreCrash_BFS_KSV_verfahren  : 47|4@1+ (1.000000,0.000000) [0.000000|15.000000] "" ICAS1_Gateway
 SG_ PreCrash_Fo_KSV_verfahren  : 51|4@1+ (1.000000,0.000000) [0.000000|15.000000] "" ICAS1_Gateway
 SG_ PreCrash_BFS_Laengsverstellung  : 55|1@1+ (1.000000,0.000000) [0.000000|1.000000] "" ICAS1_Gateway
 SG_ SC_PreCrash_Warnung  : 56|4@1+ (1.000000,0.000000) [0.000000|15.000000] "" ICAS1_Gateway ICAS1_KommunikationsServer
 SG_ SC_PreCrash_Texte  : 60|4@1+ (1.000000,0.000000) [0.000000|15.000000] "" ICAS1_Gateway ICAS1_KommunikationsServer

BO_ 1122 PSD_04: 8 ICAS1_Gateway
 SG_ PSD_Segment_ID  : 0|6@1+ (1.000000,0.000000) [2.000000|63.000000] "" Motor_BEV
 SG_ PSD_Vorgaenger_Segment_ID  : 6|6@1+ (1.000000,0.000000) [2.000000|63.000000] "" Motor_BEV
 SG_ PSD_Segmentlaenge  : 12|7@1+ (2.000000,0.000000) [0.000000|254.000000] "Unit_Meter" Motor_BEV
 SG_ PSD_Strassenkategorie  : 19|3@1+ (1.000000,0.000000) [0.000000|7.000000] "" Motor_BEV
 SG_ PSD_Endkruemmung  : 22|8@1+ (1.000000,0.000000) [0.000000|254.000000] "Unit_None" Motor_BEV
 SG_ PSD_Endkruemmung_Vorz  : 30|1@1+ (1.000000,0.000000) [0.000000|1.000000] "" Motor_BEV
 SG_ PSD_Idenditaets_ID  : 31|6@1+ (1.000000,0.000000) [2.000000|63.000000] "" Vector__XXX
 SG_ PSD_ADAS_Qualitaet  : 37|1@1+ (1.000000,0.000000) [0.000000|1.000000] "" Motor_BEV
 SG_ PSD_wahrscheinlichster_Pfad  : 38|1@1+ (1.000000,0.000000) [0.000000|1.000000] "" Motor_BEV
 SG_ PSD_Geradester_Pfad  : 39|1@1+ (1.000000,0.000000) [0.000000|1.000000] "" Motor_BEV
 SG_ PSD_Fahrspuren_Anzahl  : 40|3@1+ (1.000000,0.000000) [0.000000|7.000000] "" Motor_BEV
 SG_ PSD_Bebauung  : 43|1@1+ (1.000000,0.000000) [0.000000|1.000000] "" Motor_BEV
 SG_ PSD_Segment_Komplett  : 44|1@1+ (1.000000,0.000000) [0.000000|1.000000] "" Motor_BEV
 SG_ PSD_Rampe  : 45|2@1+ (1.000000,0.000000) [0.000000|3.000000] "" Motor_BEV
 SG_ PSD_Anfangskruemmung  : 47|8@1+ (1.000000,0.000000) [0.000000|254.000000] "" Motor_BEV
 SG_ PSD_Anfangskruemmung_Vorz  : 55|1@1+ (1.000000,0.000000) [0.000000|1.000000] "" Motor_BEV
 SG_ PSD_Abzweigerichtung  : 56|1@1+ (1.000000,0.000000) [0.000000|1.000000] "" Motor_BEV
 SG_ PSD_Abzweigewinkel  : 57|7@1+ (1.417323,0.000000) [0.000000|180.000021] "" Motor_BEV

BO_ 1123 PSD_05: 8 ICAS1_Gateway
 SG_ PSD_Pos_Segment_ID  : 0|6@1+ (1.000000,0.000000) [2.000000|63.000000] "" Motor_BEV
 SG_ PSD_Pos_Segmentlaenge  : 6|7@1+ (2.000000,0.000000) [0.000000|254.000000] "Unit_Meter" Motor_BEV
 SG_ PSD_Pos_Inhibitzeit  : 13|5@1+ (10.000000,0.000000) [0.000000|310.000000] "Unit_MilliSecon" Motor_BEV
 SG_ PSD_Pos_Standort_Eindeutig  : 18|1@1+ (1.000000,0.000000) [0.000000|1.000000] "" Motor_BEV
 SG_ PSD_Pos_Fehler_Laengsrichtung  : 19|3@1+ (1.000000,0.000000) [0.000000|7.000000] "" Motor_BEV
 SG_ PSD_Pos_Fahrspur  : 22|3@1+ (1.000000,0.000000) [0.000000|7.000000] "" Motor_BEV
 SG_ PSD_Attribut_Segment_ID_05  : 25|6@1+ (1.000000,0.000000) [2.000000|63.000000] "" Motor_BEV
 SG_ PSD_Attribut_1_ID  : 31|5@1+ (1.000000,0.000000) [1.000000|31.000000] "" Motor_BEV
 SG_ PSD_Attribut_1_Wert  : 36|4@1+ (1.000000,0.000000) [0.000000|15.000000] "" Motor_BEV
 SG_ PSD_Attribut_1_Offset  : 40|7@1+ (2.000000,0.000000) [0.000000|254.000000] "Unit_Meter" Motor_BEV
 SG_ PSD_Attribut_2_ID  : 47|5@1+ (1.000000,0.000000) [1.000000|31.000000] "" Motor_BEV
 SG_ PSD_Attribut_2_Wert  : 52|4@1+ (1.000000,0.000000) [0.000000|15.000000] "" Motor_BEV
 SG_ PSD_Attribut_2_Offset  : 56|7@1+ (2.000000,0.000000) [0.000000|254.000000] "Unit_Meter" Motor_BEV
 SG_ PSD_Attribute_Komplett_05  : 63|1@1+ (1.000000,0.000000) [0.000000|1.000000] "" Motor_BEV

BO_ 1124 PSD_06: 8 ICAS1_Gateway
 SG_ PSD_06_Mux M : 0|3@1+ (1.000000,0.000000) [0.000000|7.000000] "" Motor_BEV
 SG_ PSD_Sys_Segment_ID m0 : 3|6@1+ (1.000000,0.000000) [2.000000|63.000000] "" Motor_BEV
 SG_ PSD_Attribut_Segment_ID m1 : 3|6@1+ (1.000000,0.000000) [2.000000|63.000000] "" Motor_BEV
 SG_ PSD_Ges_Segment_ID m2 : 3|6@1+ (1.000000,0.000000) [2.000000|63.000000] "" Motor_BEV
 SG_ PSD_Baum_Laenge_VZ m3 : 3|1@1+ (1.000000,0.000000) [0.000000|1.000000] "" Motor_BEV
 SG_ PSD_Steigung_1_Segment_ID m4 : 3|6@1+ (1.000000,0.000000) [2.000000|63.000000] "" Motor_BEV
 SG_ PSD_Baum_Laenge m3 : 4|25@1+ (0.000010,0.000000) [0.000000|180.000000] "Unit_DegreOfArc" Motor_BEV
 SG_ PSD_Sys_Laendercode m0 : 9|8@1+ (1.000000,0.000000) [0.000000|255.000000] "" Motor_BEV
 SG_ PSD_Attribut_3_ID m1 : 9|5@1+ (1.000000,0.000000) [1.000000|31.000000] "" Motor_BEV
 SG_ PSD_Ges_Offset m2 : 9|7@1+ (2.000000,0.000000) [0.000000|254.000000] "Unit_Meter" Motor_BEV
 SG_ PSD_Steigung_1_A_Steigung m4 : 9|7@1+ (0.120000,0.000000) [0.000000|15.000000] "Unit_PerCent" Motor_BEV
 SG_ PSD_Attribut_3_Offset m1 : 14|7@1+ (2.000000,0.000000) [0.000000|254.000000] "Unit_Meter" Motor_BEV
 SG_ PSD_Ges_Geschwindigkeit m2 : 16|5@1+ (1.000000,0.000000) [0.000000|31.000000] "" Motor_BEV
 SG_ PSD_Steigung_1_A_Vorz m4 : 16|1@1+ (1.000000,0.000000) [0.000000|1.000000] "" Motor_BEV
 SG_ PSD_Sys_Geschwindigkeit_Einheit m0 : 17|1@1+ (1.000000,0.000000) [0.000000|1.000000] "" Motor_BEV
 SG_ PSD_Steigung_1_A_Offset m4 : 17|7@1+ (2.000000,0.000000) [0.000000|254.000000] "Unit_Meter" Motor_BEV
 SG_ PSD_Sys_Verkehrsrichtung m0 : 18|1@1+ (1.000000,0.000000) [0.000000|1.000000] "" Motor_BEV
 SG_ PSD_Sys_Geometrieguete m0 : 19|2@1+ (1.000000,0.000000) [0.000000|3.000000] "" Motor_BEV
 SG_ PSD_Sys_Mapmatchingguete m0 : 21|2@1+ (1.000000,0.000000) [0.000000|3.000000] "" Motor_BEV
 SG_ PSD_Attribut_3_Wert m1 : 21|4@1+ (1.000000,0.000000) [0.000000|15.000000] "" Motor_BEV
 SG_ PSD_Ges_Typ m2 : 21|2@1+ (1.000000,0.000000) [0.000000|3.000000] "" Motor_BEV
 SG_ PSD_Sys_Alter_Karte m0 : 23|3@1+ (1.000000,0.000000) [0.000000|7.000000] "" Motor_BEV
 SG_ PSD_Ges_Spur_Geschw_Begrenzung m2 : 23|6@1+ (1.000000,0.000000) [0.000000|63.000000] "" Motor_BEV
 SG_ PSD_Steigung_1_B_Steigung m4 : 24|7@1+ (0.120000,0.000000) [0.000000|15.000000] "Unit_PerCent" Motor_BEV
 SG_ PSD_Attribut_4_ID m1 : 25|5@1+ (1.000000,0.000000) [1.000000|31.000000] "" Motor_BEV
 SG_ PSD_Sys_Zielfuehrung m0 : 26|1@1+ (1.000000,0.000000) [0.000000|1.000000] "" Motor_BEV
 SG_ PSD_Sys_US_State m0 : 27|6@1+ (1.000000,0.000000) [0.000000|63.000000] "" Motor_BEV
 SG_ PSD_Ges_Geschwindigkeit_Gespann m2 : 29|2@1+ (1.000000,0.000000) [0.000000|3.000000] "" Motor_BEV
 SG_ PSD_Baum_Breite_VZ m3 : 29|1@1+ (1.000000,0.000000) [0.000000|1.000000] "" Motor_BEV
 SG_ PSD_Attribut_4_Wert m1 : 30|4@1+ (1.000000,0.000000) [0.000000|15.000000] "" Motor_BEV
 SG_ PSD_Baum_Breite m3 : 30|24@1+ (0.000010,0.000000) [0.000000|90.000000] "Unit_DegreOfArc" Motor_BEV
 SG_ PSD_Ges_Geschwindigkeit_Witter m2 : 31|2@1+ (1.000000,0.000000) [0.000000|3.000000] "" Motor_BEV
 SG_ PSD_Steigung_1_B_Vorz m4 : 31|1@1+ (1.000000,0.000000) [0.000000|1.000000] "" Motor_BEV
 SG_ PSD_Steigung_1_B_Offset m4 : 32|7@1+ (2.000000,0.000000) [0.000000|254.000000] "Unit_Meter" Motor_BEV
 SG_ PSD_Sys_Quali_Geometrien m0 : 33|3@1+ (1.000000,0.000000) [0.000000|7.000000] "Unit_None" Vector__XXX
 SG_ PSD_Ges_Geschwindigkeit_Tag_Anf m2 : 33|3@1+ (1.000000,0.000000) [0.000000|7.000000] "" Motor_BEV
 SG_ PSD_Attribut_4_Offset m1 : 34|7@1+ (2.000000,0.000000) [0.000000|254.000000] "Unit_Meter" Motor_BEV
 SG_ PSD_Sys_Quali_Ortsinfo m0 : 36|2@1+ (1.000000,0.000000) [0.000000|3.000000] "Unit_None" Vector__XXX
 SG_ PSD_Ges_Geschwindigkeit_Tag_Ende m2 : 36|3@1+ (1.000000,0.000000) [0.000000|7.000000] "" Motor_BEV
 SG_ PSD_Sys_Quali_verfuegbar m0 : 38|1@1+ (1.000000,0.000000) [0.000000|1.000000] "" Vector__XXX
 SG_ PSD_Sys_Zielfuehrung_geaendert m0 : 39|1@1+ (1.000000,0.000000) [0.000000|1.000000] "" Motor_BEV
 SG_ PSD_Ges_Geschwindigkeit_Std_Anf m2 : 39|5@1+ (1.000000,0.000000) [0.000000|24.000000] "Unit_Hours" Motor_BEV
 SG_ PSD_Steigung_1_Attribute_kompl m4 : 39|1@1+ (1.000000,0.000000) [0.000000|1.000000] "" Motor_BEV
 SG_ PSD_Sys_Geometrieguete_erweitert m0 : 40|8@1+ (1.000000,0.000000) [0.000000|255.000000] "" Vector__XXX
 SG_ PSD_Steigung_2_Segment_ID m4 : 40|6@1+ (1.000000,0.000000) [2.000000|63.000000] "" Motor_BEV
 SG_ PSD_Attribut_5_ID m1 : 41|5@1+ (1.000000,0.000000) [1.000000|31.000000] "" Motor_BEV
 SG_ PSD_Ges_Geschwindigkeit_Std_Ende m2 : 44|5@1+ (1.000000,0.000000) [0.000000|24.000000] "Unit_Hours" Motor_BEV
 SG_ PSD_Attribut_5_Offset m1 : 46|7@1+ (2.000000,0.000000) [0.000000|254.000000] "Unit_Meter" Motor_BEV
 SG_ PSD_Steigung_2_Steigung m4 : 46|7@1+ (0.120000,0.000000) [0.000000|15.000000] "Unit_PerCent" Motor_BEV
 SG_ PSD_Sys_Quali_sonstige_Attribute m0 : 48|3@1+ (1.000000,0.000000) [0.000000|7.000000] "Unit_None" Vector__XXX
 SG_ PSD_Ges_Ueberholverbot m2 : 49|2@1+ (1.000000,0.000000) [0.000000|3.000000] "" Vector__XXX
 SG_ PSD_Sys_Quali_Steigungen m0 : 51|3@1+ (1.000000,0.000000) [0.000000|7.000000] "" Vector__XXX
 SG_ PSD_Ges_Wechselverkehrszeichen m2 : 51|3@1+ (1.000000,0.000000) [0.000000|7.000000] "" Vector__XXX
 SG_ PSD_Attribut_5_Wert m1 : 53|4@1+ (1.000000,0.000000) [0.000000|15.000000] "" Motor_BEV
 SG_ PSD_Steigung_2_Vorz m4 : 53|1@1+ (1.000000,0.000000) [0.000000|1.000000] "" Motor_BEV
 SG_ PSD_Sys_Quali_Strassenkennz m0 : 54|3@1+ (1.000000,0.000000) [0.000000|7.000000] "Unit_None" Vector__XXX
 SG_ PSD_Wechselverkehrszeichen_Typ m2 : 54|2@1+ (1.000000,0.000000) [0.000000|3.000000] "" Vector__XXX
 SG_ PSD_Baum_Ausrichtung m3 : 54|10@1+ (0.351562,0.000000) [0.000000|359.648438] "Unit_DegreOfArc" Vector__XXX
 SG_ PSD_Steigung_2_Offset m4 : 54|7@1+ (2.000000,0.000000) [0.000000|254.000000] "Unit_Meter" Motor_BEV
 SG_ PSD_Ges_Gesetzlich_Kategorie m2 : 56|3@1+ (1.000000,0.000000) [0.000000|7.000000] "" Motor_BEV
 SG_ PSD_Sys_Quali_Tempolimits m0 : 57|3@1+ (1.000000,0.000000) [0.000000|7.000000] "Unit_None" Vector__XXX
 SG_ PSD_Attribute_Komplett_06 m1 : 57|1@1+ (1.000000,0.000000) [0.000000|1.000000] "" Motor_BEV
 SG_ PSD_Ges_Gesetzlich_Zusatz m2 : 59|2@1+ (1.000000,0.000000) [0.000000|3.000000] "" Motor_BEV
 SG_ PSD_Sys_Quali_Vorfahrtsregelung m0 : 60|3@1+ (1.000000,0.000000) [0.000000|7.000000] "Unit_None" Vector__XXX
 SG_ PSD_Ges_Verkehrszeichen_Quelle m2 : 61|2@1+ (1.000000,0.000000) [0.000000|3.000000] "" Motor_BEV
 SG_ PSD_Steigung_2_Attribute_kompl m4 : 61|1@1+ (1.000000,0.000000) [0.000000|1.000000] "" Motor_BEV
 SG_ PSD_Ges_Attribute_Komplett m2 : 63|1@1+ (1.000000,0.000000) [0.000000|1.000000] "" Motor_BEV

BO_ 591 RDR1_Objekte_02: 64 ICAS1_Gateway
 SG_ RDR1_relevanter_Fehler  : 12|1@1+ (1.000000,0.000000) [0.000000|1.000000] "" Motor_BEV
 SG_ RDR1_Blindheit_erkannt  : 13|1@1+ (1.000000,0.000000) [0.000000|1.000000] "" Motor_BEV
 SG_ RDR1_relev_Nichtverfuegbarkeit  : 14|1@1+ (1.000000,0.000000) [0.000000|1.000000] "" Motor_BEV
 SG_ RDR1_Obj_01_Nummer  : 16|6@1+ (1.000000,0.000000) [0.000000|63.000000] "" Vector__XXX
 SG_ RDR1_Obj_02_Nummer  : 22|6@1+ (1.000000,0.000000) [0.000000|63.000000] "" Vector__XXX
 SG_ RDR1_Obj_03_Nummer  : 28|6@1+ (1.000000,0.000000) [0.000000|63.000000] "" Vector__XXX
 SG_ RDR1_Obj_04_Nummer  : 34|6@1+ (1.000000,0.000000) [0.000000|63.000000] "" Vector__XXX
 SG_ RDR1_Obj_05_Nummer  : 40|6@1+ (1.000000,0.000000) [0.000000|63.000000] "" Vector__XXX
 SG_ RDR1_Obj_06_Nummer  : 46|6@1+ (1.000000,0.000000) [0.000000|63.000000] "" Vector__XXX
 SG_ RDR1_Verkehrssinn  : 52|2@1+ (1.000000,0.000000) [0.000000|3.000000] "" Vector__XXX
 SG_ RDR1_Objekte_02_Datenalter  : 54|10@1+ (0.000977,0.000000) [0.000000|0.998047] "Unit_Secon" Vector__XXX
 SG_ RDR1_Obj_01_dx_v  : 64|12@1+ (0.062500,0.000000) [0.000000|255.937500] "Unit_Meter" Motor_BEV
 SG_ RDR1_Obj_01_dy_v  : 76|10@1+ (0.062500,-32.000000) [-32.000000|31.937500] "Unit_Meter" Motor_BEV
 SG_ RDR1_Obj_01_vx_v  : 86|10@1+ (0.250000,-128.000000) [-128.000000|127.750000] "Unit_MeterPerSecon" Motor_BEV
 SG_ RDR1_Obj_02_dx_v  : 96|12@1+ (0.062500,0.000000) [0.000000|255.937500] "Unit_Meter" Vector__XXX
 SG_ RDR1_Obj_02_dy_v  : 108|10@1+ (0.062500,-32.000000) [-32.000000|31.937500] "Unit_Meter" Vector__XXX
 SG_ RDR1_Obj_02_vx_v  : 118|10@1+ (0.250000,-128.000000) [-128.000000|127.750000] "Unit_MeterPerSecon" Vector__XXX
 SG_ RDR1_Obj_03_dx_v  : 128|12@1+ (0.062500,0.000000) [0.000000|255.937500] "Unit_Meter" Vector__XXX
 SG_ RDR1_Obj_03_dy_v  : 140|10@1+ (0.062500,-32.000000) [-32.000000|31.937500] "Unit_Meter" Vector__XXX
 SG_ RDR1_Obj_03_vx_v  : 150|10@1+ (0.250000,-128.000000) [-128.000000|127.750000] "Unit_MeterPerSecon" Vector__XXX
 SG_ RDR1_Obj_04_dx_v  : 160|12@1+ (0.062500,0.000000) [0.000000|255.937500] "Unit_Meter" Motor_BEV
 SG_ RDR1_Obj_04_dy_v  : 172|10@1+ (0.062500,-32.000000) [-32.000000|31.937500] "Unit_Meter" Vector__XXX
 SG_ RDR1_Obj_04_vx_v  : 182|10@1+ (0.250000,-128.000000) [-128.000000|127.750000] "Unit_MeterPerSecon" Motor_BEV
 SG_ RDR1_Obj_05_dx_v  : 192|12@1+ (0.062500,0.000000) [0.000000|255.937500] "Unit_Meter" Vector__XXX
 SG_ RDR1_Obj_05_dy_v  : 204|10@1+ (0.062500,-32.000000) [-32.000000|31.937500] "Unit_Meter" Vector__XXX
 SG_ RDR1_Obj_05_vx_v  : 214|10@1+ (0.250000,-128.000000) [-128.000000|127.750000] "Unit_MeterPerSecon" Vector__XXX
 SG_ RDR1_Obj_06_dx_v  : 224|12@1+ (0.062500,0.000000) [0.000000|255.937500] "Unit_Meter" Vector__XXX
 SG_ RDR1_Obj_06_dy_v  : 236|10@1+ (0.062500,-32.000000) [-32.000000|31.937500] "Unit_Meter" Vector__XXX
 SG_ RDR1_Obj_06_vx_v  : 246|10@1+ (0.250000,-128.000000) [-128.000000|127.750000] "Unit_MeterPerSecon" Vector__XXX
 SG_ RDR1_Obj_01_ax_v  : 256|8@1+ (0.125000,-16.000000) [-16.000000|15.750000] "Unit_MeterPerSeconSquar" Motor_BEV
 SG_ RDR1_Obj_01_ax_StdA  : 264|6@1+ (0.125000,0.000000) [0.000000|7.750000] "Unit_MeterPerSeconSquar" Motor_BEV
 SG_ RDR1_Obj_01_vx_StdA  : 270|7@1+ (0.031250,0.000000) [0.000000|3.937500] "Unit_MeterPerSecon" Motor_BEV
 SG_ RDR1_Obj_01_dx_StdA  : 277|7@1+ (0.050000,0.000000) [0.000000|6.300000] "Unit_Meter" Motor_BEV
 SG_ RDR1_Obj_01_dy_StdA  : 284|7@1+ (0.062500,0.000000) [0.000000|7.875000] "Unit_Meter" Motor_BEV

BO_ 2033 Request_Airbag_Deployment: 8 ICAS1_Gateway
 SG_ Request_Airbag_Deployment  : 0|64@1+ (1.000000,0.000000) [0.000000|18446744073709551616.000000] "" Airbag

BO_ 2041 Response_Airbag_Deployment: 8 Airbag
 SG_ Response_Airbag_Deployment  : 0|64@1+ (1.000000,0.000000) [0.000000|18446744073709551616.000000] "" ICAS1_Gateway

BU_:  Airbag BAP_Tester ICAS1_Gateway ICAS1_KommunikationsServer LE1 LE2 Motor_BEV Schaltbetaetigung

BO_ 2463978709 OCC_02: 32 ICAS1_Gateway
 SG_ OCC_CP_Tastgrad_A  : 12|10@1+ (0.100000,0.000000) [0.000000|100.000000] "Unit_PerCent" Vector__XXX
 SG_ OCC_CP_Tastgrad_B  : 22|10@1+ (0.100000,0.000000) [0.000000|100.000000] "Unit_PerCent" Vector__XXX
 SG_ OCC_CP_Frequenz_A  : 32|8@1+ (1.000000,880.000000) [880.000000|1132.000000] "Unit_Hertz" Vector__XXX
 SG_ OCC_CP_Frequenz_B  : 40|8@1+ (1.000000,880.000000) [880.000000|1132.000000] "Unit_Hertz" Vector__XXX
 SG_ OCC_CP_Spannung_A  : 48|9@1+ (0.100000,-25.000000) [-25.000000|25.900000] "Unit_Volt" Vector__XXX
 SG_ OCC_CP_Spannung_B  : 57|9@1+ (0.100000,-25.000000) [-25.000000|25.900000] "Unit_Volt" Vector__XXX
 SG_ OCC_CP_Fehlerstatus_A  : 66|3@1+ (1.000000,0.000000) [0.000000|7.000000] "" Vector__XXX
 SG_ OCC_CP_Fehlerstatus_B  : 69|3@1+ (1.000000,0.000000) [0.000000|7.000000] "" Vector__XXX
 SG_ OCC_Temp_Ladedose_A_AC  : 72|8@1+ (1.000000,-40.000000) [-40.000000|213.000000] "Unit_DegreCelsi" Vector__XXX
 SG_ OCC_Temp_Ladedose_A_DC_minus  : 80|8@1+ (1.000000,-40.000000) [-40.000000|213.000000] "Unit_DegreCelsi" Vector__XXX
 SG_ OCC_Temp_Ladedose_A_DC_plus  : 88|8@1+ (1.000000,-40.000000) [-40.000000|213.000000] "Unit_DegreCelsi" Vector__XXX
 SG_ OCC_U_istAC_Netz_L1  : 96|9@1+ (1.000000,0.000000) [0.000000|509.000000] "Unit_Volt" Vector__XXX
 SG_ OCC_U_istAC_Netz_L2  : 105|9@1+ (1.000000,0.000000) [0.000000|509.000000] "Unit_Volt" Vector__XXX
 SG_ OCC_U_istAC_Netz_L3  : 114|9@1+ (1.000000,0.000000) [0.000000|508.000000] "Unit_Volt" Vector__XXX
 SG_ OCC_StatusVerEntriegelungAktor_A  : 123|3@1+ (1.000000,0.000000) [0.000000|7.000000] "" Vector__XXX
 SG_ OCC_SteckerEntriegelung_Verbot_A  : 126|2@1+ (1.000000,0.000000) [0.000000|3.000000] "" Vector__XXX
 SG_ OCC_StatusVerEntriegelungAktor_B  : 128|3@1+ (1.000000,0.000000) [0.000000|7.000000] "" Vector__XXX
 SG_ OCC_SteckerEntriegelung_Verbot_B  : 131|2@1+ (1.000000,0.000000) [0.000000|3.000000] "" Vector__XXX
 SG_ OCC_Verriegelung_Status_A  : 133|3@1+ (1.000000,0.000000) [0.000000|7.000000] "" Vector__XXX
 SG_ OCC_Verriegelung_Status_B  : 136|3@1+ (1.000000,0.000000) [0.000000|7.000000] "" Vector__XXX
 SG_ OCC_RtmWarnLadeKommunikation  : 139|3@1+ (1.000000,0.000000) [0.000000|7.000000] "" Vector__XXX
 SG_ OCC_Ist_Wirkungsgrad  : 145|7@1+ (1.000000,0.000000) [0.000000|100.000000] "Unit_PerCent" Vector__XXX
 SG_ OCC_PP_Max_Strom_A  : 152|4@1+ (1.000000,0.000000) [0.000000|15.000000] "" Vector__XXX
 SG_ OCC_PP_Max_Strom_B  : 156|4@1+ (1.000000,0.000000) [0.000000|15.000000] "" Vector__XXX
 SG_ OCC_DC_MaxStrom  : 160|11@1+ (0.100000,0.000000) [0.000000|204.500000] "Unit_Amper" Vector__XXX
 SG_ OCC_Derating_Temperatur  : 171|1@1+ (1.000000,0.000000) [0.000000|1.000000] "" Vector__XXX
 SG_ OCC_Fehlerzustand  : 172|1@1+ (1.000000,0.000000) [0.000000|1.000000] "" Vector__XXX
 SG_ OCC_Ladest_Entriegelungs_Verbot  : 173|3@1+ (1.000000,0.000000) [0.000000|7.000000] "" Vector__XXX
 SG_ OCC_Netzfrequenz_EVU  : 176|9@1+ (0.100000,40.000000) [40.000000|80.000000] "Unit_Hertz" Vector__XXX
 SG_ OCC_Warnzustand  : 185|1@1+ (1.000000,0.000000) [0.000000|1.000000] "" Vector__XXX
 SG_ OCC_Kuehltemperatur  : 192|8@1+ (1.000000,-40.000000) [-40.000000|213.000000] "Unit_DegreCelsi" Motor_BEV
 SG_ OCC_PP_Fehlerstatus_A  : 200|4@1+ (1.000000,0.000000) [0.000000|15.000000] "" Vector__XXX
 SG_ OCC_PP_Fehlerstatus_B  : 204|4@1+ (1.000000,0.000000) [0.000000|15.000000] "" Vector__XXX

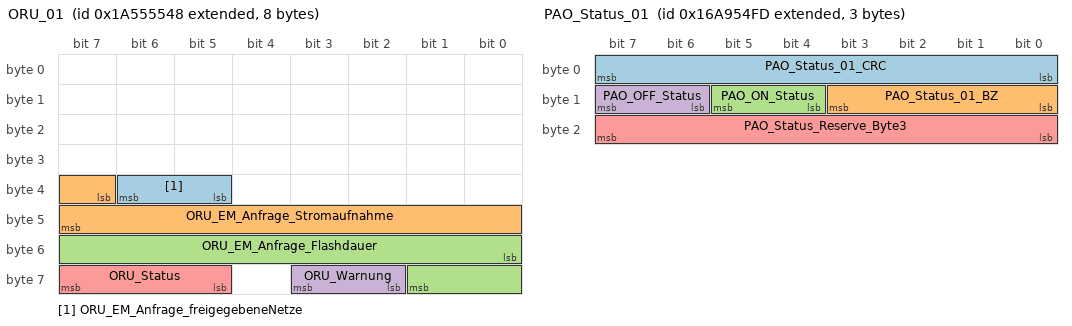
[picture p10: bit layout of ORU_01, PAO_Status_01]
BO_ 2589283656 ORU_01: 8 ICAS1_Gateway
 SG_ ORU_EM_Anfrage_freigegebeneNetze  : 37|2@1+ (1.000000,0.000000) [0.000000|3.000000] "" Vector__XXX
 SG_ ORU_EM_Anfrage_Stromaufnahme  : 39|9@1+ (0.100000,0.000000) [0.000000|51.100000] "Unit_Amper" Vector__XXX
 SG_ ORU_EM_Anfrage_Flashdauer  : 48|10@1+ (10.000000,0.000000) [0.000000|10230.000000] "Unit_Secon" Vector__XXX
 SG_ ORU_Warnung  : 58|2@1+ (1.000000,0.000000) [0.000000|3.000000] "" Vector__XXX
 SG_ ORU_Status  : 61|3@1+ (1.000000,0.000000) [0.000000|7.000000] "" Airbag LE1 LE2 Motor_BEV

BO_ 2527679741 PAO_Status_01: 3 ICAS1_Gateway
 SG_ PAO_Status_01_CRC  : 0|8@1+ (1.000000,0.000000) [0.000000|255.000000] "" Airbag
 SG_ PAO_Status_01_BZ  : 8|4@1+ (1.000000,0.000000) [0.000000|15.000000] "" Airbag
 SG_ PAO_ON_Status  : 12|2@1+ (1.000000,0.000000) [0.000000|3.000000] "" Airbag
 SG_ PAO_OFF_Status  : 14|2@1+ (1.000000,0.000000) [0.000000|3.000000] "" Airbag
 SG_ PAO_Status_Reserve_Byte3  : 16|8@1+ (1.000000,0.000000) [0.000000|255.000000] "" Vector__XXX

BO_ 518 Parken_01: 24 ICAS1_Gateway
 SG_ Parken_BKD_Anf  : 12|4@1+ (0.100000,0.000000) [0.000000|1.300000] "Unit_Secon" Vector__XXX
 SG_ Parken_Verz_Anf  : 16|7@1+ (0.100000,-12.600000) [-12.600000|-0.100000] "Unit_MeterPerSeconSquar" Vector__XXX
 SG_ Parken_Prefill_Anf  : 23|1@1+ (1.000000,0.000000) [0.000000|1.000000] "" Vector__XXX
 SG_ Parken_Warnruck_Anf  : 24|2@1+ (1.000000,0.000000) [0.000000|3.000000] "" Vector__XXX
 SG_ Parken_Verz_Anf_ASIL  : 26|2@1+ (1.000000,0.000000) [0.000000|3.000000] "" Vector__XXX
 SG_ Parken_Warnruckeln_Anf  : 28|2@1+ (1.000000,0.000000) [0.000000|3.000000] "" Vector__XXX
 SG_ Parken_beibehalten  : 30|2@1+ (1.000000,0.000000) [0.000000|3.000000] "" Vector__XXX
 SG_ Parken_Anforderung_HMS  : 32|3@1+ (1.000000,0.000000) [0.000000|7.000000] "" Vector__XXX
 SG_ Parken_Notstopp_Anf  : 40|2@1+ (1.000000,0.000000) [0.000000|3.000000] "" Vector__XXX
 SG_ Parken_Anhalteweg_Anf  : 42|10@1+ (0.010000,0.000000) [0.000000|10.210000] "Unit_Meter" Vector__XXX
 SG_ Parken_aktives_System  : 52|4@1+ (1.000000,0.000000) [0.000000|15.000000] "" Motor_BEV
 SG_ Parken_max_Beschleunigung  : 56|7@1+ (0.100000,-6.000000) [-5.900000|6.100000] "Unit_MeterPerSeconSquar" Motor_BEV
 SG_ Parken_Blinker_li_Anf  : 63|1@1+ (1.000000,0.000000) [0.000000|1.000000] "" Vector__XXX
 SG_ Parken_QFK_KruemmSoll  : 64|15@1+ (0.000007,0.000000) [0.000000|0.219539] "Unit_MeterInver" Vector__XXX
 SG_ Parken_QFK_KruemmSoll_VZ  : 79|1@1+ (1.000000,0.000000) [0.000000|1.000000] "" Vector__XXX
 SG_ Parken_QFK_Spuerb  : 80|8@1+ (0.400000,0.000000) [0.000000|100.000000] "Unit_PerCent" Vector__XXX
 SG_ Parken_QFK_AnfStat  : 88|4@1+ (1.000000,0.000000) [0.000000|15.000000] "" Vector__XXX
 SG_ Parken_QFK_Signal1  : 92|10@1+ (1.000000,0.000000) [0.000000|1023.000000] "" Vector__XXX
 SG_ Parken_QFK_Art1  : 102|3@1+ (1.000000,0.000000) [0.000000|7.000000] "" Vector__XXX
 SG_ Parken_QFK_Art2  : 105|3@1+ (1.000000,0.000000) [0.000000|7.000000] "" Vector__XXX
 SG_ Parken_QFK_Signal2  : 108|10@1+ (1.000000,0.000000) [0.000000|1023.000000] "" Vector__XXX
 SG_ Parken_Sollbeschleunigung  : 118|9@1+ (0.010000,-4.110000) [-4.100000|1.000000] "Unit_MeterPerSeconSquar" Motor_BEV
 SG_ Parken_Blinker_re_Anf  : 127|1@1+ (1.000000,0.000000) [0.000000|1.000000] "" Vector__XXX
 SG_ Parken_Status_IPA_TSK  : 128|4@1+ (1.000000,0.000000) [0.000000|15.000000] "" Motor_BEV
 SG_ Parken_erhoehtes_Moment  : 132|4@1+ (1.000000,0.000000) [0.000000|15.000000] "" Motor_BEV
 SG_ Parken_max_Geschwindigkeit  : 136|8@1+ (0.100000,0.000000) [0.100000|25.000000] "Unit_KiloMeterPerHour" Motor_BEV
 SG_ Parken_Soll_Anhalteweg_Anf  : 144|10@1+ (0.010000,0.000000) [0.000000|10.210000] "Unit_Meter" Vector__XXX
 SG_ Parken_Fahrstufenwunsch  : 154|3@1+ (1.000000,0.000000) [0.000000|7.000000] "" Motor_BEV
 SG_ IPA_TPA_Remote  : 157|2@1+ (1.000000,0.000000) [0.000000|3.000000] "" Vector__XXX
 SG_ IPA_TPA_Remote_Anf  : 159|1@1+ (1.000000,0.000000) [0.000000|1.000000] "" Vector__XXX
 SG_ IPA_TPA_Fehler  : 160|4@1+ (1.000000,0.000000) [0.000000|15.000000] "" Vector__XXX
 SG_ IPA_TPA_Abbruch  : 164|4@1+ (1.000000,0.000000) [0.000000|15.000000] "" Vector__XXX
 SG_ IPA_TPA_Status  : 168|4@1+ (1.000000,0.000000) [0.000000|15.000000] "" Vector__XXX

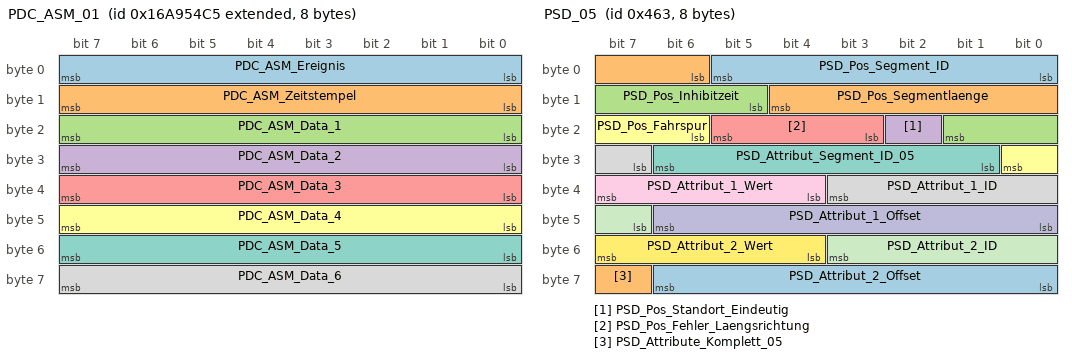
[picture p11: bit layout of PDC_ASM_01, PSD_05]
BO_ 2527679685 PDC_ASM_01: 8 ICAS1_Gateway
 SG_ PDC_ASM_Ereignis  : 0|8@1+ (1.000000,0.000000) [1.000000|254.000000] "" Airbag
 SG_ PDC_ASM_Zeitstempel  : 8|8@1+ (0.080000,0.000000) [0.000000|20.320000] "Unit_Secon" Airbag
 SG_ PDC_ASM_Data_1  : 16|8@1+ (1.000000,0.000000) [0.000000|255.000000] "" Airbag
 SG_ PDC_ASM_Data_2  : 24|8@1+ (1.000000,0.000000) [0.000000|255.000000] "" Airbag
 SG_ PDC_ASM_Data_3  : 32|8@1+ (1.000000,0.000000) [0.000000|255.000000] "" Airbag
 SG_ PDC_ASM_Data_4  : 40|8@1+ (1.000000,0.000000) [0.000000|255.000000] "" Airbag
 SG_ PDC_ASM_Data_5  : 48|8@1+ (1.000000,0.000000) [0.000000|255.000000] "" Airbag
 SG_ PDC_ASM_Data_6  : 56|8@1+ (1.000000,0.000000) [0.000000|255.000000] "" Airbag

BO_ 319 PreCrash_02: 8 Airbag
 SG_ PreCrash_Charisma_FahrPr  : 12|4@1+ (1.000000,0.000000) [0.000000|15.000000] "" ICAS1_Gateway
 SG_ PreCrash_Charisma_Status  : 16|2@1+ (1.000000,0.000000) [0.000000|3.000000] "" ICAS1_Gateway
 SG_ PreCrash_Schiebedach_schliessen  : 18|1@1+ (1.000000,0.000000) [0.000000|1.000000] "" ICAS1_Gateway
 SG_ PreCrash_Fenster_schliessen  : 19|1@1+ (1.000000,0.000000) [0.000000|1.000000] "" ICAS1_Gateway
 SG_ PreCrash_Blinken  : 20|3@1+ (1.000000,0.000000) [0.000000|7.000000] "" ICAS1_Gateway
 SG_ SC_PreSense_FCWP  : 23|1@1+ (1.000000,0.000000) [0.000000|1.000000] "" ICAS1_Gateway
 SG_ PreCrash_Tueren_Verriegeln  : 24|1@1+ (1.000000,0.000000) [0.000000|1.000000] "" ICAS1_Gateway
 SG_ PreCrash_FS_Laengsverstellung  : 25|1@1+ (1.000000,0.000000) [0.000000|1.000000] "" ICAS1_Gateway
 SG_ PreCrash_Anforderung_AFR  : 26|3@1+ (1.000000,0.000000) [0.000000|7.000000] "" ICAS1_Gateway
 SG_ SC_PreCrash_LED  : 29|2@1+ (1.000000,0.000000) [0.000000|3.000000] "" ICAS1_Gateway
 SG_ PreCrash_FS_Pneumatik_ansteuern  : 31|1@1+ (1.000000,0.000000) [0.000000|1.000000] "" ICAS1_Gateway
 SG_ PreCrash_BFS_Pneumatik_ansteuern  : 32|1@1+ (1.000000,0.000000) [0.000000|1.000000] "" ICAS1_Gateway
 SG_ PreCrash_Fo_Pneumatik_ansteuern  : 33|1@1+ (1.000000,0.000000) [0.000000|1.000000] "" ICAS1_Gateway
 SG_ PreCrash_FS_Sitzlehne_verfahren  : 34|3@1+ (1.000000,0.000000) [0.000000|7.000000] "" ICAS1_Gateway
 SG_ PreCrash_BFS_Sitzlehne_verfahren  : 37|3@1+ (1.000000,0.000000) [0.000000|7.000000] "" ICAS1_Gateway
 SG_ PreCrash_Fo_Sitzlehne_verfahren  : 40|3@1+ (1.000000,0.000000) [0.000000|7.000000] "" ICAS1_Gateway
 SG_ PreCrash_FS_KSV_verfahren  : 43|4@1+ (1.000000,0.000000) [0.000000|15.000000] "" ICAS1_Gateway
 SG_ PreCrash_BFS_KSV_verfahren  : 47|4@1+ (1.000000,0.000000) [0.000000|15.000000] "" ICAS1_Gateway
 SG_ PreCrash_Fo_KSV_verfahren  : 51|4@1+ (1.000000,0.000000) [0.000000|15.000000] "" ICAS1_Gateway
 SG_ PreCrash_BFS_Laengsverstellung  : 55|1@1+ (1.000000,0.000000) [0.000000|1.000000] "" ICAS1_Gateway
 SG_ SC_PreCrash_Warnung  : 56|4@1+ (1.000000,0.000000) [0.000000|15.000000] "" ICAS1_Gateway ICAS1_KommunikationsServer
 SG_ SC_PreCrash_Texte  : 60|4@1+ (1.000000,0.000000) [0.000000|15.000000] "" ICAS1_Gateway ICAS1_KommunikationsServer

BO_ 1122 PSD_04: 8 ICAS1_Gateway
 SG_ PSD_Segment_ID  : 0|6@1+ (1.000000,0.000000) [2.000000|63.000000] "" Motor_BEV
 SG_ PSD_Vorgaenger_Segment_ID  : 6|6@1+ (1.000000,0.000000) [2.000000|63.000000] "" Motor_BEV
 SG_ PSD_Segmentlaenge  : 12|7@1+ (2.000000,0.000000) [0.000000|254.000000] "Unit_Meter" Motor_BEV
 SG_ PSD_Strassenkategorie  : 19|3@1+ (1.000000,0.000000) [0.000000|7.000000] "" Motor_BEV
 SG_ PSD_Endkruemmung  : 22|8@1+ (1.000000,0.000000) [0.000000|254.000000] "Unit_None" Motor_BEV
 SG_ PSD_Endkruemmung_Vorz  : 30|1@1+ (1.000000,0.000000) [0.000000|1.000000] "" Motor_BEV
 SG_ PSD_Idenditaets_ID  : 31|6@1+ (1.000000,0.000000) [2.000000|63.000000] "" Vector__XXX
 SG_ PSD_ADAS_Qualitaet  : 37|1@1+ (1.000000,0.000000) [0.000000|1.000000] "" Motor_BEV
 SG_ PSD_wahrscheinlichster_Pfad  : 38|1@1+ (1.000000,0.000000) [0.000000|1.000000] "" Motor_BEV
 SG_ PSD_Geradester_Pfad  : 39|1@1+ (1.000000,0.000000) [0.000000|1.000000] "" Motor_BEV
 SG_ PSD_Fahrspuren_Anzahl  : 40|3@1+ (1.000000,0.000000) [0.000000|7.000000] "" Motor_BEV
 SG_ PSD_Bebauung  : 43|1@1+ (1.000000,0.000000) [0.000000|1.000000] "" Motor_BEV
 SG_ PSD_Segment_Komplett  : 44|1@1+ (1.000000,0.000000) [0.000000|1.000000] "" Motor_BEV
 SG_ PSD_Rampe  : 45|2@1+ (1.000000,0.000000) [0.000000|3.000000] "" Motor_BEV
 SG_ PSD_Anfangskruemmung  : 47|8@1+ (1.000000,0.000000) [0.000000|254.000000] "" Motor_BEV
 SG_ PSD_Anfangskruemmung_Vorz  : 55|1@1+ (1.000000,0.000000) [0.000000|1.000000] "" Motor_BEV
 SG_ PSD_Abzweigerichtung  : 56|1@1+ (1.000000,0.000000) [0.000000|1.000000] "" Motor_BEV
 SG_ PSD_Abzweigewinkel  : 57|7@1+ (1.417323,0.000000) [0.000000|180.000021] "" Motor_BEV

BO_ 1123 PSD_05: 8 ICAS1_Gateway
 SG_ PSD_Pos_Segment_ID  : 0|6@1+ (1.000000,0.000000) [2.000000|63.000000] "" Motor_BEV
 SG_ PSD_Pos_Segmentlaenge  : 6|7@1+ (2.000000,0.000000) [0.000000|254.000000] "Unit_Meter" Motor_BEV
 SG_ PSD_Pos_Inhibitzeit  : 13|5@1+ (10.000000,0.000000) [0.000000|310.000000] "Unit_MilliSecon" Motor_BEV
 SG_ PSD_Pos_Standort_Eindeutig  : 18|1@1+ (1.000000,0.000000) [0.000000|1.000000] "" Motor_BEV
 SG_ PSD_Pos_Fehler_Laengsrichtung  : 19|3@1+ (1.000000,0.000000) [0.000000|7.000000] "" Motor_BEV
 SG_ PSD_Pos_Fahrspur  : 22|3@1+ (1.000000,0.000000) [0.000000|7.000000] "" Motor_BEV
 SG_ PSD_Attribut_Segment_ID_05  : 25|6@1+ (1.000000,0.000000) [2.000000|63.000000] "" Motor_BEV
 SG_ PSD_Attribut_1_ID  : 31|5@1+ (1.000000,0.000000) [1.000000|31.000000] "" Motor_BEV
 SG_ PSD_Attribut_1_Wert  : 36|4@1+ (1.000000,0.000000) [0.000000|15.000000] "" Motor_BEV
 SG_ PSD_Attribut_1_Offset  : 40|7@1+ (2.000000,0.000000) [0.000000|254.000000] "Unit_Meter" Motor_BEV
 SG_ PSD_Attribut_2_ID  : 47|5@1+ (1.000000,0.000000) [1.000000|31.000000] "" Motor_BEV
 SG_ PSD_Attribut_2_Wert  : 52|4@1+ (1.000000,0.000000) [0.000000|15.000000] "" Motor_BEV
 SG_ PSD_Attribut_2_Offset  : 56|7@1+ (2.000000,0.000000) [0.000000|254.000000] "Unit_Meter" Motor_BEV
 SG_ PSD_Attribute_Komplett_05  : 63|1@1+ (1.000000,0.000000) [0.000000|1.000000] "" Motor_BEV

BO_ 1124 PSD_06: 8 ICAS1_Gateway
 SG_ PSD_06_Mux M : 0|3@1+ (1.000000,0.000000) [0.000000|7.000000] "" Motor_BEV
 SG_ PSD_Sys_Segment_ID m0 : 3|6@1+ (1.000000,0.000000) [2.000000|63.000000] "" Motor_BEV
 SG_ PSD_Attribut_Segment_ID m1 : 3|6@1+ (1.000000,0.000000) [2.000000|63.000000] "" Motor_BEV
 SG_ PSD_Ges_Segment_ID m2 : 3|6@1+ (1.000000,0.000000) [2.000000|63.000000] "" Motor_BEV
 SG_ PSD_Baum_Laenge_VZ m3 : 3|1@1+ (1.000000,0.000000) [0.000000|1.000000] "" Motor_BEV
 SG_ PSD_Steigung_1_Segment_ID m4 : 3|6@1+ (1.000000,0.000000) [2.000000|63.000000] "" Motor_BEV
 SG_ PSD_Baum_Laenge m3 : 4|25@1+ (0.000010,0.000000) [0.000000|180.000000] "Unit_DegreOfArc" Motor_BEV
 SG_ PSD_Sys_Laendercode m0 : 9|8@1+ (1.000000,0.000000) [0.000000|255.000000] "" Motor_BEV
 SG_ PSD_Attribut_3_ID m1 : 9|5@1+ (1.000000,0.000000) [1.000000|31.000000] "" Motor_BEV
 SG_ PSD_Ges_Offset m2 : 9|7@1+ (2.000000,0.000000) [0.000000|254.000000] "Unit_Meter" Motor_BEV
 SG_ PSD_Steigung_1_A_Steigung m4 : 9|7@1+ (0.120000,0.000000) [0.000000|15.000000] "Unit_PerCent" Motor_BEV
 SG_ PSD_Attribut_3_Offset m1 : 14|7@1+ (2.000000,0.000000) [0.000000|254.000000] "Unit_Meter" Motor_BEV
 SG_ PSD_Ges_Geschwindigkeit m2 : 16|5@1+ (1.000000,0.000000) [0.000000|31.000000] "" Motor_BEV
 SG_ PSD_Steigung_1_A_Vorz m4 : 16|1@1+ (1.000000,0.000000) [0.000000|1.000000] "" Motor_BEV
 SG_ PSD_Sys_Geschwindigkeit_Einheit m0 : 17|1@1+ (1.000000,0.000000) [0.000000|1.000000] "" Motor_BEV
 SG_ PSD_Steigung_1_A_Offset m4 : 17|7@1+ (2.000000,0.000000) [0.000000|254.000000] "Unit_Meter" Motor_BEV
 SG_ PSD_Sys_Verkehrsrichtung m0 : 18|1@1+ (1.000000,0.000000) [0.000000|1.000000] "" Motor_BEV
 SG_ PSD_Sys_Geometrieguete m0 : 19|2@1+ (1.000000,0.000000) [0.000000|3.000000] "" Motor_BEV
 SG_ PSD_Sys_Mapmatchingguete m0 : 21|2@1+ (1.000000,0.000000) [0.000000|3.000000] "" Motor_BEV
 SG_ PSD_Attribut_3_Wert m1 : 21|4@1+ (1.000000,0.000000) [0.000000|15.000000] "" Motor_BEV
 SG_ PSD_Ges_Typ m2 : 21|2@1+ (1.000000,0.000000) [0.000000|3.000000] "" Motor_BEV
 SG_ PSD_Sys_Alter_Karte m0 : 23|3@1+ (1.000000,0.000000) [0.000000|7.000000] "" Motor_BEV
 SG_ PSD_Ges_Spur_Geschw_Begrenzung m2 : 23|6@1+ (1.000000,0.000000) [0.000000|63.000000] "" Motor_BEV
 SG_ PSD_Steigung_1_B_Steigung m4 : 24|7@1+ (0.120000,0.000000) [0.000000|15.000000] "Unit_PerCent" Motor_BEV
 SG_ PSD_Attribut_4_ID m1 : 25|5@1+ (1.000000,0.000000) [1.000000|31.000000] "" Motor_BEV
 SG_ PSD_Sys_Zielfuehrung m0 : 26|1@1+ (1.000000,0.000000) [0.000000|1.000000] "" Motor_BEV
 SG_ PSD_Sys_US_State m0 : 27|6@1+ (1.000000,0.000000) [0.000000|63.000000] "" Motor_BEV
 SG_ PSD_Ges_Geschwindigkeit_Gespann m2 : 29|2@1+ (1.000000,0.000000) [0.000000|3.000000] "" Motor_BEV
 SG_ PSD_Baum_Breite_VZ m3 : 29|1@1+ (1.000000,0.000000) [0.000000|1.000000] "" Motor_BEV
 SG_ PSD_Attribut_4_Wert m1 : 30|4@1+ (1.000000,0.000000) [0.000000|15.000000] "" Motor_BEV
 SG_ PSD_Baum_Breite m3 : 30|24@1+ (0.000010,0.000000) [0.000000|90.000000] "Unit_DegreOfArc" Motor_BEV
 SG_ PSD_Ges_Geschwindigkeit_Witter m2 : 31|2@1+ (1.000000,0.000000) [0.000000|3.000000] "" Motor_BEV
 SG_ PSD_Steigung_1_B_Vorz m4 : 31|1@1+ (1.000000,0.000000) [0.000000|1.000000] "" Motor_BEV
 SG_ PSD_Steigung_1_B_Offset m4 : 32|7@1+ (2.000000,0.000000) [0.000000|254.000000] "Unit_Meter" Motor_BEV
 SG_ PSD_Sys_Quali_Geometrien m0 : 33|3@1+ (1.000000,0.000000) [0.000000|7.000000] "Unit_None" Vector__XXX
 SG_ PSD_Ges_Geschwindigkeit_Tag_Anf m2 : 33|3@1+ (1.000000,0.000000) [0.000000|7.000000] "" Motor_BEV
 SG_ PSD_Attribut_4_Offset m1 : 34|7@1+ (2.000000,0.000000) [0.000000|254.000000] "Unit_Meter" Motor_BEV
 SG_ PSD_Sys_Quali_Ortsinfo m0 : 36|2@1+ (1.000000,0.000000) [0.000000|3.000000] "Unit_None" Vector__XXX
 SG_ PSD_Ges_Geschwindigkeit_Tag_Ende m2 : 36|3@1+ (1.000000,0.000000) [0.000000|7.000000] "" Motor_BEV
 SG_ PSD_Sys_Quali_verfuegbar m0 : 38|1@1+ (1.000000,0.000000) [0.000000|1.000000] "" Vector__XXX
 SG_ PSD_Sys_Zielfuehrung_geaendert m0 : 39|1@1+ (1.000000,0.000000) [0.000000|1.000000] "" Motor_BEV
 SG_ PSD_Ges_Geschwindigkeit_Std_Anf m2 : 39|5@1+ (1.000000,0.000000) [0.000000|24.000000] "Unit_Hours" Motor_BEV
 SG_ PSD_Steigung_1_Attribute_kompl m4 : 39|1@1+ (1.000000,0.000000) [0.000000|1.000000] "" Motor_BEV
 SG_ PSD_Sys_Geometrieguete_erweitert m0 : 40|8@1+ (1.000000,0.000000) [0.000000|255.000000] "" Vector__XXX
 SG_ PSD_Steigung_2_Segment_ID m4 : 40|6@1+ (1.000000,0.000000) [2.000000|63.000000] "" Motor_BEV
 SG_ PSD_Attribut_5_ID m1 : 41|5@1+ (1.000000,0.000000) [1.000000|31.000000] "" Motor_BEV
 SG_ PSD_Ges_Geschwindigkeit_Std_Ende m2 : 44|5@1+ (1.000000,0.000000) [0.000000|24.000000] "Unit_Hours" Motor_BEV
 SG_ PSD_Attribut_5_Offset m1 : 46|7@1+ (2.000000,0.000000) [0.000000|254.000000] "Unit_Meter" Motor_BEV
 SG_ PSD_Steigung_2_Steigung m4 : 46|7@1+ (0.120000,0.000000) [0.000000|15.000000] "Unit_PerCent" Motor_BEV
 SG_ PSD_Sys_Quali_sonstige_Attribute m0 : 48|3@1+ (1.000000,0.000000) [0.000000|7.000000] "Unit_None" Vector__XXX
 SG_ PSD_Ges_Ueberholverbot m2 : 49|2@1+ (1.000000,0.000000) [0.000000|3.000000] "" Vector__XXX
 SG_ PSD_Sys_Quali_Steigungen m0 : 51|3@1+ (1.000000,0.000000) [0.000000|7.000000] "" Vector__XXX
 SG_ PSD_Ges_Wechselverkehrszeichen m2 : 51|3@1+ (1.000000,0.000000) [0.000000|7.000000] "" Vector__XXX
 SG_ PSD_Attribut_5_Wert m1 : 53|4@1+ (1.000000,0.000000) [0.000000|15.000000] "" Motor_BEV
 SG_ PSD_Steigung_2_Vorz m4 : 53|1@1+ (1.000000,0.000000) [0.000000|1.000000] "" Motor_BEV
 SG_ PSD_Sys_Quali_Strassenkennz m0 : 54|3@1+ (1.000000,0.000000) [0.000000|7.000000] "Unit_None" Vector__XXX
 SG_ PSD_Wechselverkehrszeichen_Typ m2 : 54|2@1+ (1.000000,0.000000) [0.000000|3.000000] "" Vector__XXX
 SG_ PSD_Baum_Ausrichtung m3 : 54|10@1+ (0.351562,0.000000) [0.000000|359.648438] "Unit_DegreOfArc" Vector__XXX
 SG_ PSD_Steigung_2_Offset m4 : 54|7@1+ (2.000000,0.000000) [0.000000|254.000000] "Unit_Meter" Motor_BEV
 SG_ PSD_Ges_Gesetzlich_Kategorie m2 : 56|3@1+ (1.000000,0.000000) [0.000000|7.000000] "" Motor_BEV
 SG_ PSD_Sys_Quali_Tempolimits m0 : 57|3@1+ (1.000000,0.000000) [0.000000|7.000000] "Unit_None" Vector__XXX
 SG_ PSD_Attribute_Komplett_06 m1 : 57|1@1+ (1.000000,0.000000) [0.000000|1.000000] "" Motor_BEV
 SG_ PSD_Ges_Gesetzlich_Zusatz m2 : 59|2@1+ (1.000000,0.000000) [0.000000|3.000000] "" Motor_BEV
 SG_ PSD_Sys_Quali_Vorfahrtsregelung m0 : 60|3@1+ (1.000000,0.000000) [0.000000|7.000000] "Unit_None" Vector__XXX
 SG_ PSD_Ges_Verkehrszeichen_Quelle m2 : 61|2@1+ (1.000000,0.000000) [0.000000|3.000000] "" Motor_BEV
 SG_ PSD_Steigung_2_Attribute_kompl m4 : 61|1@1+ (1.000000,0.000000) [0.000000|1.000000] "" Motor_BEV
 SG_ PSD_Ges_Attribute_Komplett m2 : 63|1@1+ (1.000000,0.000000) [0.000000|1.000000] "" Motor_BEV

BO_ 591 RDR1_Objekte_02: 64 ICAS1_Gateway
 SG_ RDR1_relevanter_Fehler  : 12|1@1+ (1.000000,0.000000) [0.000000|1.000000] "" Motor_BEV
 SG_ RDR1_Blindheit_erkannt  : 13|1@1+ (1.000000,0.000000) [0.000000|1.000000] "" Motor_BEV
 SG_ RDR1_relev_Nichtverfuegbarkeit  : 14|1@1+ (1.000000,0.000000) [0.000000|1.000000] "" Motor_BEV
 SG_ RDR1_Obj_01_Nummer  : 16|6@1+ (1.000000,0.000000) [0.000000|63.000000] "" Vector__XXX
 SG_ RDR1_Obj_02_Nummer  : 22|6@1+ (1.000000,0.000000) [0.000000|63.000000] "" Vector__XXX
 SG_ RDR1_Obj_03_Nummer  : 28|6@1+ (1.000000,0.000000) [0.000000|63.000000] "" Vector__XXX
 SG_ RDR1_Obj_04_Nummer  : 34|6@1+ (1.000000,0.000000) [0.000000|63.000000] "" Vector__XXX
 SG_ RDR1_Obj_05_Nummer  : 40|6@1+ (1.000000,0.000000) [0.000000|63.000000] "" Vector__XXX
 SG_ RDR1_Obj_06_Nummer  : 46|6@1+ (1.000000,0.000000) [0.000000|63.000000] "" Vector__XXX
 SG_ RDR1_Verkehrssinn  : 52|2@1+ (1.000000,0.000000) [0.000000|3.000000] "" Vector__XXX
 SG_ RDR1_Objekte_02_Datenalter  : 54|10@1+ (0.000977,0.000000) [0.000000|0.998047] "Unit_Secon" Vector__XXX
 SG_ RDR1_Obj_01_dx_v  : 64|12@1+ (0.062500,0.000000) [0.000000|255.937500] "Unit_Meter" Motor_BEV
 SG_ RDR1_Obj_01_dy_v  : 76|10@1+ (0.062500,-32.000000) [-32.000000|31.937500] "Unit_Meter" Motor_BEV
 SG_ RDR1_Obj_01_vx_v  : 86|10@1+ (0.250000,-128.000000) [-128.000000|127.750000] "Unit_MeterPerSecon" Motor_BEV
 SG_ RDR1_Obj_02_dx_v  : 96|12@1+ (0.062500,0.000000) [0.000000|255.937500] "Unit_Meter" Vector__XXX
 SG_ RDR1_Obj_02_dy_v  : 108|10@1+ (0.062500,-32.000000) [-32.000000|31.937500] "Unit_Meter" Vector__XXX
 SG_ RDR1_Obj_02_vx_v  : 118|10@1+ (0.250000,-128.000000) [-128.000000|127.750000] "Unit_MeterPerSecon" Vector__XXX
 SG_ RDR1_Obj_03_dx_v  : 128|12@1+ (0.062500,0.000000) [0.000000|255.937500] "Unit_Meter" Vector__XXX
 SG_ RDR1_Obj_03_dy_v  : 140|10@1+ (0.062500,-32.000000) [-32.000000|31.937500] "Unit_Meter" Vector__XXX
 SG_ RDR1_Obj_03_vx_v  : 150|10@1+ (0.250000,-128.000000) [-128.000000|127.750000] "Unit_MeterPerSecon" Vector__XXX
 SG_ RDR1_Obj_04_dx_v  : 160|12@1+ (0.062500,0.000000) [0.000000|255.937500] "Unit_Meter" Motor_BEV
 SG_ RDR1_Obj_04_dy_v  : 172|10@1+ (0.062500,-32.000000) [-32.000000|31.937500] "Unit_Meter" Vector__XXX
 SG_ RDR1_Obj_04_vx_v  : 182|10@1+ (0.250000,-128.000000) [-128.000000|127.750000] "Unit_MeterPerSecon" Motor_BEV
 SG_ RDR1_Obj_05_dx_v  : 192|12@1+ (0.062500,0.000000) [0.000000|255.937500] "Unit_Meter" Vector__XXX
 SG_ RDR1_Obj_05_dy_v  : 204|10@1+ (0.062500,-32.000000) [-32.000000|31.937500] "Unit_Meter" Vector__XXX
 SG_ RDR1_Obj_05_vx_v  : 214|10@1+ (0.250000,-128.000000) [-128.000000|127.750000] "Unit_MeterPerSecon" Vector__XXX
 SG_ RDR1_Obj_06_dx_v  : 224|12@1+ (0.062500,0.000000) [0.000000|255.937500] "Unit_Meter" Vector__XXX
 SG_ RDR1_Obj_06_dy_v  : 236|10@1+ (0.062500,-32.000000) [-32.000000|31.937500] "Unit_Meter" Vector__XXX
 SG_ RDR1_Obj_06_vx_v  : 246|10@1+ (0.250000,-128.000000) [-128.000000|127.750000] "Unit_MeterPerSecon" Vector__XXX
 SG_ RDR1_Obj_01_ax_v  : 256|8@1+ (0.125000,-16.000000) [-16.000000|15.750000] "Unit_MeterPerSeconSquar" Motor_BEV
 SG_ RDR1_Obj_01_ax_StdA  : 264|6@1+ (0.125000,0.000000) [0.000000|7.750000] "Unit_MeterPerSeconSquar" Motor_BEV
 SG_ RDR1_Obj_01_vx_StdA  : 270|7@1+ (0.031250,0.000000) [0.000000|3.937500] "Unit_MeterPerSecon" Motor_BEV
 SG_ RDR1_Obj_01_dx_StdA  : 277|7@1+ (0.050000,0.000000) [0.000000|6.300000] "Unit_Meter" Motor_BEV
 SG_ RDR1_Obj_01_dy_StdA  : 284|7@1+ (0.062500,0.000000) [0.000000|7.875000] "Unit_Meter" Motor_BEV

BO_ 2033 Request_Airbag_Deployment: 8 ICAS1_Gateway
 SG_ Request_Airbag_Deployment  : 0|64@1+ (1.000000,0.000000) [0.000000|18446744073709551616.000000] "" Airbag

BO_ 2041 Response_Airbag_Deployment: 8 Airbag
 SG_ Response_Airbag_Deployment  : 0|64@1+ (1.000000,0.000000) [0.000000|18446744073709551616.000000] "" ICAS1_Gateway

BU_:  Airbag BAP_Tester ICAS1_Gateway ICAS1_KommunikationsServer LE1 LE2 Motor_BEV Schaltbetaetigung

BO_ 2463978709 OCC_02: 32 ICAS1_Gateway
 SG_ OCC_CP_Tastgrad_A  : 12|10@1+ (0.100000,0.000000) [0.000000|100.000000] "Unit_PerCent" Vector__XXX
 SG_ OCC_CP_Tastgrad_B  : 22|10@1+ (0.100000,0.000000) [0.000000|100.000000] "Unit_PerCent" Vector__XXX
 SG_ OCC_CP_Frequenz_A  : 32|8@1+ (1.000000,880.000000) [880.000000|1132.000000] "Unit_Hertz" Vector__XXX
 SG_ OCC_CP_Frequenz_B  : 40|8@1+ (1.000000,880.000000) [880.000000|1132.000000] "Unit_Hertz" Vector__XXX
 SG_ OCC_CP_Spannung_A  : 48|9@1+ (0.100000,-25.000000) [-25.000000|25.900000] "Unit_Volt" Vector__XXX
 SG_ OCC_CP_Spannung_B  : 57|9@1+ (0.100000,-25.000000) [-25.000000|25.900000] "Unit_Volt" Vector__XXX
 SG_ OCC_CP_Fehlerstatus_A  : 66|3@1+ (1.000000,0.000000) [0.000000|7.000000] "" Vector__XXX
 SG_ OCC_CP_Fehlerstatus_B  : 69|3@1+ (1.000000,0.000000) [0.000000|7.000000] "" Vector__XXX
 SG_ OCC_Temp_Ladedose_A_AC  : 72|8@1+ (1.000000,-40.000000) [-40.000000|213.000000] "Unit_DegreCelsi" Vector__XXX
 SG_ OCC_Temp_Ladedose_A_DC_minus  : 80|8@1+ (1.000000,-40.000000) [-40.000000|213.000000] "Unit_DegreCelsi" Vector__XXX
 SG_ OCC_Temp_Ladedose_A_DC_plus  : 88|8@1+ (1.000000,-40.000000) [-40.000000|213.000000] "Unit_DegreCelsi" Vector__XXX
 SG_ OCC_U_istAC_Netz_L1  : 96|9@1+ (1.000000,0.000000) [0.000000|509.000000] "Unit_Volt" Vector__XXX
 SG_ OCC_U_istAC_Netz_L2  : 105|9@1+ (1.000000,0.000000) [0.000000|509.000000] "Unit_Volt" Vector__XXX
 SG_ OCC_U_istAC_Netz_L3  : 114|9@1+ (1.000000,0.000000) [0.000000|508.000000] "Unit_Volt" Vector__XXX
 SG_ OCC_StatusVerEntriegelungAktor_A  : 123|3@1+ (1.000000,0.000000) [0.000000|7.000000] "" Vector__XXX
 SG_ OCC_SteckerEntriegelung_Verbot_A  : 126|2@1+ (1.000000,0.000000) [0.000000|3.000000] "" Vector__XXX
 SG_ OCC_StatusVerEntriegelungAktor_B  : 128|3@1+ (1.000000,0.000000) [0.000000|7.000000] "" Vector__XXX
 SG_ OCC_SteckerEntriegelung_Verbot_B  : 131|2@1+ (1.000000,0.000000) [0.000000|3.000000] "" Vector__XXX
 SG_ OCC_Verriegelung_Status_A  : 133|3@1+ (1.000000,0.000000) [0.000000|7.000000] "" Vector__XXX
 SG_ OCC_Verriegelung_Status_B  : 136|3@1+ (1.000000,0.000000) [0.000000|7.000000] "" Vector__XXX
 SG_ OCC_RtmWarnLadeKommunikation  : 139|3@1+ (1.000000,0.000000) [0.000000|7.000000] "" Vector__XXX
 SG_ OCC_Ist_Wirkungsgrad  : 145|7@1+ (1.000000,0.000000) [0.000000|100.000000] "Unit_PerCent" Vector__XXX
 SG_ OCC_PP_Max_Strom_A  : 152|4@1+ (1.000000,0.000000) [0.000000|15.000000] "" Vector__XXX
 SG_ OCC_PP_Max_Strom_B  : 156|4@1+ (1.000000,0.000000) [0.000000|15.000000] "" Vector__XXX
 SG_ OCC_DC_MaxStrom  : 160|11@1+ (0.100000,0.000000) [0.000000|204.500000] "Unit_Amper" Vector__XXX
 SG_ OCC_Derating_Temperatur  : 171|1@1+ (1.000000,0.000000) [0.000000|1.000000] "" Vector__XXX
 SG_ OCC_Fehlerzustand  : 172|1@1+ (1.000000,0.000000) [0.000000|1.000000] "" Vector__XXX
 SG_ OCC_Ladest_Entriegelungs_Verbot  : 173|3@1+ (1.000000,0.000000) [0.000000|7.000000] "" Vector__XXX
 SG_ OCC_Netzfrequenz_EVU  : 176|9@1+ (0.100000,40.000000) [40.000000|80.000000] "Unit_Hertz" Vector__XXX
 SG_ OCC_Warnzustand  : 185|1@1+ (1.000000,0.000000) [0.000000|1.000000] "" Vector__XXX
 SG_ OCC_Kuehltemperatur  : 192|8@1+ (1.000000,-40.000000) [-40.000000|213.000000] "Unit_DegreCelsi" Motor_BEV
 SG_ OCC_PP_Fehlerstatus_A  : 200|4@1+ (1.000000,0.000000) [0.000000|15.000000] "" Vector__XXX
 SG_ OCC_PP_Fehlerstatus_B  : 204|4@1+ (1.000000,0.000000) [0.000000|15.000000] "" Vector__XXX

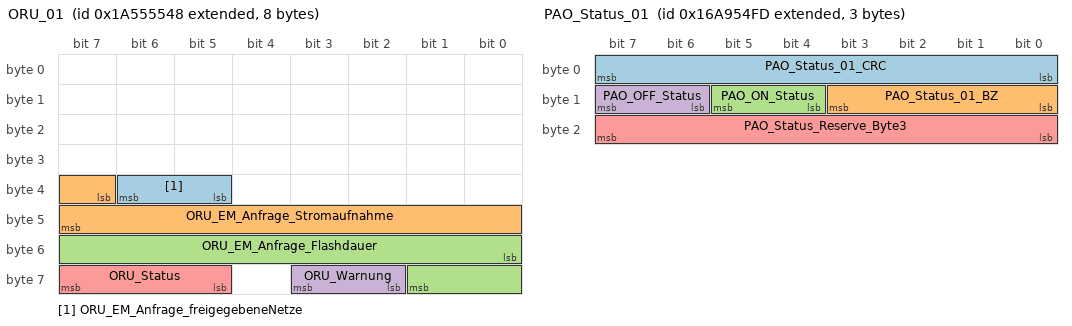
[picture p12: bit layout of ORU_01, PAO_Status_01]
BO_ 2589283656 ORU_01: 8 ICAS1_Gateway
 SG_ ORU_EM_Anfrage_freigegebeneNetze  : 37|2@1+ (1.000000,0.000000) [0.000000|3.000000] "" Vector__XXX
 SG_ ORU_EM_Anfrage_Stromaufnahme  : 39|9@1+ (0.100000,0.000000) [0.000000|51.100000] "Unit_Amper" Vector__XXX
 SG_ ORU_EM_Anfrage_Flashdauer  : 48|10@1+ (10.000000,0.000000) [0.000000|10230.000000] "Unit_Secon" Vector__XXX
 SG_ ORU_Warnung  : 58|2@1+ (1.000000,0.000000) [0.000000|3.000000] "" Vector__XXX
 SG_ ORU_Status  : 61|3@1+ (1.000000,0.000000) [0.000000|7.000000] "" Airbag LE1 LE2 Motor_BEV

BO_ 2527679741 PAO_Status_01: 3 ICAS1_Gateway
 SG_ PAO_Status_01_CRC  : 0|8@1+ (1.000000,0.000000) [0.000000|255.000000] "" Airbag
 SG_ PAO_Status_01_BZ  : 8|4@1+ (1.000000,0.000000) [0.000000|15.000000] "" Airbag
 SG_ PAO_ON_Status  : 12|2@1+ (1.000000,0.000000) [0.000000|3.000000] "" Airbag
 SG_ PAO_OFF_Status  : 14|2@1+ (1.000000,0.000000) [0.000000|3.000000] "" Airbag
 SG_ PAO_Status_Reserve_Byte3  : 16|8@1+ (1.000000,0.000000) [0.000000|255.000000] "" Vector__XXX

BO_ 518 Parken_01: 24 ICAS1_Gateway
 SG_ Parken_BKD_Anf  : 12|4@1+ (0.100000,0.000000) [0.000000|1.300000] "Unit_Secon" Vector__XXX
 SG_ Parken_Verz_Anf  : 16|7@1+ (0.100000,-12.600000) [-12.600000|-0.100000] "Unit_MeterPerSeconSquar" Vector__XXX
 SG_ Parken_Prefill_Anf  : 23|1@1+ (1.000000,0.000000) [0.000000|1.000000] "" Vector__XXX
 SG_ Parken_Warnruck_Anf  : 24|2@1+ (1.000000,0.000000) [0.000000|3.000000] "" Vector__XXX
 SG_ Parken_Verz_Anf_ASIL  : 26|2@1+ (1.000000,0.000000) [0.000000|3.000000] "" Vector__XXX
 SG_ Parken_Warnruckeln_Anf  : 28|2@1+ (1.000000,0.000000) [0.000000|3.000000] "" Vector__XXX
 SG_ Parken_beibehalten  : 30|2@1+ (1.000000,0.000000) [0.000000|3.000000] "" Vector__XXX
 SG_ Parken_Anforderung_HMS  : 32|3@1+ (1.000000,0.000000) [0.000000|7.000000] "" Vector__XXX
 SG_ Parken_Notstopp_Anf  : 40|2@1+ (1.000000,0.000000) [0.000000|3.000000] "" Vector__XXX
 SG_ Parken_Anhalteweg_Anf  : 42|10@1+ (0.010000,0.000000) [0.000000|10.210000] "Unit_Meter" Vector__XXX
 SG_ Parken_aktives_System  : 52|4@1+ (1.000000,0.000000) [0.000000|15.000000] "" Motor_BEV
 SG_ Parken_max_Beschleunigung  : 56|7@1+ (0.100000,-6.000000) [-5.900000|6.100000] "Unit_MeterPerSeconSquar" Motor_BEV
 SG_ Parken_Blinker_li_Anf  : 63|1@1+ (1.000000,0.000000) [0.000000|1.000000] "" Vector__XXX
 SG_ Parken_QFK_KruemmSoll  : 64|15@1+ (0.000007,0.000000) [0.000000|0.219539] "Unit_MeterInver" Vector__XXX
 SG_ Parken_QFK_KruemmSoll_VZ  : 79|1@1+ (1.000000,0.000000) [0.000000|1.000000] "" Vector__XXX
 SG_ Parken_QFK_Spuerb  : 80|8@1+ (0.400000,0.000000) [0.000000|100.000000] "Unit_PerCent" Vector__XXX
 SG_ Parken_QFK_AnfStat  : 88|4@1+ (1.000000,0.000000) [0.000000|15.000000] "" Vector__XXX
 SG_ Parken_QFK_Signal1  : 92|10@1+ (1.000000,0.000000) [0.000000|1023.000000] "" Vector__XXX
 SG_ Parken_QFK_Art1  : 102|3@1+ (1.000000,0.000000) [0.000000|7.000000] "" Vector__XXX
 SG_ Parken_QFK_Art2  : 105|3@1+ (1.000000,0.000000) [0.000000|7.000000] "" Vector__XXX
 SG_ Parken_QFK_Signal2  : 108|10@1+ (1.000000,0.000000) [0.000000|1023.000000] "" Vector__XXX
 SG_ Parken_Sollbeschleunigung  : 118|9@1+ (0.010000,-4.110000) [-4.100000|1.000000] "Unit_MeterPerSeconSquar" Motor_BEV
 SG_ Parken_Blinker_re_Anf  : 127|1@1+ (1.000000,0.000000) [0.000000|1.000000] "" Vector__XXX
 SG_ Parken_Status_IPA_TSK  : 128|4@1+ (1.000000,0.000000) [0.000000|15.000000] "" Motor_BEV
 SG_ Parken_erhoehtes_Moment  : 132|4@1+ (1.000000,0.000000) [0.000000|15.000000] "" Motor_BEV
 SG_ Parken_max_Geschwindigkeit  : 136|8@1+ (0.100000,0.000000) [0.100000|25.000000] "Unit_KiloMeterPerHour" Motor_BEV
 SG_ Parken_Soll_Anhalteweg_Anf  : 144|10@1+ (0.010000,0.000000) [0.000000|10.210000] "Unit_Meter" Vector__XXX
 SG_ Parken_Fahrstufenwunsch  : 154|3@1+ (1.000000,0.000000) [0.000000|7.000000] "" Motor_BEV
 SG_ IPA_TPA_Remote  : 157|2@1+ (1.000000,0.000000) [0.000000|3.000000] "" Vector__XXX
 SG_ IPA_TPA_Remote_Anf  : 159|1@1+ (1.000000,0.000000) [0.000000|1.000000] "" Vector__XXX
 SG_ IPA_TPA_Fehler  : 160|4@1+ (1.000000,0.000000) [0.000000|15.000000] "" Vector__XXX
 SG_ IPA_TPA_Abbruch  : 164|4@1+ (1.000000,0.000000) [0.000000|15.000000] "" Vector__XXX
 SG_ IPA_TPA_Status  : 168|4@1+ (1.000000,0.000000) [0.000000|15.000000] "" Vector__XXX

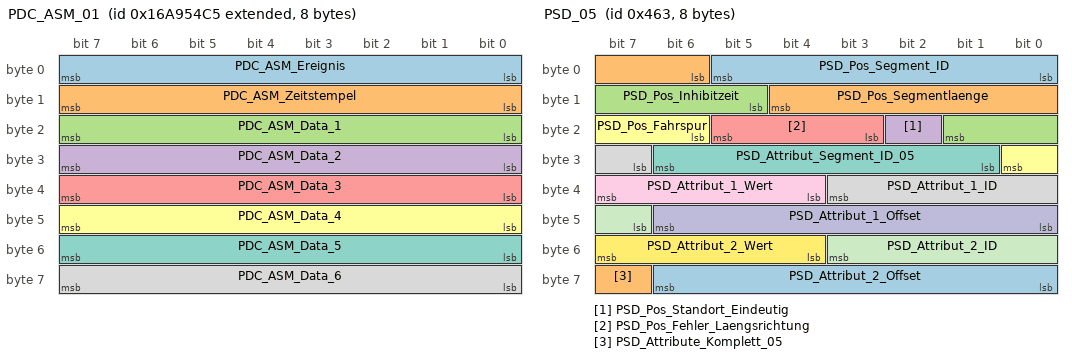
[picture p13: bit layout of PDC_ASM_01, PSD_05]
BO_ 2527679685 PDC_ASM_01: 8 ICAS1_Gateway
 SG_ PDC_ASM_Ereignis  : 0|8@1+ (1.000000,0.000000) [1.000000|254.000000] "" Airbag
 SG_ PDC_ASM_Zeitstempel  : 8|8@1+ (0.080000,0.000000) [0.000000|20.320000] "Unit_Secon" Airbag
 SG_ PDC_ASM_Data_1  : 16|8@1+ (1.000000,0.000000) [0.000000|255.000000] "" Airbag
 SG_ PDC_ASM_Data_2  : 24|8@1+ (1.000000,0.000000) [0.000000|255.000000] "" Airbag
 SG_ PDC_ASM_Data_3  : 32|8@1+ (1.000000,0.000000) [0.000000|255.000000] "" Airbag
 SG_ PDC_ASM_Data_4  : 40|8@1+ (1.000000,0.000000) [0.000000|255.000000] "" Airbag
 SG_ PDC_ASM_Data_5  : 48|8@1+ (1.000000,0.000000) [0.000000|255.000000] "" Airbag
 SG_ PDC_ASM_Data_6  : 56|8@1+ (1.000000,0.000000) [0.000000|255.000000] "" Airbag

BO_ 319 PreCrash_02: 8 Airbag
 SG_ PreCrash_Charisma_FahrPr  : 12|4@1+ (1.000000,0.000000) [0.000000|15.000000] "" ICAS1_Gateway
 SG_ PreCrash_Charisma_Status  : 16|2@1+ (1.000000,0.000000) [0.000000|3.000000] "" ICAS1_Gateway
 SG_ PreCrash_Schiebedach_schliessen  : 18|1@1+ (1.000000,0.000000) [0.000000|1.000000] "" ICAS1_Gateway
 SG_ PreCrash_Fenster_schliessen  : 19|1@1+ (1.000000,0.000000) [0.000000|1.000000] "" ICAS1_Gateway
 SG_ PreCrash_Blinken  : 20|3@1+ (1.000000,0.000000) [0.000000|7.000000] "" ICAS1_Gateway
 SG_ SC_PreSense_FCWP  : 23|1@1+ (1.000000,0.000000) [0.000000|1.000000] "" ICAS1_Gateway
 SG_ PreCrash_Tueren_Verriegeln  : 24|1@1+ (1.000000,0.000000) [0.000000|1.000000] "" ICAS1_Gateway
 SG_ PreCrash_FS_Laengsverstellung  : 25|1@1+ (1.000000,0.000000) [0.000000|1.000000] "" ICAS1_Gateway
 SG_ PreCrash_Anforderung_AFR  : 26|3@1+ (1.000000,0.000000) [0.000000|7.000000] "" ICAS1_Gateway
 SG_ SC_PreCrash_LED  : 29|2@1+ (1.000000,0.000000) [0.000000|3.000000] "" ICAS1_Gateway
 SG_ PreCrash_FS_Pneumatik_ansteuern  : 31|1@1+ (1.000000,0.000000) [0.000000|1.000000] "" ICAS1_Gateway
 SG_ PreCrash_BFS_Pneumatik_ansteuern  : 32|1@1+ (1.000000,0.000000) [0.000000|1.000000] "" ICAS1_Gateway
 SG_ PreCrash_Fo_Pneumatik_ansteuern  : 33|1@1+ (1.000000,0.000000) [0.000000|1.000000] "" ICAS1_Gateway
 SG_ PreCrash_FS_Sitzlehne_verfahren  : 34|3@1+ (1.000000,0.000000) [0.000000|7.000000] "" ICAS1_Gateway
 SG_ PreCrash_BFS_Sitzlehne_verfahren  : 37|3@1+ (1.000000,0.000000) [0.000000|7.000000] "" ICAS1_Gateway
 SG_ PreCrash_Fo_Sitzlehne_verfahren  : 40|3@1+ (1.000000,0.000000) [0.000000|7.000000] "" ICAS1_Gateway
 SG_ PreCrash_FS_KSV_verfahren  : 43|4@1+ (1.000000,0.000000) [0.000000|15.000000] "" ICAS1_Gateway
 SG_ PreCrash_BFS_KSV_verfahren  : 47|4@1+ (1.000000,0.000000) [0.000000|15.000000] "" ICAS1_Gateway
 SG_ PreCrash_Fo_KSV_verfahren  : 51|4@1+ (1.000000,0.000000) [0.000000|15.000000] "" ICAS1_Gateway
 SG_ PreCrash_BFS_Laengsverstellung  : 55|1@1+ (1.000000,0.000000) [0.000000|1.000000] "" ICAS1_Gateway
 SG_ SC_PreCrash_Warnung  : 56|4@1+ (1.000000,0.000000) [0.000000|15.000000] "" ICAS1_Gateway ICAS1_KommunikationsServer
 SG_ SC_PreCrash_Texte  : 60|4@1+ (1.000000,0.000000) [0.000000|15.000000] "" ICAS1_Gateway ICAS1_KommunikationsServer

BO_ 1122 PSD_04: 8 ICAS1_Gateway
 SG_ PSD_Segment_ID  : 0|6@1+ (1.000000,0.000000) [2.000000|63.000000] "" Motor_BEV
 SG_ PSD_Vorgaenger_Segment_ID  : 6|6@1+ (1.000000,0.000000) [2.000000|63.000000] "" Motor_BEV
 SG_ PSD_Segmentlaenge  : 12|7@1+ (2.000000,0.000000) [0.000000|254.000000] "Unit_Meter" Motor_BEV
 SG_ PSD_Strassenkategorie  : 19|3@1+ (1.000000,0.000000) [0.000000|7.000000] "" Motor_BEV
 SG_ PSD_Endkruemmung  : 22|8@1+ (1.000000,0.000000) [0.000000|254.000000] "Unit_None" Motor_BEV
 SG_ PSD_Endkruemmung_Vorz  : 30|1@1+ (1.000000,0.000000) [0.000000|1.000000] "" Motor_BEV
 SG_ PSD_Idenditaets_ID  : 31|6@1+ (1.000000,0.000000) [2.000000|63.000000] "" Vector__XXX
 SG_ PSD_ADAS_Qualitaet  : 37|1@1+ (1.000000,0.000000) [0.000000|1.000000] "" Motor_BEV
 SG_ PSD_wahrscheinlichster_Pfad  : 38|1@1+ (1.000000,0.000000) [0.000000|1.000000] "" Motor_BEV
 SG_ PSD_Geradester_Pfad  : 39|1@1+ (1.000000,0.000000) [0.000000|1.000000] "" Motor_BEV
 SG_ PSD_Fahrspuren_Anzahl  : 40|3@1+ (1.000000,0.000000) [0.000000|7.000000] "" Motor_BEV
 SG_ PSD_Bebauung  : 43|1@1+ (1.000000,0.000000) [0.000000|1.000000] "" Motor_BEV
 SG_ PSD_Segment_Komplett  : 44|1@1+ (1.000000,0.000000) [0.000000|1.000000] "" Motor_BEV
 SG_ PSD_Rampe  : 45|2@1+ (1.000000,0.000000) [0.000000|3.000000] "" Motor_BEV
 SG_ PSD_Anfangskruemmung  : 47|8@1+ (1.000000,0.000000) [0.000000|254.000000] "" Motor_BEV
 SG_ PSD_Anfangskruemmung_Vorz  : 55|1@1+ (1.000000,0.000000) [0.000000|1.000000] "" Motor_BEV
 SG_ PSD_Abzweigerichtung  : 56|1@1+ (1.000000,0.000000) [0.000000|1.000000] "" Motor_BEV
 SG_ PSD_Abzweigewinkel  : 57|7@1+ (1.417323,0.000000) [0.000000|180.000021] "" Motor_BEV

BO_ 1123 PSD_05: 8 ICAS1_Gateway
 SG_ PSD_Pos_Segment_ID  : 0|6@1+ (1.000000,0.000000) [2.000000|63.000000] "" Motor_BEV
 SG_ PSD_Pos_Segmentlaenge  : 6|7@1+ (2.000000,0.000000) [0.000000|254.000000] "Unit_Meter" Motor_BEV
 SG_ PSD_Pos_Inhibitzeit  : 13|5@1+ (10.000000,0.000000) [0.000000|310.000000] "Unit_MilliSecon" Motor_BEV
 SG_ PSD_Pos_Standort_Eindeutig  : 18|1@1+ (1.000000,0.000000) [0.000000|1.000000] "" Motor_BEV
 SG_ PSD_Pos_Fehler_Laengsrichtung  : 19|3@1+ (1.000000,0.000000) [0.000000|7.000000] "" Motor_BEV
 SG_ PSD_Pos_Fahrspur  : 22|3@1+ (1.000000,0.000000) [0.000000|7.000000] "" Motor_BEV
 SG_ PSD_Attribut_Segment_ID_05  : 25|6@1+ (1.000000,0.000000) [2.000000|63.000000] "" Motor_BEV
 SG_ PSD_Attribut_1_ID  : 31|5@1+ (1.000000,0.000000) [1.000000|31.000000] "" Motor_BEV
 SG_ PSD_Attribut_1_Wert  : 36|4@1+ (1.000000,0.000000) [0.000000|15.000000] "" Motor_BEV
 SG_ PSD_Attribut_1_Offset  : 40|7@1+ (2.000000,0.000000) [0.000000|254.000000] "Unit_Meter" Motor_BEV
 SG_ PSD_Attribut_2_ID  : 47|5@1+ (1.000000,0.000000) [1.000000|31.000000] "" Motor_BEV
 SG_ PSD_Attribut_2_Wert  : 52|4@1+ (1.000000,0.000000) [0.000000|15.000000] "" Motor_BEV
 SG_ PSD_Attribut_2_Offset  : 56|7@1+ (2.000000,0.000000) [0.000000|254.000000] "Unit_Meter" Motor_BEV
 SG_ PSD_Attribute_Komplett_05  : 63|1@1+ (1.000000,0.000000) [0.000000|1.000000] "" Motor_BEV

BO_ 1124 PSD_06: 8 ICAS1_Gateway
 SG_ PSD_06_Mux M : 0|3@1+ (1.000000,0.000000) [0.000000|7.000000] "" Motor_BEV
 SG_ PSD_Sys_Segment_ID m0 : 3|6@1+ (1.000000,0.000000) [2.000000|63.000000] "" Motor_BEV
 SG_ PSD_Attribut_Segment_ID m1 : 3|6@1+ (1.000000,0.000000) [2.000000|63.000000] "" Motor_BEV
 SG_ PSD_Ges_Segment_ID m2 : 3|6@1+ (1.000000,0.000000) [2.000000|63.000000] "" Motor_BEV
 SG_ PSD_Baum_Laenge_VZ m3 : 3|1@1+ (1.000000,0.000000) [0.000000|1.000000] "" Motor_BEV
 SG_ PSD_Steigung_1_Segment_ID m4 : 3|6@1+ (1.000000,0.000000) [2.000000|63.000000] "" Motor_BEV
 SG_ PSD_Baum_Laenge m3 : 4|25@1+ (0.000010,0.000000) [0.000000|180.000000] "Unit_DegreOfArc" Motor_BEV
 SG_ PSD_Sys_Laendercode m0 : 9|8@1+ (1.000000,0.000000) [0.000000|255.000000] "" Motor_BEV
 SG_ PSD_Attribut_3_ID m1 : 9|5@1+ (1.000000,0.000000) [1.000000|31.000000] "" Motor_BEV
 SG_ PSD_Ges_Offset m2 : 9|7@1+ (2.000000,0.000000) [0.000000|254.000000] "Unit_Meter" Motor_BEV
 SG_ PSD_Steigung_1_A_Steigung m4 : 9|7@1+ (0.120000,0.000000) [0.000000|15.000000] "Unit_PerCent" Motor_BEV
 SG_ PSD_Attribut_3_Offset m1 : 14|7@1+ (2.000000,0.000000) [0.000000|254.000000] "Unit_Meter" Motor_BEV
 SG_ PSD_Ges_Geschwindigkeit m2 : 16|5@1+ (1.000000,0.000000) [0.000000|31.000000] "" Motor_BEV
 SG_ PSD_Steigung_1_A_Vorz m4 : 16|1@1+ (1.000000,0.000000) [0.000000|1.000000] "" Motor_BEV
 SG_ PSD_Sys_Geschwindigkeit_Einheit m0 : 17|1@1+ (1.000000,0.000000) [0.000000|1.000000] "" Motor_BEV
 SG_ PSD_Steigung_1_A_Offset m4 : 17|7@1+ (2.000000,0.000000) [0.000000|254.000000] "Unit_Meter" Motor_BEV
 SG_ PSD_Sys_Verkehrsrichtung m0 : 18|1@1+ (1.000000,0.000000) [0.000000|1.000000] "" Motor_BEV
 SG_ PSD_Sys_Geometrieguete m0 : 19|2@1+ (1.000000,0.000000) [0.000000|3.000000] "" Motor_BEV
 SG_ PSD_Sys_Mapmatchingguete m0 : 21|2@1+ (1.000000,0.000000) [0.000000|3.000000] "" Motor_BEV
 SG_ PSD_Attribut_3_Wert m1 : 21|4@1+ (1.000000,0.000000) [0.000000|15.000000] "" Motor_BEV
 SG_ PSD_Ges_Typ m2 : 21|2@1+ (1.000000,0.000000) [0.000000|3.000000] "" Motor_BEV
 SG_ PSD_Sys_Alter_Karte m0 : 23|3@1+ (1.000000,0.000000) [0.000000|7.000000] "" Motor_BEV
 SG_ PSD_Ges_Spur_Geschw_Begrenzung m2 : 23|6@1+ (1.000000,0.000000) [0.000000|63.000000] "" Motor_BEV
 SG_ PSD_Steigung_1_B_Steigung m4 : 24|7@1+ (0.120000,0.000000) [0.000000|15.000000] "Unit_PerCent" Motor_BEV
 SG_ PSD_Attribut_4_ID m1 : 25|5@1+ (1.000000,0.000000) [1.000000|31.000000] "" Motor_BEV
 SG_ PSD_Sys_Zielfuehrung m0 : 26|1@1+ (1.000000,0.000000) [0.000000|1.000000] "" Motor_BEV
 SG_ PSD_Sys_US_State m0 : 27|6@1+ (1.000000,0.000000) [0.000000|63.000000] "" Motor_BEV
 SG_ PSD_Ges_Geschwindigkeit_Gespann m2 : 29|2@1+ (1.000000,0.000000) [0.000000|3.000000] "" Motor_BEV
 SG_ PSD_Baum_Breite_VZ m3 : 29|1@1+ (1.000000,0.000000) [0.000000|1.000000] "" Motor_BEV
 SG_ PSD_Attribut_4_Wert m1 : 30|4@1+ (1.000000,0.000000) [0.000000|15.000000] "" Motor_BEV
 SG_ PSD_Baum_Breite m3 : 30|24@1+ (0.000010,0.000000) [0.000000|90.000000] "Unit_DegreOfArc" Motor_BEV
 SG_ PSD_Ges_Geschwindigkeit_Witter m2 : 31|2@1+ (1.000000,0.000000) [0.000000|3.000000] "" Motor_BEV
 SG_ PSD_Steigung_1_B_Vorz m4 : 31|1@1+ (1.000000,0.000000) [0.000000|1.000000] "" Motor_BEV
 SG_ PSD_Steigung_1_B_Offset m4 : 32|7@1+ (2.000000,0.000000) [0.000000|254.000000] "Unit_Meter" Motor_BEV
 SG_ PSD_Sys_Quali_Geometrien m0 : 33|3@1+ (1.000000,0.000000) [0.000000|7.000000] "Unit_None" Vector__XXX
 SG_ PSD_Ges_Geschwindigkeit_Tag_Anf m2 : 33|3@1+ (1.000000,0.000000) [0.000000|7.000000] "" Motor_BEV
 SG_ PSD_Attribut_4_Offset m1 : 34|7@1+ (2.000000,0.000000) [0.000000|254.000000] "Unit_Meter" Motor_BEV
 SG_ PSD_Sys_Quali_Ortsinfo m0 : 36|2@1+ (1.000000,0.000000) [0.000000|3.000000] "Unit_None" Vector__XXX
 SG_ PSD_Ges_Geschwindigkeit_Tag_Ende m2 : 36|3@1+ (1.000000,0.000000) [0.000000|7.000000] "" Motor_BEV
 SG_ PSD_Sys_Quali_verfuegbar m0 : 38|1@1+ (1.000000,0.000000) [0.000000|1.000000] "" Vector__XXX
 SG_ PSD_Sys_Zielfuehrung_geaendert m0 : 39|1@1+ (1.000000,0.000000) [0.000000|1.000000] "" Motor_BEV
 SG_ PSD_Ges_Geschwindigkeit_Std_Anf m2 : 39|5@1+ (1.000000,0.000000) [0.000000|24.000000] "Unit_Hours" Motor_BEV
 SG_ PSD_Steigung_1_Attribute_kompl m4 : 39|1@1+ (1.000000,0.000000) [0.000000|1.000000] "" Motor_BEV
 SG_ PSD_Sys_Geometrieguete_erweitert m0 : 40|8@1+ (1.000000,0.000000) [0.000000|255.000000] "" Vector__XXX
 SG_ PSD_Steigung_2_Segment_ID m4 : 40|6@1+ (1.000000,0.000000) [2.000000|63.000000] "" Motor_BEV
 SG_ PSD_Attribut_5_ID m1 : 41|5@1+ (1.000000,0.000000) [1.000000|31.000000] "" Motor_BEV
 SG_ PSD_Ges_Geschwindigkeit_Std_Ende m2 : 44|5@1+ (1.000000,0.000000) [0.000000|24.000000] "Unit_Hours" Motor_BEV
 SG_ PSD_Attribut_5_Offset m1 : 46|7@1+ (2.000000,0.000000) [0.000000|254.000000] "Unit_Meter" Motor_BEV
 SG_ PSD_Steigung_2_Steigung m4 : 46|7@1+ (0.120000,0.000000) [0.000000|15.000000] "Unit_PerCent" Motor_BEV
 SG_ PSD_Sys_Quali_sonstige_Attribute m0 : 48|3@1+ (1.000000,0.000000) [0.000000|7.000000] "Unit_None" Vector__XXX
 SG_ PSD_Ges_Ueberholverbot m2 : 49|2@1+ (1.000000,0.000000) [0.000000|3.000000] "" Vector__XXX
 SG_ PSD_Sys_Quali_Steigungen m0 : 51|3@1+ (1.000000,0.000000) [0.000000|7.000000] "" Vector__XXX
 SG_ PSD_Ges_Wechselverkehrszeichen m2 : 51|3@1+ (1.000000,0.000000) [0.000000|7.000000] "" Vector__XXX
 SG_ PSD_Attribut_5_Wert m1 : 53|4@1+ (1.000000,0.000000) [0.000000|15.000000] "" Motor_BEV
 SG_ PSD_Steigung_2_Vorz m4 : 53|1@1+ (1.000000,0.000000) [0.000000|1.000000] "" Motor_BEV
 SG_ PSD_Sys_Quali_Strassenkennz m0 : 54|3@1+ (1.000000,0.000000) [0.000000|7.000000] "Unit_None" Vector__XXX
 SG_ PSD_Wechselverkehrszeichen_Typ m2 : 54|2@1+ (1.000000,0.000000) [0.000000|3.000000] "" Vector__XXX
 SG_ PSD_Baum_Ausrichtung m3 : 54|10@1+ (0.351562,0.000000) [0.000000|359.648438] "Unit_DegreOfArc" Vector__XXX
 SG_ PSD_Steigung_2_Offset m4 : 54|7@1+ (2.000000,0.000000) [0.000000|254.000000] "Unit_Meter" Motor_BEV
 SG_ PSD_Ges_Gesetzlich_Kategorie m2 : 56|3@1+ (1.000000,0.000000) [0.000000|7.000000] "" Motor_BEV
 SG_ PSD_Sys_Quali_Tempolimits m0 : 57|3@1+ (1.000000,0.000000) [0.000000|7.000000] "Unit_None" Vector__XXX
 SG_ PSD_Attribute_Komplett_06 m1 : 57|1@1+ (1.000000,0.000000) [0.000000|1.000000] "" Motor_BEV
 SG_ PSD_Ges_Gesetzlich_Zusatz m2 : 59|2@1+ (1.000000,0.000000) [0.000000|3.000000] "" Motor_BEV
 SG_ PSD_Sys_Quali_Vorfahrtsregelung m0 : 60|3@1+ (1.000000,0.000000) [0.000000|7.000000] "Unit_None" Vector__XXX
 SG_ PSD_Ges_Verkehrszeichen_Quelle m2 : 61|2@1+ (1.000000,0.000000) [0.000000|3.000000] "" Motor_BEV
 SG_ PSD_Steigung_2_Attribute_kompl m4 : 61|1@1+ (1.000000,0.000000) [0.000000|1.000000] "" Motor_BEV
 SG_ PSD_Ges_Attribute_Komplett m2 : 63|1@1+ (1.000000,0.000000) [0.000000|1.000000] "" Motor_BEV

BO_ 591 RDR1_Objekte_02: 64 ICAS1_Gateway
 SG_ RDR1_relevanter_Fehler  : 12|1@1+ (1.000000,0.000000) [0.000000|1.000000] "" Motor_BEV
 SG_ RDR1_Blindheit_erkannt  : 13|1@1+ (1.000000,0.000000) [0.000000|1.000000] "" Motor_BEV
 SG_ RDR1_relev_Nichtverfuegbarkeit  : 14|1@1+ (1.000000,0.000000) [0.000000|1.000000] "" Motor_BEV
 SG_ RDR1_Obj_01_Nummer  : 16|6@1+ (1.000000,0.000000) [0.000000|63.000000] "" Vector__XXX
 SG_ RDR1_Obj_02_Nummer  : 22|6@1+ (1.000000,0.000000) [0.000000|63.000000] "" Vector__XXX
 SG_ RDR1_Obj_03_Nummer  : 28|6@1+ (1.000000,0.000000) [0.000000|63.000000] "" Vector__XXX
 SG_ RDR1_Obj_04_Nummer  : 34|6@1+ (1.000000,0.000000) [0.000000|63.000000] "" Vector__XXX
 SG_ RDR1_Obj_05_Nummer  : 40|6@1+ (1.000000,0.000000) [0.000000|63.000000] "" Vector__XXX
 SG_ RDR1_Obj_06_Nummer  : 46|6@1+ (1.000000,0.000000) [0.000000|63.000000] "" Vector__XXX
 SG_ RDR1_Verkehrssinn  : 52|2@1+ (1.000000,0.000000) [0.000000|3.000000] "" Vector__XXX
 SG_ RDR1_Objekte_02_Datenalter  : 54|10@1+ (0.000977,0.000000) [0.000000|0.998047] "Unit_Secon" Vector__XXX
 SG_ RDR1_Obj_01_dx_v  : 64|12@1+ (0.062500,0.000000) [0.000000|255.937500] "Unit_Meter" Motor_BEV
 SG_ RDR1_Obj_01_dy_v  : 76|10@1+ (0.062500,-32.000000) [-32.000000|31.937500] "Unit_Meter" Motor_BEV
 SG_ RDR1_Obj_01_vx_v  : 86|10@1+ (0.250000,-128.000000) [-128.000000|127.750000] "Unit_MeterPerSecon" Motor_BEV
 SG_ RDR1_Obj_02_dx_v  : 96|12@1+ (0.062500,0.000000) [0.000000|255.937500] "Unit_Meter" Vector__XXX
 SG_ RDR1_Obj_02_dy_v  : 108|10@1+ (0.062500,-32.000000) [-32.000000|31.937500] "Unit_Meter" Vector__XXX
 SG_ RDR1_Obj_02_vx_v  : 118|10@1+ (0.250000,-128.000000) [-128.000000|127.750000] "Unit_MeterPerSecon" Vector__XXX
 SG_ RDR1_Obj_03_dx_v  : 128|12@1+ (0.062500,0.000000) [0.000000|255.937500] "Unit_Meter" Vector__XXX
 SG_ RDR1_Obj_03_dy_v  : 140|10@1+ (0.062500,-32.000000) [-32.000000|31.937500] "Unit_Meter" Vector__XXX
 SG_ RDR1_Obj_03_vx_v  : 150|10@1+ (0.250000,-128.000000) [-128.000000|127.750000] "Unit_MeterPerSecon" Vector__XXX
 SG_ RDR1_Obj_04_dx_v  : 160|12@1+ (0.062500,0.000000) [0.000000|255.937500] "Unit_Meter" Motor_BEV
 SG_ RDR1_Obj_04_dy_v  : 172|10@1+ (0.062500,-32.000000) [-32.000000|31.937500] "Unit_Meter" Vector__XXX
 SG_ RDR1_Obj_04_vx_v  : 182|10@1+ (0.250000,-128.000000) [-128.000000|127.750000] "Unit_MeterPerSecon" Motor_BEV
 SG_ RDR1_Obj_05_dx_v  : 192|12@1+ (0.062500,0.000000) [0.000000|255.937500] "Unit_Meter" Vector__XXX
 SG_ RDR1_Obj_05_dy_v  : 204|10@1+ (0.062500,-32.000000) [-32.000000|31.937500] "Unit_Meter" Vector__XXX
 SG_ RDR1_Obj_05_vx_v  : 214|10@1+ (0.250000,-128.000000) [-128.000000|127.750000] "Unit_MeterPerSecon" Vector__XXX
 SG_ RDR1_Obj_06_dx_v  : 224|12@1+ (0.062500,0.000000) [0.000000|255.937500] "Unit_Meter" Vector__XXX
 SG_ RDR1_Obj_06_dy_v  : 236|10@1+ (0.062500,-32.000000) [-32.000000|31.937500] "Unit_Meter" Vector__XXX
 SG_ RDR1_Obj_06_vx_v  : 246|10@1+ (0.250000,-128.000000) [-128.000000|127.750000] "Unit_MeterPerSecon" Vector__XXX
 SG_ RDR1_Obj_01_ax_v  : 256|8@1+ (0.125000,-16.000000) [-16.000000|15.750000] "Unit_MeterPerSeconSquar" Motor_BEV
 SG_ RDR1_Obj_01_ax_StdA  : 264|6@1+ (0.125000,0.000000) [0.000000|7.750000] "Unit_MeterPerSeconSquar" Motor_BEV
 SG_ RDR1_Obj_01_vx_StdA  : 270|7@1+ (0.031250,0.000000) [0.000000|3.937500] "Unit_MeterPerSecon" Motor_BEV
 SG_ RDR1_Obj_01_dx_StdA  : 277|7@1+ (0.050000,0.000000) [0.000000|6.300000] "Unit_Meter" Motor_BEV
 SG_ RDR1_Obj_01_dy_StdA  : 284|7@1+ (0.062500,0.000000) [0.000000|7.875000] "Unit_Meter" Motor_BEV

BO_ 2033 Request_Airbag_Deployment: 8 ICAS1_Gateway
 SG_ Request_Airbag_Deployment  : 0|64@1+ (1.000000,0.000000) [0.000000|18446744073709551616.000000] "" Airbag

BO_ 2041 Response_Airbag_Deployment: 8 Airbag
 SG_ Response_Airbag_Deployment  : 0|64@1+ (1.000000,0.000000) [0.000000|18446744073709551616.000000] "" ICAS1_Gateway

BU_:  Airbag BAP_Tester ICAS1_Gateway ICAS1_KommunikationsServer LE1 LE2 Motor_BEV Schaltbetaetigung

BO_ 2463978709 OCC_02: 32 ICAS1_Gateway
 SG_ OCC_CP_Tastgrad_A  : 12|10@1+ (0.100000,0.000000) [0.000000|100.000000] "Unit_PerCent" Vector__XXX
 SG_ OCC_CP_Tastgrad_B  : 22|10@1+ (0.100000,0.000000) [0.000000|100.000000] "Unit_PerCent" Vector__XXX
 SG_ OCC_CP_Frequenz_A  : 32|8@1+ (1.000000,880.000000) [880.000000|1132.000000] "Unit_Hertz" Vector__XXX
 SG_ OCC_CP_Frequenz_B  : 40|8@1+ (1.000000,880.000000) [880.000000|1132.000000] "Unit_Hertz" Vector__XXX
 SG_ OCC_CP_Spannung_A  : 48|9@1+ (0.100000,-25.000000) [-25.000000|25.900000] "Unit_Volt" Vector__XXX
 SG_ OCC_CP_Spannung_B  : 57|9@1+ (0.100000,-25.000000) [-25.000000|25.900000] "Unit_Volt" Vector__XXX
 SG_ OCC_CP_Fehlerstatus_A  : 66|3@1+ (1.000000,0.000000) [0.000000|7.000000] "" Vector__XXX
 SG_ OCC_CP_Fehlerstatus_B  : 69|3@1+ (1.000000,0.000000) [0.000000|7.000000] "" Vector__XXX
 SG_ OCC_Temp_Ladedose_A_AC  : 72|8@1+ (1.000000,-40.000000) [-40.000000|213.000000] "Unit_DegreCelsi" Vector__XXX
 SG_ OCC_Temp_Ladedose_A_DC_minus  : 80|8@1+ (1.000000,-40.000000) [-40.000000|213.000000] "Unit_DegreCelsi" Vector__XXX
 SG_ OCC_Temp_Ladedose_A_DC_plus  : 88|8@1+ (1.000000,-40.000000) [-40.000000|213.000000] "Unit_DegreCelsi" Vector__XXX
 SG_ OCC_U_istAC_Netz_L1  : 96|9@1+ (1.000000,0.000000) [0.000000|509.000000] "Unit_Volt" Vector__XXX
 SG_ OCC_U_istAC_Netz_L2  : 105|9@1+ (1.000000,0.000000) [0.000000|509.000000] "Unit_Volt" Vector__XXX
 SG_ OCC_U_istAC_Netz_L3  : 114|9@1+ (1.000000,0.000000) [0.000000|508.000000] "Unit_Volt" Vector__XXX
 SG_ OCC_StatusVerEntriegelungAktor_A  : 123|3@1+ (1.000000,0.000000) [0.000000|7.000000] "" Vector__XXX
 SG_ OCC_SteckerEntriegelung_Verbot_A  : 126|2@1+ (1.000000,0.000000) [0.000000|3.000000] "" Vector__XXX
 SG_ OCC_StatusVerEntriegelungAktor_B  : 128|3@1+ (1.000000,0.000000) [0.000000|7.000000] "" Vector__XXX
 SG_ OCC_SteckerEntriegelung_Verbot_B  : 131|2@1+ (1.000000,0.000000) [0.000000|3.000000] "" Vector__XXX
 SG_ OCC_Verriegelung_Status_A  : 133|3@1+ (1.000000,0.000000) [0.000000|7.000000] "" Vector__XXX
 SG_ OCC_Verriegelung_Status_B  : 136|3@1+ (1.000000,0.000000) [0.000000|7.000000] "" Vector__XXX
 SG_ OCC_RtmWarnLadeKommunikation  : 139|3@1+ (1.000000,0.000000) [0.000000|7.000000] "" Vector__XXX
 SG_ OCC_Ist_Wirkungsgrad  : 145|7@1+ (1.000000,0.000000) [0.000000|100.000000] "Unit_PerCent" Vector__XXX
 SG_ OCC_PP_Max_Strom_A  : 152|4@1+ (1.000000,0.000000) [0.000000|15.000000] "" Vector__XXX
 SG_ OCC_PP_Max_Strom_B  : 156|4@1+ (1.000000,0.000000) [0.000000|15.000000] "" Vector__XXX
 SG_ OCC_DC_MaxStrom  : 160|11@1+ (0.100000,0.000000) [0.000000|204.500000] "Unit_Amper" Vector__XXX
 SG_ OCC_Derating_Temperatur  : 171|1@1+ (1.000000,0.000000) [0.000000|1.000000] "" Vector__XXX
 SG_ OCC_Fehlerzustand  : 172|1@1+ (1.000000,0.000000) [0.000000|1.000000] "" Vector__XXX
 SG_ OCC_Ladest_Entriegelungs_Verbot  : 173|3@1+ (1.000000,0.000000) [0.000000|7.000000] "" Vector__XXX
 SG_ OCC_Netzfrequenz_EVU  : 176|9@1+ (0.100000,40.000000) [40.000000|80.000000] "Unit_Hertz" Vector__XXX
 SG_ OCC_Warnzustand  : 185|1@1+ (1.000000,0.000000) [0.000000|1.000000] "" Vector__XXX
 SG_ OCC_Kuehltemperatur  : 192|8@1+ (1.000000,-40.000000) [-40.000000|213.000000] "Unit_DegreCelsi" Motor_BEV
 SG_ OCC_PP_Fehlerstatus_A  : 200|4@1+ (1.000000,0.000000) [0.000000|15.000000] "" Vector__XXX
 SG_ OCC_PP_Fehlerstatus_B  : 204|4@1+ (1.000000,0.000000) [0.000000|15.000000] "" Vector__XXX

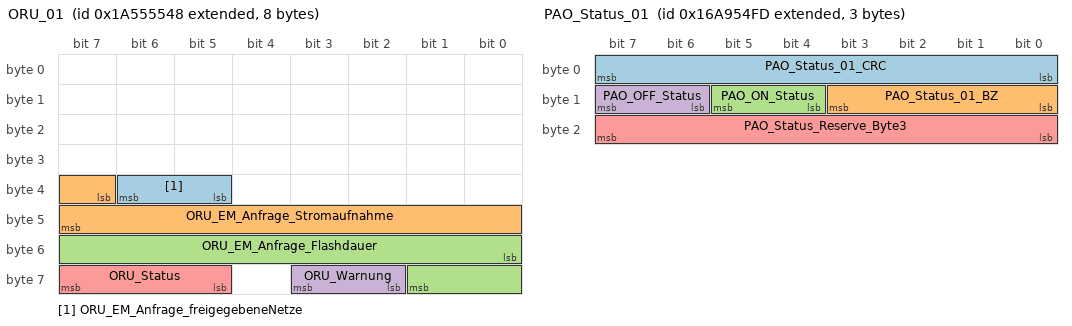
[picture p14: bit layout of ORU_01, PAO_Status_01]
BO_ 2589283656 ORU_01: 8 ICAS1_Gateway
 SG_ ORU_EM_Anfrage_freigegebeneNetze  : 37|2@1+ (1.000000,0.000000) [0.000000|3.000000] "" Vector__XXX
 SG_ ORU_EM_Anfrage_Stromaufnahme  : 39|9@1+ (0.100000,0.000000) [0.000000|51.100000] "Unit_Amper" Vector__XXX
 SG_ ORU_EM_Anfrage_Flashdauer  : 48|10@1+ (10.000000,0.000000) [0.000000|10230.000000] "Unit_Secon" Vector__XXX
 SG_ ORU_Warnung  : 58|2@1+ (1.000000,0.000000) [0.000000|3.000000] "" Vector__XXX
 SG_ ORU_Status  : 61|3@1+ (1.000000,0.000000) [0.000000|7.000000] "" Airbag LE1 LE2 Motor_BEV

BO_ 2527679741 PAO_Status_01: 3 ICAS1_Gateway
 SG_ PAO_Status_01_CRC  : 0|8@1+ (1.000000,0.000000) [0.000000|255.000000] "" Airbag
 SG_ PAO_Status_01_BZ  : 8|4@1+ (1.000000,0.000000) [0.000000|15.000000] "" Airbag
 SG_ PAO_ON_Status  : 12|2@1+ (1.000000,0.000000) [0.000000|3.000000] "" Airbag
 SG_ PAO_OFF_Status  : 14|2@1+ (1.000000,0.000000) [0.000000|3.000000] "" Airbag
 SG_ PAO_Status_Reserve_Byte3  : 16|8@1+ (1.000000,0.000000) [0.000000|255.000000] "" Vector__XXX

BO_ 518 Parken_01: 24 ICAS1_Gateway
 SG_ Parken_BKD_Anf  : 12|4@1+ (0.100000,0.000000) [0.000000|1.300000] "Unit_Secon" Vector__XXX
 SG_ Parken_Verz_Anf  : 16|7@1+ (0.100000,-12.600000) [-12.600000|-0.100000] "Unit_MeterPerSeconSquar" Vector__XXX
 SG_ Parken_Prefill_Anf  : 23|1@1+ (1.000000,0.000000) [0.000000|1.000000] "" Vector__XXX
 SG_ Parken_Warnruck_Anf  : 24|2@1+ (1.000000,0.000000) [0.000000|3.000000] "" Vector__XXX
 SG_ Parken_Verz_Anf_ASIL  : 26|2@1+ (1.000000,0.000000) [0.000000|3.000000] "" Vector__XXX
 SG_ Parken_Warnruckeln_Anf  : 28|2@1+ (1.000000,0.000000) [0.000000|3.000000] "" Vector__XXX
 SG_ Parken_beibehalten  : 30|2@1+ (1.000000,0.000000) [0.000000|3.000000] "" Vector__XXX
 SG_ Parken_Anforderung_HMS  : 32|3@1+ (1.000000,0.000000) [0.000000|7.000000] "" Vector__XXX
 SG_ Parken_Notstopp_Anf  : 40|2@1+ (1.000000,0.000000) [0.000000|3.000000] "" Vector__XXX
 SG_ Parken_Anhalteweg_Anf  : 42|10@1+ (0.010000,0.000000) [0.000000|10.210000] "Unit_Meter" Vector__XXX
 SG_ Parken_aktives_System  : 52|4@1+ (1.000000,0.000000) [0.000000|15.000000] "" Motor_BEV
 SG_ Parken_max_Beschleunigung  : 56|7@1+ (0.100000,-6.000000) [-5.900000|6.100000] "Unit_MeterPerSeconSquar" Motor_BEV
 SG_ Parken_Blinker_li_Anf  : 63|1@1+ (1.000000,0.000000) [0.000000|1.000000] "" Vector__XXX
 SG_ Parken_QFK_KruemmSoll  : 64|15@1+ (0.000007,0.000000) [0.000000|0.219539] "Unit_MeterInver" Vector__XXX
 SG_ Parken_QFK_KruemmSoll_VZ  : 79|1@1+ (1.000000,0.000000) [0.000000|1.000000] "" Vector__XXX
 SG_ Parken_QFK_Spuerb  : 80|8@1+ (0.400000,0.000000) [0.000000|100.000000] "Unit_PerCent" Vector__XXX
 SG_ Parken_QFK_AnfStat  : 88|4@1+ (1.000000,0.000000) [0.000000|15.000000] "" Vector__XXX
 SG_ Parken_QFK_Signal1  : 92|10@1+ (1.000000,0.000000) [0.000000|1023.000000] "" Vector__XXX
 SG_ Parken_QFK_Art1  : 102|3@1+ (1.000000,0.000000) [0.000000|7.000000] "" Vector__XXX
 SG_ Parken_QFK_Art2  : 105|3@1+ (1.000000,0.000000) [0.000000|7.000000] "" Vector__XXX
 SG_ Parken_QFK_Signal2  : 108|10@1+ (1.000000,0.000000) [0.000000|1023.000000] "" Vector__XXX
 SG_ Parken_Sollbeschleunigung  : 118|9@1+ (0.010000,-4.110000) [-4.100000|1.000000] "Unit_MeterPerSeconSquar" Motor_BEV
 SG_ Parken_Blinker_re_Anf  : 127|1@1+ (1.000000,0.000000) [0.000000|1.000000] "" Vector__XXX
 SG_ Parken_Status_IPA_TSK  : 128|4@1+ (1.000000,0.000000) [0.000000|15.000000] "" Motor_BEV
 SG_ Parken_erhoehtes_Moment  : 132|4@1+ (1.000000,0.000000) [0.000000|15.000000] "" Motor_BEV
 SG_ Parken_max_Geschwindigkeit  : 136|8@1+ (0.100000,0.000000) [0.100000|25.000000] "Unit_KiloMeterPerHour" Motor_BEV
 SG_ Parken_Soll_Anhalteweg_Anf  : 144|10@1+ (0.010000,0.000000) [0.000000|10.210000] "Unit_Meter" Vector__XXX
 SG_ Parken_Fahrstufenwunsch  : 154|3@1+ (1.000000,0.000000) [0.000000|7.000000] "" Motor_BEV
 SG_ IPA_TPA_Remote  : 157|2@1+ (1.000000,0.000000) [0.000000|3.000000] "" Vector__XXX
 SG_ IPA_TPA_Remote_Anf  : 159|1@1+ (1.000000,0.000000) [0.000000|1.000000] "" Vector__XXX
 SG_ IPA_TPA_Fehler  : 160|4@1+ (1.000000,0.000000) [0.000000|15.000000] "" Vector__XXX
 SG_ IPA_TPA_Abbruch  : 164|4@1+ (1.000000,0.000000) [0.000000|15.000000] "" Vector__XXX
 SG_ IPA_TPA_Status  : 168|4@1+ (1.000000,0.000000) [0.000000|15.000000] "" Vector__XXX

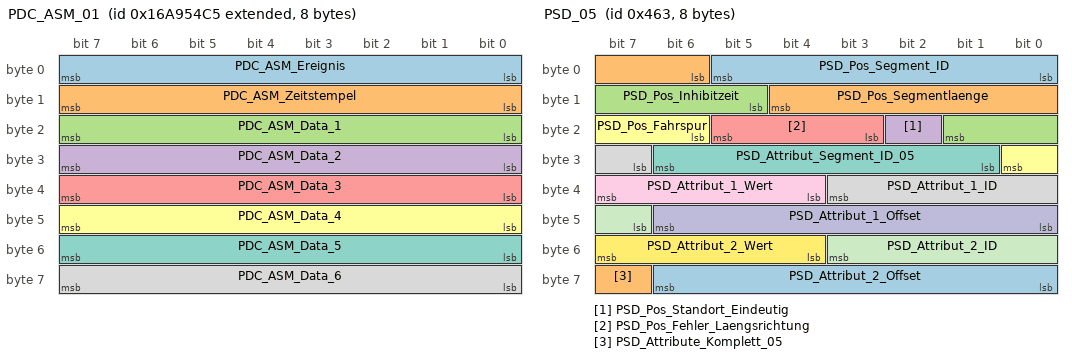
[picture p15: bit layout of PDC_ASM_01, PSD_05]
BO_ 2527679685 PDC_ASM_01: 8 ICAS1_Gateway
 SG_ PDC_ASM_Ereignis  : 0|8@1+ (1.000000,0.000000) [1.000000|254.000000] "" Airbag
 SG_ PDC_ASM_Zeitstempel  : 8|8@1+ (0.080000,0.000000) [0.000000|20.320000] "Unit_Secon" Airbag
 SG_ PDC_ASM_Data_1  : 16|8@1+ (1.000000,0.000000) [0.000000|255.000000] "" Airbag
 SG_ PDC_ASM_Data_2  : 24|8@1+ (1.000000,0.000000) [0.000000|255.000000] "" Airbag
 SG_ PDC_ASM_Data_3  : 32|8@1+ (1.000000,0.000000) [0.000000|255.000000] "" Airbag
 SG_ PDC_ASM_Data_4  : 40|8@1+ (1.000000,0.000000) [0.000000|255.000000] "" Airbag
 SG_ PDC_ASM_Data_5  : 48|8@1+ (1.000000,0.000000) [0.000000|255.000000] "" Airbag
 SG_ PDC_ASM_Data_6  : 56|8@1+ (1.000000,0.000000) [0.000000|255.000000] "" Airbag

BO_ 319 PreCrash_02: 8 Airbag
 SG_ PreCrash_Charisma_FahrPr  : 12|4@1+ (1.000000,0.000000) [0.000000|15.000000] "" ICAS1_Gateway
 SG_ PreCrash_Charisma_Status  : 16|2@1+ (1.000000,0.000000) [0.000000|3.000000] "" ICAS1_Gateway
 SG_ PreCrash_Schiebedach_schliessen  : 18|1@1+ (1.000000,0.000000) [0.000000|1.000000] "" ICAS1_Gateway
 SG_ PreCrash_Fenster_schliessen  : 19|1@1+ (1.000000,0.000000) [0.000000|1.000000] "" ICAS1_Gateway
 SG_ PreCrash_Blinken  : 20|3@1+ (1.000000,0.000000) [0.000000|7.000000] "" ICAS1_Gateway
 SG_ SC_PreSense_FCWP  : 23|1@1+ (1.000000,0.000000) [0.000000|1.000000] "" ICAS1_Gateway
 SG_ PreCrash_Tueren_Verriegeln  : 24|1@1+ (1.000000,0.000000) [0.000000|1.000000] "" ICAS1_Gateway
 SG_ PreCrash_FS_Laengsverstellung  : 25|1@1+ (1.000000,0.000000) [0.000000|1.000000] "" ICAS1_Gateway
 SG_ PreCrash_Anforderung_AFR  : 26|3@1+ (1.000000,0.000000) [0.000000|7.000000] "" ICAS1_Gateway
 SG_ SC_PreCrash_LED  : 29|2@1+ (1.000000,0.000000) [0.000000|3.000000] "" ICAS1_Gateway
 SG_ PreCrash_FS_Pneumatik_ansteuern  : 31|1@1+ (1.000000,0.000000) [0.000000|1.000000] "" ICAS1_Gateway
 SG_ PreCrash_BFS_Pneumatik_ansteuern  : 32|1@1+ (1.000000,0.000000) [0.000000|1.000000] "" ICAS1_Gateway
 SG_ PreCrash_Fo_Pneumatik_ansteuern  : 33|1@1+ (1.000000,0.000000) [0.000000|1.000000] "" ICAS1_Gateway
 SG_ PreCrash_FS_Sitzlehne_verfahren  : 34|3@1+ (1.000000,0.000000) [0.000000|7.000000] "" ICAS1_Gateway
 SG_ PreCrash_BFS_Sitzlehne_verfahren  : 37|3@1+ (1.000000,0.000000) [0.000000|7.000000] "" ICAS1_Gateway
 SG_ PreCrash_Fo_Sitzlehne_verfahren  : 40|3@1+ (1.000000,0.000000) [0.000000|7.000000] "" ICAS1_Gateway
 SG_ PreCrash_FS_KSV_verfahren  : 43|4@1+ (1.000000,0.000000) [0.000000|15.000000] "" ICAS1_Gateway
 SG_ PreCrash_BFS_KSV_verfahren  : 47|4@1+ (1.000000,0.000000) [0.000000|15.000000] "" ICAS1_Gateway
 SG_ PreCrash_Fo_KSV_verfahren  : 51|4@1+ (1.000000,0.000000) [0.000000|15.000000] "" ICAS1_Gateway
 SG_ PreCrash_BFS_Laengsverstellung  : 55|1@1+ (1.000000,0.000000) [0.000000|1.000000] "" ICAS1_Gateway
 SG_ SC_PreCrash_Warnung  : 56|4@1+ (1.000000,0.000000) [0.000000|15.000000] "" ICAS1_Gateway ICAS1_KommunikationsServer
 SG_ SC_PreCrash_Texte  : 60|4@1+ (1.000000,0.000000) [0.000000|15.000000] "" ICAS1_Gateway ICAS1_KommunikationsServer

BO_ 1122 PSD_04: 8 ICAS1_Gateway
 SG_ PSD_Segment_ID  : 0|6@1+ (1.000000,0.000000) [2.000000|63.000000] "" Motor_BEV
 SG_ PSD_Vorgaenger_Segment_ID  : 6|6@1+ (1.000000,0.000000) [2.000000|63.000000] "" Motor_BEV
 SG_ PSD_Segmentlaenge  : 12|7@1+ (2.000000,0.000000) [0.000000|254.000000] "Unit_Meter" Motor_BEV
 SG_ PSD_Strassenkategorie  : 19|3@1+ (1.000000,0.000000) [0.000000|7.000000] "" Motor_BEV
 SG_ PSD_Endkruemmung  : 22|8@1+ (1.000000,0.000000) [0.000000|254.000000] "Unit_None" Motor_BEV
 SG_ PSD_Endkruemmung_Vorz  : 30|1@1+ (1.000000,0.000000) [0.000000|1.000000] "" Motor_BEV
 SG_ PSD_Idenditaets_ID  : 31|6@1+ (1.000000,0.000000) [2.000000|63.000000] "" Vector__XXX
 SG_ PSD_ADAS_Qualitaet  : 37|1@1+ (1.000000,0.000000) [0.000000|1.000000] "" Motor_BEV
 SG_ PSD_wahrscheinlichster_Pfad  : 38|1@1+ (1.000000,0.000000) [0.000000|1.000000] "" Motor_BEV
 SG_ PSD_Geradester_Pfad  : 39|1@1+ (1.000000,0.000000) [0.000000|1.000000] "" Motor_BEV
 SG_ PSD_Fahrspuren_Anzahl  : 40|3@1+ (1.000000,0.000000) [0.000000|7.000000] "" Motor_BEV
 SG_ PSD_Bebauung  : 43|1@1+ (1.000000,0.000000) [0.000000|1.000000] "" Motor_BEV
 SG_ PSD_Segment_Komplett  : 44|1@1+ (1.000000,0.000000) [0.000000|1.000000] "" Motor_BEV
 SG_ PSD_Rampe  : 45|2@1+ (1.000000,0.000000) [0.000000|3.000000] "" Motor_BEV
 SG_ PSD_Anfangskruemmung  : 47|8@1+ (1.000000,0.000000) [0.000000|254.000000] "" Motor_BEV
 SG_ PSD_Anfangskruemmung_Vorz  : 55|1@1+ (1.000000,0.000000) [0.000000|1.000000] "" Motor_BEV
 SG_ PSD_Abzweigerichtung  : 56|1@1+ (1.000000,0.000000) [0.000000|1.000000] "" Motor_BEV
 SG_ PSD_Abzweigewinkel  : 57|7@1+ (1.417323,0.000000) [0.000000|180.000021] "" Motor_BEV

BO_ 1123 PSD_05: 8 ICAS1_Gateway
 SG_ PSD_Pos_Segment_ID  : 0|6@1+ (1.000000,0.000000) [2.000000|63.000000] "" Motor_BEV
 SG_ PSD_Pos_Segmentlaenge  : 6|7@1+ (2.000000,0.000000) [0.000000|254.000000] "Unit_Meter" Motor_BEV
 SG_ PSD_Pos_Inhibitzeit  : 13|5@1+ (10.000000,0.000000) [0.000000|310.000000] "Unit_MilliSecon" Motor_BEV
 SG_ PSD_Pos_Standort_Eindeutig  : 18|1@1+ (1.000000,0.000000) [0.000000|1.000000] "" Motor_BEV
 SG_ PSD_Pos_Fehler_Laengsrichtung  : 19|3@1+ (1.000000,0.000000) [0.000000|7.000000] "" Motor_BEV
 SG_ PSD_Pos_Fahrspur  : 22|3@1+ (1.000000,0.000000) [0.000000|7.000000] "" Motor_BEV
 SG_ PSD_Attribut_Segment_ID_05  : 25|6@1+ (1.000000,0.000000) [2.000000|63.000000] "" Motor_BEV
 SG_ PSD_Attribut_1_ID  : 31|5@1+ (1.000000,0.000000) [1.000000|31.000000] "" Motor_BEV
 SG_ PSD_Attribut_1_Wert  : 36|4@1+ (1.000000,0.000000) [0.000000|15.000000] "" Motor_BEV
 SG_ PSD_Attribut_1_Offset  : 40|7@1+ (2.000000,0.000000) [0.000000|254.000000] "Unit_Meter" Motor_BEV
 SG_ PSD_Attribut_2_ID  : 47|5@1+ (1.000000,0.000000) [1.000000|31.000000] "" Motor_BEV
 SG_ PSD_Attribut_2_Wert  : 52|4@1+ (1.000000,0.000000) [0.000000|15.000000] "" Motor_BEV
 SG_ PSD_Attribut_2_Offset  : 56|7@1+ (2.000000,0.000000) [0.000000|254.000000] "Unit_Meter" Motor_BEV
 SG_ PSD_Attribute_Komplett_05  : 63|1@1+ (1.000000,0.000000) [0.000000|1.000000] "" Motor_BEV

BO_ 1124 PSD_06: 8 ICAS1_Gateway
 SG_ PSD_06_Mux M : 0|3@1+ (1.000000,0.000000) [0.000000|7.000000] "" Motor_BEV
 SG_ PSD_Sys_Segment_ID m0 : 3|6@1+ (1.000000,0.000000) [2.000000|63.000000] "" Motor_BEV
 SG_ PSD_Attribut_Segment_ID m1 : 3|6@1+ (1.000000,0.000000) [2.000000|63.000000] "" Motor_BEV
 SG_ PSD_Ges_Segment_ID m2 : 3|6@1+ (1.000000,0.000000) [2.000000|63.000000] "" Motor_BEV
 SG_ PSD_Baum_Laenge_VZ m3 : 3|1@1+ (1.000000,0.000000) [0.000000|1.000000] "" Motor_BEV
 SG_ PSD_Steigung_1_Segment_ID m4 : 3|6@1+ (1.000000,0.000000) [2.000000|63.000000] "" Motor_BEV
 SG_ PSD_Baum_Laenge m3 : 4|25@1+ (0.000010,0.000000) [0.000000|180.000000] "Unit_DegreOfArc" Motor_BEV
 SG_ PSD_Sys_Laendercode m0 : 9|8@1+ (1.000000,0.000000) [0.000000|255.000000] "" Motor_BEV
 SG_ PSD_Attribut_3_ID m1 : 9|5@1+ (1.000000,0.000000) [1.000000|31.000000] "" Motor_BEV
 SG_ PSD_Ges_Offset m2 : 9|7@1+ (2.000000,0.000000) [0.000000|254.000000] "Unit_Meter" Motor_BEV
 SG_ PSD_Steigung_1_A_Steigung m4 : 9|7@1+ (0.120000,0.000000) [0.000000|15.000000] "Unit_PerCent" Motor_BEV
 SG_ PSD_Attribut_3_Offset m1 : 14|7@1+ (2.000000,0.000000) [0.000000|254.000000] "Unit_Meter" Motor_BEV
 SG_ PSD_Ges_Geschwindigkeit m2 : 16|5@1+ (1.000000,0.000000) [0.000000|31.000000] "" Motor_BEV
 SG_ PSD_Steigung_1_A_Vorz m4 : 16|1@1+ (1.000000,0.000000) [0.000000|1.000000] "" Motor_BEV
 SG_ PSD_Sys_Geschwindigkeit_Einheit m0 : 17|1@1+ (1.000000,0.000000) [0.000000|1.000000] "" Motor_BEV
 SG_ PSD_Steigung_1_A_Offset m4 : 17|7@1+ (2.000000,0.000000) [0.000000|254.000000] "Unit_Meter" Motor_BEV
 SG_ PSD_Sys_Verkehrsrichtung m0 : 18|1@1+ (1.000000,0.000000) [0.000000|1.000000] "" Motor_BEV
 SG_ PSD_Sys_Geometrieguete m0 : 19|2@1+ (1.000000,0.000000) [0.000000|3.000000] "" Motor_BEV
 SG_ PSD_Sys_Mapmatchingguete m0 : 21|2@1+ (1.000000,0.000000) [0.000000|3.000000] "" Motor_BEV
 SG_ PSD_Attribut_3_Wert m1 : 21|4@1+ (1.000000,0.000000) [0.000000|15.000000] "" Motor_BEV
 SG_ PSD_Ges_Typ m2 : 21|2@1+ (1.000000,0.000000) [0.000000|3.000000] "" Motor_BEV
 SG_ PSD_Sys_Alter_Karte m0 : 23|3@1+ (1.000000,0.000000) [0.000000|7.000000] "" Motor_BEV
 SG_ PSD_Ges_Spur_Geschw_Begrenzung m2 : 23|6@1+ (1.000000,0.000000) [0.000000|63.000000] "" Motor_BEV
 SG_ PSD_Steigung_1_B_Steigung m4 : 24|7@1+ (0.120000,0.000000) [0.000000|15.000000] "Unit_PerCent" Motor_BEV
 SG_ PSD_Attribut_4_ID m1 : 25|5@1+ (1.000000,0.000000) [1.000000|31.000000] "" Motor_BEV
 SG_ PSD_Sys_Zielfuehrung m0 : 26|1@1+ (1.000000,0.000000) [0.000000|1.000000] "" Motor_BEV
 SG_ PSD_Sys_US_State m0 : 27|6@1+ (1.000000,0.000000) [0.000000|63.000000] "" Motor_BEV
 SG_ PSD_Ges_Geschwindigkeit_Gespann m2 : 29|2@1+ (1.000000,0.000000) [0.000000|3.000000] "" Motor_BEV
 SG_ PSD_Baum_Breite_VZ m3 : 29|1@1+ (1.000000,0.000000) [0.000000|1.000000] "" Motor_BEV
 SG_ PSD_Attribut_4_Wert m1 : 30|4@1+ (1.000000,0.000000) [0.000000|15.000000] "" Motor_BEV
 SG_ PSD_Baum_Breite m3 : 30|24@1+ (0.000010,0.000000) [0.000000|90.000000] "Unit_DegreOfArc" Motor_BEV
 SG_ PSD_Ges_Geschwindigkeit_Witter m2 : 31|2@1+ (1.000000,0.000000) [0.000000|3.000000] "" Motor_BEV
 SG_ PSD_Steigung_1_B_Vorz m4 : 31|1@1+ (1.000000,0.000000) [0.000000|1.000000] "" Motor_BEV
 SG_ PSD_Steigung_1_B_Offset m4 : 32|7@1+ (2.000000,0.000000) [0.000000|254.000000] "Unit_Meter" Motor_BEV
 SG_ PSD_Sys_Quali_Geometrien m0 : 33|3@1+ (1.000000,0.000000) [0.000000|7.000000] "Unit_None" Vector__XXX
 SG_ PSD_Ges_Geschwindigkeit_Tag_Anf m2 : 33|3@1+ (1.000000,0.000000) [0.000000|7.000000] "" Motor_BEV
 SG_ PSD_Attribut_4_Offset m1 : 34|7@1+ (2.000000,0.000000) [0.000000|254.000000] "Unit_Meter" Motor_BEV
 SG_ PSD_Sys_Quali_Ortsinfo m0 : 36|2@1+ (1.000000,0.000000) [0.000000|3.000000] "Unit_None" Vector__XXX
 SG_ PSD_Ges_Geschwindigkeit_Tag_Ende m2 : 36|3@1+ (1.000000,0.000000) [0.000000|7.000000] "" Motor_BEV
 SG_ PSD_Sys_Quali_verfuegbar m0 : 38|1@1+ (1.000000,0.000000) [0.000000|1.000000] "" Vector__XXX
 SG_ PSD_Sys_Zielfuehrung_geaendert m0 : 39|1@1+ (1.000000,0.000000) [0.000000|1.000000] "" Motor_BEV
 SG_ PSD_Ges_Geschwindigkeit_Std_Anf m2 : 39|5@1+ (1.000000,0.000000) [0.000000|24.000000] "Unit_Hours" Motor_BEV
 SG_ PSD_Steigung_1_Attribute_kompl m4 : 39|1@1+ (1.000000,0.000000) [0.000000|1.000000] "" Motor_BEV
 SG_ PSD_Sys_Geometrieguete_erweitert m0 : 40|8@1+ (1.000000,0.000000) [0.000000|255.000000] "" Vector__XXX
 SG_ PSD_Steigung_2_Segment_ID m4 : 40|6@1+ (1.000000,0.000000) [2.000000|63.000000] "" Motor_BEV
 SG_ PSD_Attribut_5_ID m1 : 41|5@1+ (1.000000,0.000000) [1.000000|31.000000] "" Motor_BEV
 SG_ PSD_Ges_Geschwindigkeit_Std_Ende m2 : 44|5@1+ (1.000000,0.000000) [0.000000|24.000000] "Unit_Hours" Motor_BEV
 SG_ PSD_Attribut_5_Offset m1 : 46|7@1+ (2.000000,0.000000) [0.000000|254.000000] "Unit_Meter" Motor_BEV
 SG_ PSD_Steigung_2_Steigung m4 : 46|7@1+ (0.120000,0.000000) [0.000000|15.000000] "Unit_PerCent" Motor_BEV
 SG_ PSD_Sys_Quali_sonstige_Attribute m0 : 48|3@1+ (1.000000,0.000000) [0.000000|7.000000] "Unit_None" Vector__XXX
 SG_ PSD_Ges_Ueberholverbot m2 : 49|2@1+ (1.000000,0.000000) [0.000000|3.000000] "" Vector__XXX
 SG_ PSD_Sys_Quali_Steigungen m0 : 51|3@1+ (1.000000,0.000000) [0.000000|7.000000] "" Vector__XXX
 SG_ PSD_Ges_Wechselverkehrszeichen m2 : 51|3@1+ (1.000000,0.000000) [0.000000|7.000000] "" Vector__XXX
 SG_ PSD_Attribut_5_Wert m1 : 53|4@1+ (1.000000,0.000000) [0.000000|15.000000] "" Motor_BEV
 SG_ PSD_Steigung_2_Vorz m4 : 53|1@1+ (1.000000,0.000000) [0.000000|1.000000] "" Motor_BEV
 SG_ PSD_Sys_Quali_Strassenkennz m0 : 54|3@1+ (1.000000,0.000000) [0.000000|7.000000] "Unit_None" Vector__XXX
 SG_ PSD_Wechselverkehrszeichen_Typ m2 : 54|2@1+ (1.000000,0.000000) [0.000000|3.000000] "" Vector__XXX
 SG_ PSD_Baum_Ausrichtung m3 : 54|10@1+ (0.351562,0.000000) [0.000000|359.648438] "Unit_DegreOfArc" Vector__XXX
 SG_ PSD_Steigung_2_Offset m4 : 54|7@1+ (2.000000,0.000000) [0.000000|254.000000] "Unit_Meter" Motor_BEV
 SG_ PSD_Ges_Gesetzlich_Kategorie m2 : 56|3@1+ (1.000000,0.000000) [0.000000|7.000000] "" Motor_BEV
 SG_ PSD_Sys_Quali_Tempolimits m0 : 57|3@1+ (1.000000,0.000000) [0.000000|7.000000] "Unit_None" Vector__XXX
 SG_ PSD_Attribute_Komplett_06 m1 : 57|1@1+ (1.000000,0.000000) [0.000000|1.000000] "" Motor_BEV
 SG_ PSD_Ges_Gesetzlich_Zusatz m2 : 59|2@1+ (1.000000,0.000000) [0.000000|3.000000] "" Motor_BEV
 SG_ PSD_Sys_Quali_Vorfahrtsregelung m0 : 60|3@1+ (1.000000,0.000000) [0.000000|7.000000] "Unit_None" Vector__XXX
 SG_ PSD_Ges_Verkehrszeichen_Quelle m2 : 61|2@1+ (1.000000,0.000000) [0.000000|3.000000] "" Motor_BEV
 SG_ PSD_Steigung_2_Attribute_kompl m4 : 61|1@1+ (1.000000,0.000000) [0.000000|1.000000] "" Motor_BEV
 SG_ PSD_Ges_Attribute_Komplett m2 : 63|1@1+ (1.000000,0.000000) [0.000000|1.000000] "" Motor_BEV

BO_ 591 RDR1_Objekte_02: 64 ICAS1_Gateway
 SG_ RDR1_relevanter_Fehler  : 12|1@1+ (1.000000,0.000000) [0.000000|1.000000] "" Motor_BEV
 SG_ RDR1_Blindheit_erkannt  : 13|1@1+ (1.000000,0.000000) [0.000000|1.000000] "" Motor_BEV
 SG_ RDR1_relev_Nichtverfuegbarkeit  : 14|1@1+ (1.000000,0.000000) [0.000000|1.000000] "" Motor_BEV
 SG_ RDR1_Obj_01_Nummer  : 16|6@1+ (1.000000,0.000000) [0.000000|63.000000] "" Vector__XXX
 SG_ RDR1_Obj_02_Nummer  : 22|6@1+ (1.000000,0.000000) [0.000000|63.000000] "" Vector__XXX
 SG_ RDR1_Obj_03_Nummer  : 28|6@1+ (1.000000,0.000000) [0.000000|63.000000] "" Vector__XXX
 SG_ RDR1_Obj_04_Nummer  : 34|6@1+ (1.000000,0.000000) [0.000000|63.000000] "" Vector__XXX
 SG_ RDR1_Obj_05_Nummer  : 40|6@1+ (1.000000,0.000000) [0.000000|63.000000] "" Vector__XXX
 SG_ RDR1_Obj_06_Nummer  : 46|6@1+ (1.000000,0.000000) [0.000000|63.000000] "" Vector__XXX
 SG_ RDR1_Verkehrssinn  : 52|2@1+ (1.000000,0.000000) [0.000000|3.000000] "" Vector__XXX
 SG_ RDR1_Objekte_02_Datenalter  : 54|10@1+ (0.000977,0.000000) [0.000000|0.998047] "Unit_Secon" Vector__XXX
 SG_ RDR1_Obj_01_dx_v  : 64|12@1+ (0.062500,0.000000) [0.000000|255.937500] "Unit_Meter" Motor_BEV
 SG_ RDR1_Obj_01_dy_v  : 76|10@1+ (0.062500,-32.000000) [-32.000000|31.937500] "Unit_Meter" Motor_BEV
 SG_ RDR1_Obj_01_vx_v  : 86|10@1+ (0.250000,-128.000000) [-128.000000|127.750000] "Unit_MeterPerSecon" Motor_BEV
 SG_ RDR1_Obj_02_dx_v  : 96|12@1+ (0.062500,0.000000) [0.000000|255.937500] "Unit_Meter" Vector__XXX
 SG_ RDR1_Obj_02_dy_v  : 108|10@1+ (0.062500,-32.000000) [-32.000000|31.937500] "Unit_Meter" Vector__XXX
 SG_ RDR1_Obj_02_vx_v  : 118|10@1+ (0.250000,-128.000000) [-128.000000|127.750000] "Unit_MeterPerSecon" Vector__XXX
 SG_ RDR1_Obj_03_dx_v  : 128|12@1+ (0.062500,0.000000) [0.000000|255.937500] "Unit_Meter" Vector__XXX
 SG_ RDR1_Obj_03_dy_v  : 140|10@1+ (0.062500,-32.000000) [-32.000000|31.937500] "Unit_Meter" Vector__XXX
 SG_ RDR1_Obj_03_vx_v  : 150|10@1+ (0.250000,-128.000000) [-128.000000|127.750000] "Unit_MeterPerSecon" Vector__XXX
 SG_ RDR1_Obj_04_dx_v  : 160|12@1+ (0.062500,0.000000) [0.000000|255.937500] "Unit_Meter" Motor_BEV
 SG_ RDR1_Obj_04_dy_v  : 172|10@1+ (0.062500,-32.000000) [-32.000000|31.937500] "Unit_Meter" Vector__XXX
 SG_ RDR1_Obj_04_vx_v  : 182|10@1+ (0.250000,-128.000000) [-128.000000|127.750000] "Unit_MeterPerSecon" Motor_BEV
 SG_ RDR1_Obj_05_dx_v  : 192|12@1+ (0.062500,0.000000) [0.000000|255.937500] "Unit_Meter" Vector__XXX
 SG_ RDR1_Obj_05_dy_v  : 204|10@1+ (0.062500,-32.000000) [-32.000000|31.937500] "Unit_Meter" Vector__XXX
 SG_ RDR1_Obj_05_vx_v  : 214|10@1+ (0.250000,-128.000000) [-128.000000|127.750000] "Unit_MeterPerSecon" Vector__XXX
 SG_ RDR1_Obj_06_dx_v  : 224|12@1+ (0.062500,0.000000) [0.000000|255.937500] "Unit_Meter" Vector__XXX
 SG_ RDR1_Obj_06_dy_v  : 236|10@1+ (0.062500,-32.000000) [-32.000000|31.937500] "Unit_Meter" Vector__XXX
 SG_ RDR1_Obj_06_vx_v  : 246|10@1+ (0.250000,-128.000000) [-128.000000|127.750000] "Unit_MeterPerSecon" Vector__XXX
 SG_ RDR1_Obj_01_ax_v  : 256|8@1+ (0.125000,-16.000000) [-16.000000|15.750000] "Unit_MeterPerSeconSquar" Motor_BEV
 SG_ RDR1_Obj_01_ax_StdA  : 264|6@1+ (0.125000,0.000000) [0.000000|7.750000] "Unit_MeterPerSeconSquar" Motor_BEV
 SG_ RDR1_Obj_01_vx_StdA  : 270|7@1+ (0.031250,0.000000) [0.000000|3.937500] "Unit_MeterPerSecon" Motor_BEV
 SG_ RDR1_Obj_01_dx_StdA  : 277|7@1+ (0.050000,0.000000) [0.000000|6.300000] "Unit_Meter" Motor_BEV
 SG_ RDR1_Obj_01_dy_StdA  : 284|7@1+ (0.062500,0.000000) [0.000000|7.875000] "Unit_Meter" Motor_BEV

BO_ 2033 Request_Airbag_Deployment: 8 ICAS1_Gateway
 SG_ Request_Airbag_Deployment  : 0|64@1+ (1.000000,0.000000) [0.000000|18446744073709551616.000000] "" Airbag

BO_ 2041 Response_Airbag_Deployment: 8 Airbag
 SG_ Response_Airbag_Deployment  : 0|64@1+ (1.000000,0.000000) [0.000000|18446744073709551616.000000] "" ICAS1_Gateway
